VERSION ""

NS_ :

BS_:

BU_: WPC2 RLPSU DPSU APSU PSB SHVU_RR vHS_B2 FCS EMCU SLB ARS RCM CGW_CCU vDummy_HS_B ATS RLHV SGU PFSU ALBCU DSAU SWRC SHVU_FR RCS RRPSU BLTN_CAM SCM DLBCU OHCL RWPC RRHV WPC HOD ASAU

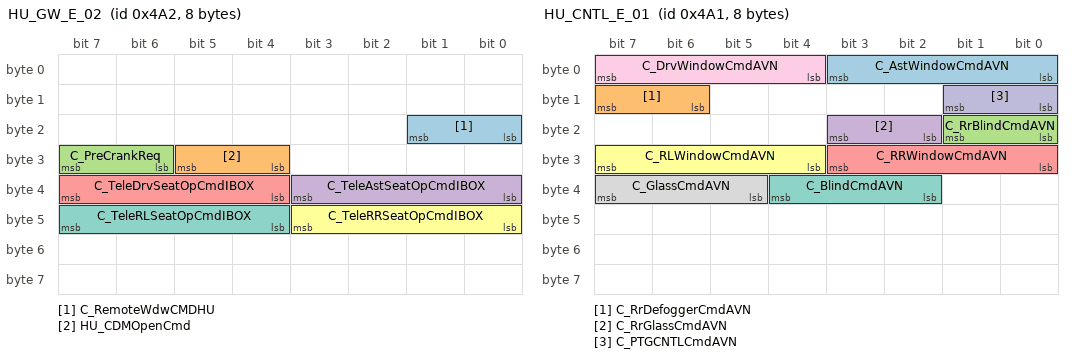
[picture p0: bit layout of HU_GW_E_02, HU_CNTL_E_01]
BO_ 1186 HU_GW_E_02: 8 CGW_CCU
 SG_ C_RemoteWdwCMDHU : 16|2@1+ (1,0) [0|0] ""  Vector__XXX
 SG_ HU_CDMOpenCmd : 28|2@1+ (1,0) [0|0] ""  Vector__XXX
 SG_ C_PreCrankReq : 30|2@1+ (1,0) [0|0] ""  BLTN_CAM
 SG_ C_TeleAstSeatOpCmdIBOX : 32|4@1+ (1,0) [0|0] ""  APSU,SHVU_FR
 SG_ C_TeleDrvSeatOpCmdIBOX : 36|4@1+ (1,0) [0|0] ""  SHVU_FR,DPSU
 SG_ C_TeleRRSeatOpCmdIBOX : 40|4@1+ (1,0) [0|0] ""  RRHV,SHVU_FR,SHVU_RR,RRPSU,RLPSU,ATS
 SG_ C_TeleRLSeatOpCmdIBOX : 44|4@1+ (1,0) [0|0] ""  RLHV,SHVU_FR,SHVU_RR,RRPSU,RLPSU,ATS

BO_ 1185 HU_CNTL_E_01: 8 CGW_CCU
 SG_ C_AstWindowCmdAVN : 0|4@1+ (1,0) [0|0] ""  Vector__XXX
 SG_ C_RrDefoggerCmdAVN : 14|2@1+ (1,0) [0|0] ""  Vector__XXX
 SG_ C_RrBlindCmdAVN : 16|2@1+ (1,0) [0|0] ""  RCM
 SG_ C_RrGlassCmdAVN : 18|2@1+ (1,0) [0|0] ""  RCM
 SG_ C_RRWindowCmdAVN : 24|4@1+ (1,0) [0|0] ""  Vector__XXX
 SG_ C_RLWindowCmdAVN : 28|4@1+ (1,0) [0|0] ""  Vector__XXX
 SG_ C_BlindCmdAVN : 34|3@1+ (1,0) [0|0] ""  RCM
 SG_ C_GlassCmdAVN : 37|3@1+ (1,0) [0|0] ""  RCM
 SG_ C_DrvWindowCmdAVN : 4|4@1+ (1,0) [0|0] ""  Vector__XXX
 SG_ C_PTGCNTLCmdAVN : 8|2@1+ (1,0) [0|0] ""  Vector__XXX

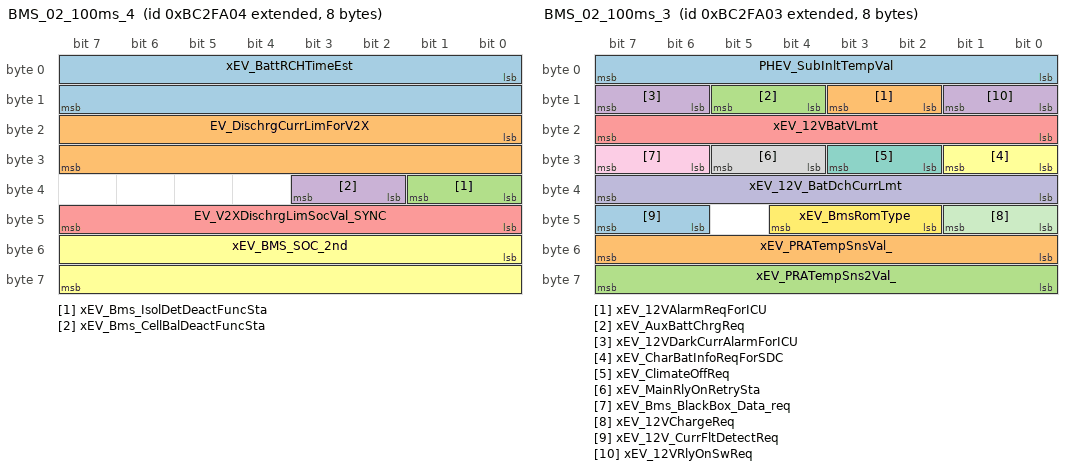
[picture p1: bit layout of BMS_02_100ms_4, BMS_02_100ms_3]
BO_ 2344811012 BMS_02_100ms_4: 8 CGW_CCU
 SG_ xEV_BattRCHTimeEst : 0|16@1+ (1,0) [0|0] "Min"  Vector__XXX
 SG_ EV_DischrgCurrLimForV2X : 16|16@1+ (0.1,0) [0|0] "A"  Vector__XXX
 SG_ xEV_Bms_IsolDetDeactFuncSta : 32|2@1+ (1,0) [0|0] "flg"  Vector__XXX
 SG_ xEV_Bms_CellBalDeactFuncSta : 34|2@1+ (1,0) [0|0] "flag"  Vector__XXX
 SG_ EV_V2XDischrgLimSocVal_SYNC : 40|8@1+ (0.5,0) [0|0] "%"  Vector__XXX
 SG_ xEV_BMS_SOC_2nd : 48|16@1+ (0.05,0) [0|0] "%"  Vector__XXX

BO_ 2344811011 BMS_02_100ms_3: 8 CGW_CCU
 SG_ PHEV_SubInltTempVal : 0|8@1- (1,0) [0|0] "¡É"  Vector__XXX
 SG_ xEV_12VAlarmReqForICU : 10|2@1+ (1,0) [0|0] ""  Vector__XXX
 SG_ xEV_AuxBattChrgReq : 12|2@1+ (1,0) [0|0] ""  Vector__XXX
 SG_ xEV_12VDarkCurrAlarmForICU : 14|2@1+ (1,0) [0|0] ""  Vector__XXX
 SG_ xEV_12VBatVLmt : 16|8@1+ (0.1,0) [0|0] "V"  Vector__XXX
 SG_ xEV_CharBatInfoReqForSDC : 24|2@1+ (1,0) [0|0] ""  Vector__XXX
 SG_ xEV_ClimateOffReq : 26|2@1+ (1,0) [0|0] ""  Vector__XXX
 SG_ xEV_MainRlyOnRetrySta : 28|2@1+ (1,0) [0|0] ""  Vector__XXX
 SG_ xEV_Bms_BlackBox_Data_req : 30|2@1+ (1,0) [0|0] ""  Vector__XXX
 SG_ xEV_12V_BatDchCurrLmt : 32|8@1+ (1,0) [0|0] "A"  Vector__XXX
 SG_ xEV_12VChargeReq : 40|2@1+ (1,0) [0|0] ""  Vector__XXX
 SG_ xEV_BmsRomType : 42|3@1+ (1,0) [0|0] ""  Vector__XXX
 SG_ xEV_12V_CurrFltDetectReq : 46|2@1+ (1,0) [0|0] ""  Vector__XXX
 SG_ xEV_PRATempSnsVal_ : 48|8@1- (2,0) [0|0] "¡É"  Vector__XXX
 SG_ xEV_PRATempSns2Val_ : 56|8@1- (2,0) [0|0] "¡É"  Vector__XXX
 SG_ xEV_12VRlyOnSwReq : 8|2@1+ (1,0) [0|0] ""  Vector__XXX

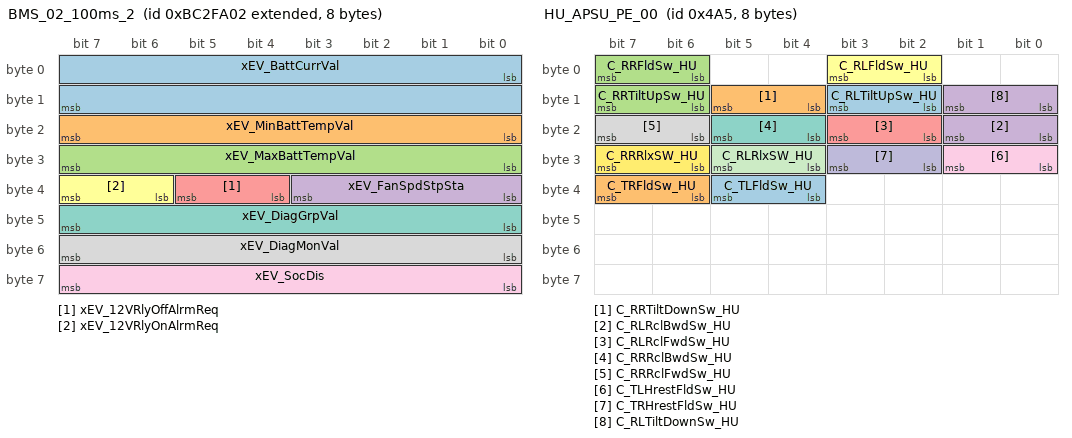
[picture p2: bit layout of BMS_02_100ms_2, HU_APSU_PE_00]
BO_ 2344811010 BMS_02_100ms_2: 8 CGW_CCU
 SG_ xEV_BattCurrVal : 0|16@1- (0.1,0) [0|0] "A"  Vector__XXX
 SG_ xEV_MinBattTempVal : 16|8@1- (1,0) [0|0] "¡É"  Vector__XXX
 SG_ xEV_MaxBattTempVal : 24|8@1- (1,0) [0|0] "¡É"  Vector__XXX
 SG_ xEV_FanSpdStpSta : 32|4@1+ (1,0) [0|0] "Step"  Vector__XXX
 SG_ xEV_12VRlyOffAlrmReq : 36|2@1+ (1,0) [0|0] ""  Vector__XXX
 SG_ xEV_12VRlyOnAlrmReq : 38|2@1+ (1,0) [0|0] ""  Vector__XXX
 SG_ xEV_DiagGrpVal : 40|8@1+ (1,0) [0|0] ""  Vector__XXX
 SG_ xEV_DiagMonVal : 48|8@1+ (1,0) [0|0] ""  Vector__XXX
 SG_ xEV_SocDis : 56|8@1+ (0.5,0) [0|0] "%"  SWRC

BO_ 1189 HU_APSU_PE_00: 8 CGW_CCU
 SG_ C_RLTiltUpSw_HU : 10|2@1+ (1,0) [0|0] ""  APSU,RRPSU,RLPSU
 SG_ C_RRTiltDownSw_HU : 12|2@1+ (1,0) [0|0] ""  APSU,RRPSU,RLPSU
 SG_ C_RRTiltUpSw_HU : 14|2@1+ (1,0) [0|0] ""  APSU,RRPSU,RLPSU
 SG_ C_RLRclBwdSw_HU : 16|2@1+ (1,0) [0|0] ""  APSU,RRPSU,RLPSU
 SG_ C_RLRclFwdSw_HU : 18|2@1+ (1,0) [0|0] ""  APSU,RRPSU,RLPSU
 SG_ C_RLFldSw_HU : 2|2@1+ (1,0) [0|0] ""  RLPSU
 SG_ C_RRRclBwdSw_HU : 20|2@1+ (1,0) [0|0] ""  APSU,RRPSU,RLPSU
 SG_ C_RRRclFwdSw_HU : 22|2@1+ (1,0) [0|0] ""  APSU,RRPSU,RLPSU
 SG_ C_TLHrestFldSw_HU : 24|2@1+ (1,0) [0|0] ""  PFSU
 SG_ C_TRHrestFldSw_HU : 26|2@1+ (1,0) [0|0] ""  PFSU
 SG_ C_RLRlxSW_HU : 28|2@1+ (1,0) [0|0] ""  RRPSU,RLPSU
 SG_ C_RRRlxSW_HU : 30|2@1+ (1,0) [0|0] ""  RRPSU
 SG_ C_TLFldSw_HU : 36|2@1+ (1,0) [0|0] ""  PFSU
 SG_ C_TRFldSw_HU : 38|2@1+ (1,0) [0|0] ""  PFSU
 SG_ C_RRFldSw_HU : 6|2@1+ (1,0) [0|0] ""  RRPSU
 SG_ C_RLTiltDownSw_HU : 8|2@1+ (1,0) [0|0] ""  APSU,RRPSU,RLPSU

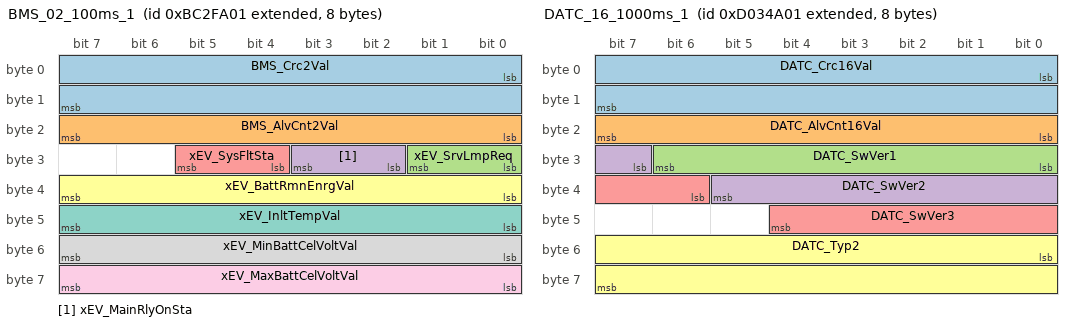
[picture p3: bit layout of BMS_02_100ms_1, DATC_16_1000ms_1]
BO_ 2344811009 BMS_02_100ms_1: 8 CGW_CCU
 SG_ BMS_Crc2Val : 0|16@1+ (1,0) [0|0] ""  Vector__XXX
 SG_ BMS_AlvCnt2Val : 16|8@1+ (1,0) [0|0] ""  Vector__XXX
 SG_ xEV_SrvLmpReq : 24|2@1+ (1,0) [0|0] ""  Vector__XXX
 SG_ xEV_MainRlyOnSta : 26|2@1+ (1,0) [0|0] ""  Vector__XXX
 SG_ xEV_SysFltSta : 28|2@1+ (1,0) [0|0] ""  Vector__XXX
 SG_ xEV_BattRmnEnrgVal : 32|8@1+ (1,0) [0|0] ""  Vector__XXX
 SG_ xEV_InltTempVal : 40|8@1- (1,0) [0|0] "¡É"  Vector__XXX
 SG_ xEV_MinBattCelVoltVal : 48|8@1+ (0.02,0) [0|0] "V"  Vector__XXX
 SG_ xEV_MaxBattCelVoltVal : 56|8@1+ (0.02,0) [0|0] "V"  Vector__XXX

BO_ 1195 HU_USM_E_04: 8 CGW_CCU
 SG_ CF_AVN_CluWelcomeSnd : 0|2@1+ (1,0) [0|0] ""  Vector__XXX
 SG_ CF_AVN_CluTransmissionDisp : 10|2@1+ (1,0) [0|0] ""  Vector__XXX
 SG_ CF_AVN_CluWiperLight : 12|2@1+ (1,0) [0|0] ""  Vector__XXX
 SG_ CF_AVN_CluRoadInfoGuide : 14|2@1+ (1,0) [0|0] ""  Vector__XXX
 SG_ CF_AVN_CluUserSettingPeriod : 17|7@1+ (1,0) [0|0] ""  Vector__XXX
 SG_ CF_AVN_CluAutoInitFuelEconomy : 2|3@1+ (1,0) [0|0] ""  Vector__XXX
 SG_ CF_AVN_CluFuelEconUnit_mi : 27|2@1+ (1,0) [0|0] ""  Vector__XXX
 SG_ CF_AVN_CluFuelEconUnit_km : 29|2@1+ (1,0) [0|0] ""  Vector__XXX
 SG_ CF_AVN_CluUserSettingDistance : 31|17@1+ (1,0) [0|0] ""  Vector__XXX
 SG_ CF_AVN_CluRheostatLvl : 49|5@1+ (1,0) [0|0] ""  Vector__XXX
 SG_ CF_AVN_CluVoiceVolume : 5|3@1+ (1,0) [0|0] ""  Vector__XXX
 SG_ CF_AVN_EVReset : 54|2@1+ (1,0) [0|0] ""  Vector__XXX
 SG_ CF_AVN_UnitReset : 56|2@1+ (1,0) [0|0] ""  Vector__XXX
 SG_ CF_AVN_IcyRoadWarn : 58|2@1+ (1,0) [0|0] ""  Vector__XXX
 SG_ CF_AVN_CluServiceReminderReset : 60|2@1+ (1,0) [0|0] ""  Vector__XXX
 SG_ CF_AVN_CluUSMReset : 62|2@1+ (1,0) [0|0] ""  WPC,RWPC,PSB,SLB,ARS,APSU,RLHV,RRHV,SHVU_FR,SHVU_RR,DPSU,DLBCU,PFSU,RRPSU,RLPSU,ATS,DSAU,ASAU,RCM,BLTN_CAM,ALBCU,WPC2
 SG_ CF_AVN_CluServiceReminderSet : 8|2@1+ (1,0) [0|0] ""  Vector__XXX

BO_ 1193 HU_USM_E_02: 8 CGW_CCU
 SG_ C_PTGMNValueSet : 0|2@1+ (1,0) [0|0] ""  Vector__XXX
 SG_ CF_AVN_PSMNValueSet : 10|3@1+ (1,0) [0|0] ""  DPSU
 SG_ C_HfreeTrunkTgNValueSet : 13|3@1+ (1,0) [0|0] ""  Vector__XXX
 SG_ CF_AVN_TrfChgSet : 17|2@1+ (1,0) [0|0] ""  Vector__XXX
 SG_ CF_AVN_SCMNValueSet : 19|2@1+ (1,0) [0|0] ""  Vector__XXX
 SG_ CF_AVN_ADrUNValueSet : 2|3@1+ (1,0) [0|0] ""  Vector__XXX
 SG_ CF_AVN_OTTurnNValueSet : 21|3@1+ (1,0) [0|0] ""  Vector__XXX
 SG_ CF_Gway_WPCNValueSet : 24|2@1+ (1,0) [0|0] ""  WPC,WPC2
 SG_ C_AVN_RearWiperNValueSet : 26|2@1+ (1,0) [0|0] ""  Vector__XXX
 SG_ C_UnlockWelocomeNValueSet : 28|2@1+ (1,0) [0|0] ""  Vector__XXX
 SG_ C_SmartWelocomeNValueSet : 30|2@1+ (1,0) [0|0] ""  Vector__XXX
 SG_ CF_AVN_PTGSpeedNValueSet : 32|2@1+ (1,0) [0|0] ""  Vector__XXX
 SG_ CR_Datc_DRSeatWheel_USM_Set : 34|2@1+ (1,0) [0|0] ""  Vector__XXX
 SG_ CF_AVN_TTUnlockNValueSet : 38|2@1+ (1,0) [0|0] ""  Vector__XXX
 SG_ CF_Gway_RWPCNValueSet : 40|2@1+ (1,0) [0|0] ""  RWPC
 SG_ C_PSDNValueSet : 44|2@1+ (1,0) [0|0] ""  Vector__XXX
 SG_ CF_Avn_HAPTICWARNINGNValueSet : 49|3@1+ (1,0) [0|0] ""  Vector__XXX
 SG_ CR_Datc_DRSeatHeat_USM_Set : 52|2@1+ (1,0) [0|0] ""  Vector__XXX
 SG_ C_WALNValueSet : 54|2@1+ (1,0) [0|0] ""  Vector__XXX
 SG_ C_ApprUnlockNValue : 56|2@1+ (1,0) [0|0] ""  Vector__XXX
 SG_ CF_AVN_EscortHLNValueSet : 8|2@1+ (1,0) [0|0] ""  Vector__XXX

BO_ 2365803012 DATC_16_1000ms_4: 8 CGW_CCU

BO_ 2365803011 DATC_16_1000ms_3: 8 CGW_CCU

BO_ 2365803010 DATC_16_1000ms_2: 8 CGW_CCU
 SG_ DATC_SwVer4 : 0|7@1+ (1,0) [0|0] ""  Vector__XXX
 SG_ DATC_SwVer5 : 7|7@1+ (1,0) [0|0] ""  Vector__XXX

BO_ 2365803009 DATC_16_1000ms_1: 8 CGW_CCU
 SG_ DATC_Crc16Val : 0|16@1+ (1,0) [0|0] ""  Vector__XXX
 SG_ DATC_AlvCnt16Val : 16|8@1+ (1,0) [0|0] ""  Vector__XXX
 SG_ DATC_SwVer1 : 24|7@1+ (1,0) [0|0] ""  Vector__XXX
 SG_ DATC_SwVer2 : 31|7@1+ (1,0) [0|0] ""  Vector__XXX
 SG_ DATC_SwVer3 : 38|7@1+ (1,0) [0|0] ""  Vector__XXX
 SG_ DATC_Typ2 : 48|16@1+ (1,0) [0|0] ""  ATS

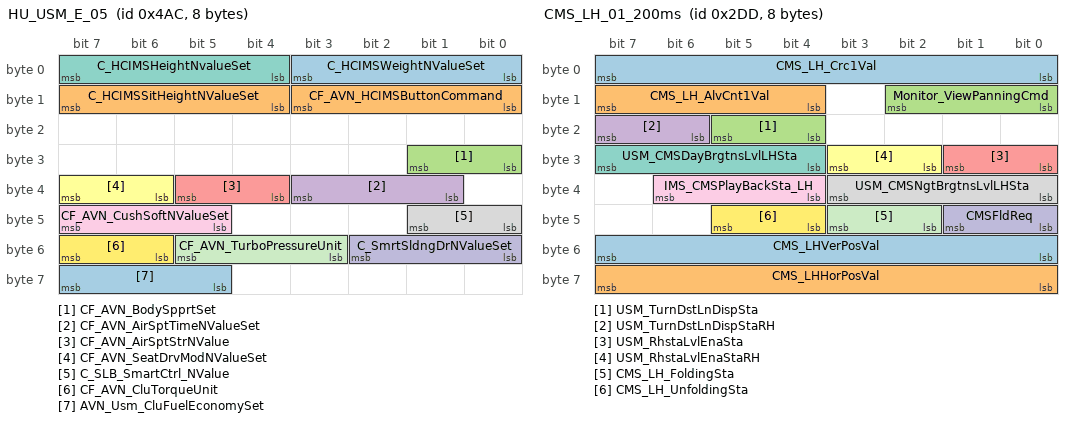
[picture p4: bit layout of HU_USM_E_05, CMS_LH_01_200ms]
BO_ 1196 HU_USM_E_05: 8 CGW_CCU
 SG_ C_HCIMSWeightNValueSet : 0|4@1+ (1,0) [0|0] ""  DPSU
 SG_ C_HCIMSSitHeightNValueSet : 12|4@1+ (1,0) [0|0] ""  DPSU
 SG_ CF_AVN_BodySpprtSet : 24|2@1+ (1,0) [0|0] ""  DLBCU,DSAU
 SG_ CF_AVN_AirSptTimeNValueSet : 33|3@1+ (1,0) [0|0] ""  DLBCU
 SG_ CF_AVN_AirSptStrNValue : 36|2@1+ (1,0) [0|0] ""  DLBCU
 SG_ CF_AVN_SeatDrvModNValueSet : 38|2@1+ (1,0) [0|0] ""  DLBCU,DSAU
 SG_ C_HCIMSHeightNvalueSet : 4|4@1+ (1,0) [0|0] ""  DPSU
 SG_ C_SLB_SmartCtrl_NValue : 40|2@1+ (1,0) [0|0] ""  Vector__XXX
 SG_ CF_AVN_CushSoftNValueSet : 45|3@1+ (1,0) [0|0] ""  DLBCU
 SG_ C_SmrtSldngDrNValueSet : 48|3@1+ (1,0) [0|0] ""  Vector__XXX
 SG_ CF_AVN_TurboPressureUnit : 51|3@1+ (1,0) [0|0] ""  Vector__XXX
 SG_ CF_AVN_CluTorqueUnit : 54|2@1+ (1,0) [0|0] ""  Vector__XXX
 SG_ AVN_Usm_CluFuelEconomySet : 61|3@1+ (1,0) [0|0] ""  Vector__XXX
 SG_ CF_AVN_HCIMSButtonCommand : 8|4@1+ (1,0) [0|0] ""  DPSU

BO_ 255 BCM_20_200ms: 8 CGW_CCU
 SG_ BCM_Crc20Val : 0|8@1+ (1,0) [0|0] ""  Vector__XXX
 SG_ BCM_AlvCnt20Val : 12|4@1+ (1,0) [0|0] ""  Vector__XXX
 SG_ BckGls_RrGlsHtdOnCmd : 16|2@1+ (1,0) [0|0] ""  Vector__XXX
 SG_ Wndshld_FrtGlsHtdOnCmd : 18|2@1+ (1,0) [0|0] ""  Vector__XXX
 SG_ Mirror_MirFldOpt : 20|2@1+ (1,0) [0|0] ""  Vector__XXX
 SG_ Window_AsstPwrWdwSunroofEnblSta : 22|2@1+ (1,0) [0|0] ""  RCM
 SG_ Window_RrPwrWdwEnblSta : 24|2@1+ (1,0) [0|0] ""  Vector__XXX
 SG_ Window_RrPwrWdwLkInd : 26|2@1+ (1,0) [0|0] ""  Vector__XXX
 SG_ Window_DrvPwrWdwCmd : 28|2@1+ (1,0) [0|0] ""  Vector__XXX
 SG_ Window_AsstPwrWdwCmd : 30|2@1+ (1,0) [0|0] ""  Vector__XXX
 SG_ Window_RrLftPwrWdwCmd : 32|2@1+ (1,0) [0|0] ""  Vector__XXX
 SG_ Window_RrRtPwrWdwCmd : 34|2@1+ (1,0) [0|0] ""  Vector__XXX
 SG_ Mirror_FldUnfldCmd : 36|2@1+ (1,0) [0|0] ""  Vector__XXX
 SG_ Mirror_FldCtrlSta : 38|2@1+ (1,0) [0|0] ""  Vector__XXX
 SG_ Mirror_UnFldCtrlSta : 40|2@1+ (1,0) [0|0] ""  Vector__XXX
 SG_ Mirror_PosMnlCmd : 42|3@1+ (1,0) [0|0] ""  Vector__XXX
 SG_ Mirror_SelSwIndCmd : 45|3@1+ (1,0) [0|0] ""  Vector__XXX
 SG_ BCM_SafetyWdwOptTyp2 : 49|3@1+ (1,0) [0|0] ""  Vector__XXX
 SG_ Mirror_LHOSMirPlyBckSta : 52|4@1+ (1,0) [0|0] ""  DPSU
 SG_ Mirror_RHOSMirPlyBckSta : 56|4@1+ (1,0) [0|0] ""  DPSU
 SG_ Mirror_SelSwSta : 60|3@1+ (1,0) [0|0] ""  Vector__XXX
 SG_ BckGls_RrGlsHtdOpt : 8|2@1+ (1,0) [0|0] ""  Vector__XXX

BO_ 733 CMS_LH_01_200ms: 8 CGW_CCU
 SG_ CMS_LH_Crc1Val : 0|8@1+ (1,0) [0|0] ""  Vector__XXX
 SG_ CMS_LH_AlvCnt1Val : 12|4@1+ (1,0) [0|0] ""  Vector__XXX
 SG_ USM_TurnDstLnDispSta : 20|2@1+ (1,0) [0|0] ""  Vector__XXX
 SG_ USM_TurnDstLnDispStaRH : 22|2@1+ (1,0) [0|0] ""  Vector__XXX
 SG_ USM_RhstaLvlEnaSta : 24|2@1+ (1,0) [0|0] ""  Vector__XXX
 SG_ USM_RhstaLvlEnaStaRH : 26|2@1+ (1,0) [0|0] ""  Vector__XXX
 SG_ USM_CMSDayBrgtnsLvlLHSta : 28|4@1+ (1,0) [0|0] ""  Vector__XXX
 SG_ USM_CMSNgtBrgtnsLvlLHSta : 32|4@1+ (1,0) [0|0] ""  Vector__XXX
 SG_ IMS_CMSPlayBackSta_LH : 36|3@1+ (1,0) [0|0] ""  DPSU
 SG_ CMSFldReq : 40|2@1+ (1,0) [0|0] ""  Vector__XXX
 SG_ CMS_LH_FoldingSta : 42|2@1+ (1,0) [0|0] ""  Vector__XXX
 SG_ CMS_LH_UnfoldingSta : 44|2@1+ (1,0) [0|0] ""  Vector__XXX
 SG_ CMS_LHVerPosVal : 48|8@1+ (0.02,0) [0|0] "V"  Vector__XXX
 SG_ CMS_LHHorPosVal : 56|8@1+ (0.02,0) [0|0] "V"  Vector__XXX
 SG_ Monitor_ViewPanningCmd : 8|3@1+ (1,0) [0|0] ""  Vector__XXX

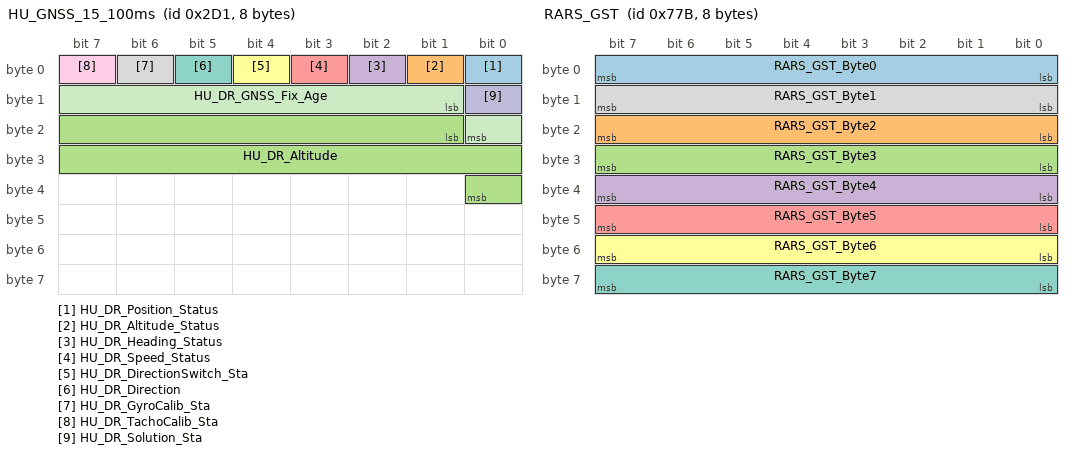
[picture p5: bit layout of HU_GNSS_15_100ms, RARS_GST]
BO_ 721 HU_GNSS_15_100ms: 8 CGW_CCU
 SG_ HU_DR_Position_Status : 0|1@1+ (1,0) [0|0] ""  Vector__XXX
 SG_ HU_DR_Altitude_Status : 1|1@1+ (1,0) [0|0] ""  Vector__XXX
 SG_ HU_DR_Altitude : 17|16@1- (1,0) [0|0] "m"  BLTN_CAM
 SG_ HU_DR_Heading_Status : 2|1@1+ (1,0) [0|0] ""  Vector__XXX
 SG_ HU_DR_Speed_Status : 3|1@1+ (1,0) [0|0] ""  Vector__XXX
 SG_ HU_DR_DirectionSwitch_Sta : 4|1@1+ (1,0) [0|0] ""  Vector__XXX
 SG_ HU_DR_Direction : 5|1@1+ (1,0) [0|0] ""  Vector__XXX
 SG_ HU_DR_GyroCalib_Sta : 6|1@1+ (1,0) [0|0] ""  Vector__XXX
 SG_ HU_DR_TachoCalib_Sta : 7|1@1+ (1,0) [0|0] ""  Vector__XXX
 SG_ HU_DR_Solution_Sta : 8|1@1+ (1,0) [0|0] ""  Vector__XXX
 SG_ HU_DR_GNSS_Fix_Age : 9|8@1+ (1,0) [0|0] "Sec"  Vector__XXX

BO_ 722 HU_GNSS_16_100ms: 8 CGW_CCU
 SG_ HU_DR_Latitude : 0|32@1- (1,0) [0|0] "¢ª"  BLTN_CAM
 SG_ HU_DR_Longitude : 32|32@1- (1,0) [0|0] "¢ª"  BLTN_CAM

BO_ 723 HU_GNSS_17_100ms: 8 CGW_CCU
 SG_ HU_DR_Heading : 0|16@1+ (1,0) [0|0] "¢ª"  BLTN_CAM
 SG_ HU_DR_Speed : 16|16@1- (0.01,0) [0|0] "m/s"  Vector__XXX

BO_ 1915 RARS_GST: 8 ARS
 SG_ RARS_GST_Byte0 : 0|8@1+ (1,0) [0|0] ""  CGW_CCU
 SG_ RARS_GST_Byte2 : 16|8@1+ (1,0) [0|0] ""  CGW_CCU
 SG_ RARS_GST_Byte3 : 24|8@1+ (1,0) [0|0] ""  CGW_CCU
 SG_ RARS_GST_Byte4 : 32|8@1+ (1,0) [0|0] ""  CGW_CCU
 SG_ RARS_GST_Byte5 : 40|8@1+ (1,0) [0|0] ""  CGW_CCU
 SG_ RARS_GST_Byte6 : 48|8@1+ (1,0) [0|0] ""  CGW_CCU
 SG_ RARS_GST_Byte7 : 56|8@1+ (1,0) [0|0] ""  CGW_CCU
 SG_ RARS_GST_Byte1 : 8|8@1+ (1,0) [0|0] ""  CGW_CCU

BO_ 273 ARS_04_00ms: 8 ARS
 SG_ ARS_RrCurtainBtn : 0|2@1+ (1,0) [0|0] ""  Vector__XXX

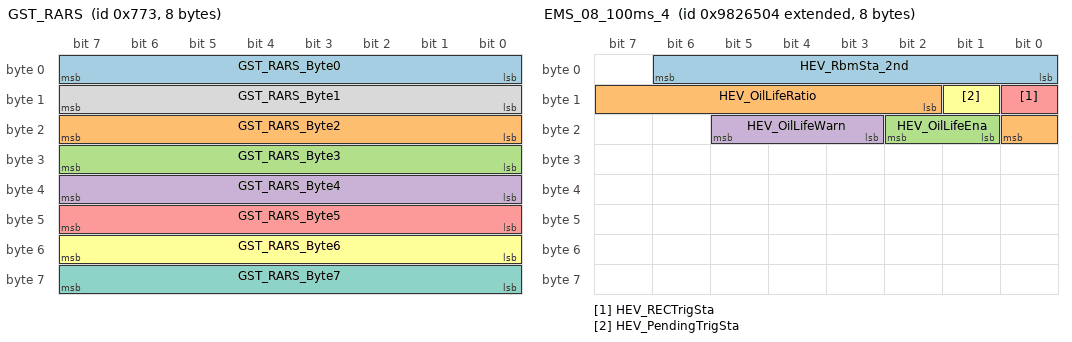
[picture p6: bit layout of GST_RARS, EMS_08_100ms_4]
BO_ 1907 GST_RARS: 8 CGW_CCU
 SG_ GST_RARS_Byte0 : 0|8@1+ (1,0) [0|0] ""  ARS
 SG_ GST_RARS_Byte2 : 16|8@1+ (1,0) [0|0] ""  ARS
 SG_ GST_RARS_Byte3 : 24|8@1+ (1,0) [0|0] ""  ARS
 SG_ GST_RARS_Byte4 : 32|8@1+ (1,0) [0|0] ""  ARS
 SG_ GST_RARS_Byte5 : 40|8@1+ (1,0) [0|0] ""  ARS
 SG_ GST_RARS_Byte6 : 48|8@1+ (1,0) [0|0] ""  ARS
 SG_ GST_RARS_Byte7 : 56|8@1+ (1,0) [0|0] ""  ARS
 SG_ GST_RARS_Byte1 : 8|8@1+ (1,0) [0|0] ""  ARS

BO_ 2307024132 EMS_08_100ms_4: 8 CGW_CCU
 SG_ HEV_RbmSta_2nd : 0|7@1+ (1,0) [0|0] ""  Vector__XXX
 SG_ HEV_OilLifeRatio : 10|7@1+ (1,0) [0|0] "%"  Vector__XXX
 SG_ HEV_OilLifeEna : 17|2@1+ (1,0) [0|0] ""  Vector__XXX
 SG_ HEV_OilLifeWarn : 19|3@1+ (1,0) [0|0] ""  Vector__XXX
 SG_ HEV_RECTrigSta : 8|1@1+ (1,0) [0|0] ""  Vector__XXX
 SG_ HEV_PendingTrigSta : 9|1@1+ (1,0) [0|0] ""  Vector__XXX

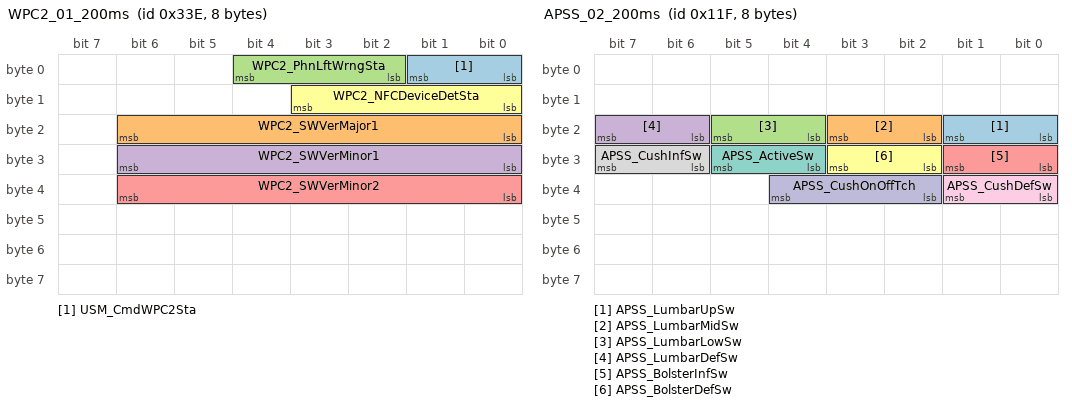
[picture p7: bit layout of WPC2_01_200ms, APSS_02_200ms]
BO_ 830 WPC2_01_200ms: 8 WPC2
 SG_ USM_CmdWPC2Sta : 0|2@1+ (1,0) [0|0] ""  CGW_CCU
 SG_ WPC2_SWVerMajor1 : 16|7@1+ (1,0) [0|0] ""  CGW_CCU
 SG_ WPC2_PhnLftWrngSta : 2|3@1+ (1,0) [0|0] ""  CGW_CCU
 SG_ WPC2_SWVerMinor1 : 24|7@1+ (1,0) [0|0] ""  CGW_CCU
 SG_ WPC2_SWVerMinor2 : 32|7@1+ (1,0) [0|0] ""  CGW_CCU
 SG_ WPC2_NFCDeviceDetSta : 8|4@1+ (1,0) [0|0] ""  Vector__XXX

BO_ 287 APSS_02_200ms: 8 APSU
 SG_ APSS_LumbarUpSw : 16|2@1+ (1,0) [0|0] ""  ALBCU,CGW_CCU
 SG_ APSS_LumbarMidSw : 18|2@1+ (1,0) [0|0] ""  ALBCU,CGW_CCU
 SG_ APSS_LumbarLowSw : 20|2@1+ (1,0) [0|0] ""  ALBCU,CGW_CCU
 SG_ APSS_LumbarDefSw : 22|2@1+ (1,0) [0|0] ""  ALBCU,CGW_CCU
 SG_ APSS_BolsterInfSw : 24|2@1+ (1,0) [0|0] ""  ALBCU,CGW_CCU
 SG_ APSS_BolsterDefSw : 26|2@1+ (1,0) [0|0] ""  ALBCU,CGW_CCU
 SG_ APSS_ActiveSw : 28|2@1+ (1,0) [0|0] ""  ALBCU
 SG_ APSS_CushInfSw : 30|2@1+ (1,0) [0|0] ""  ALBCU
 SG_ APSS_CushDefSw : 32|2@1+ (1,0) [0|0] ""  ALBCU
 SG_ APSS_CushOnOffTch : 34|3@1+ (1,0) [0|0] ""  ALBCU

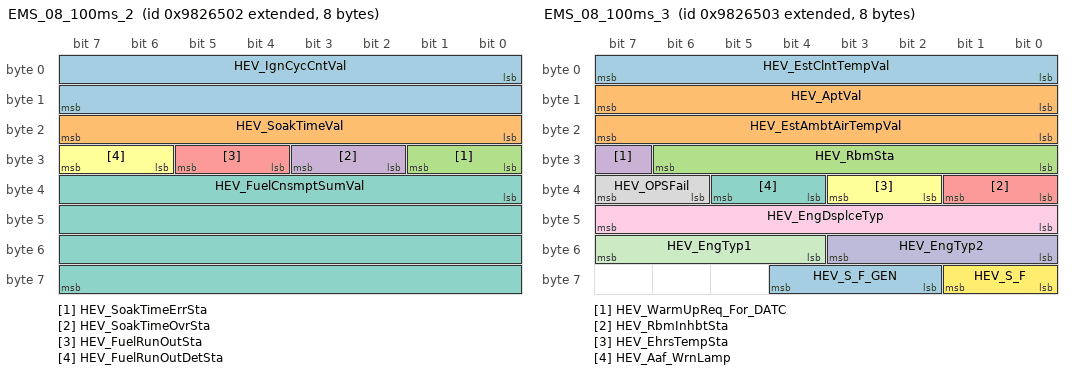
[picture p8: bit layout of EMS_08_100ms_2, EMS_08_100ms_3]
BO_ 2307024130 EMS_08_100ms_2: 8 CGW_CCU
 SG_ HEV_IgnCycCntVal : 0|16@1+ (1,0) [0|0] ""  Vector__XXX
 SG_ HEV_SoakTimeVal : 16|8@1+ (1,0) [0|0] "Min"  Vector__XXX
 SG_ HEV_SoakTimeErrSta : 24|2@1+ (1,0) [0|0] ""  Vector__XXX
 SG_ HEV_SoakTimeOvrSta : 26|2@1+ (1,0) [0|0] ""  Vector__XXX
 SG_ HEV_FuelRunOutSta : 28|2@1+ (1,0) [0|0] ""  Vector__XXX
 SG_ HEV_FuelRunOutDetSta : 30|2@1+ (1,0) [0|0] ""  Vector__XXX
 SG_ HEV_FuelCnsmptSumVal : 32|32@1+ (1.280018E-4,0) [0|0] "ml"  Vector__XXX

BO_ 2307024131 EMS_08_100ms_3: 8 CGW_CCU
 SG_ HEV_EstClntTempVal : 0|8@1+ (0.75,-48) [0|0] "¡É"  Vector__XXX
 SG_ HEV_EstAmbtAirTempVal : 16|8@1+ (0.75,-48) [0|0] "¡É"  Vector__XXX
 SG_ HEV_RbmSta : 24|7@1+ (1,0) [0|0] ""  Vector__XXX
 SG_ HEV_WarmUpReq_For_DATC : 31|1@1+ (1,0) [0|0] ""  Vector__XXX
 SG_ HEV_RbmInhbtSta : 32|2@1+ (1,0) [0|0] ""  Vector__XXX
 SG_ HEV_EhrsTempSta : 34|2@1+ (1,0) [0|0] ""  Vector__XXX
 SG_ HEV_Aaf_WrnLamp : 36|2@1+ (1,0) [0|0] ""  Vector__XXX
 SG_ HEV_OPSFail : 38|2@1+ (1,0) [0|0] ""  Vector__XXX
 SG_ HEV_EngDsplceTyp : 40|8@1+ (0.1,0) [0|0] "liter"  Vector__XXX
 SG_ HEV_EngTyp2 : 48|4@1+ (1,0) [0|0] ""  Vector__XXX
 SG_ HEV_EngTyp1 : 52|4@1+ (1,0) [0|0] ""  Vector__XXX
 SG_ HEV_S_F : 56|2@1+ (1,0) [0|0] ""  Vector__XXX
 SG_ HEV_S_F_GEN : 58|3@1+ (1,0) [0|0] ""  Vector__XXX
 SG_ HEV_AptVal : 8|8@1+ (2,0) [0|0] "PSI"  Vector__XXX

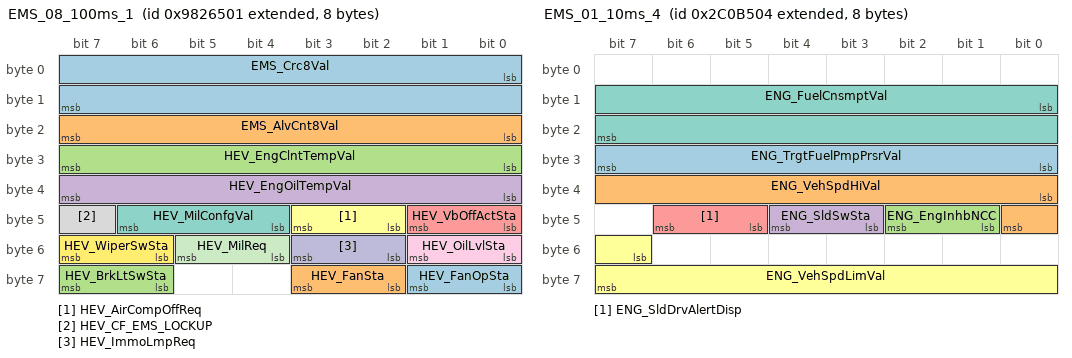
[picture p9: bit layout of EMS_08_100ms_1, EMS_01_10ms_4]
BO_ 2307024129 EMS_08_100ms_1: 8 CGW_CCU
 SG_ EMS_Crc8Val : 0|16@1+ (1,0) [0|0] ""  Vector__XXX
 SG_ EMS_AlvCnt8Val : 16|8@1+ (1,0) [0|0] ""  Vector__XXX
 SG_ HEV_EngClntTempVal : 24|8@1+ (0.75,-48) [0|0] "¡É"  Vector__XXX
 SG_ HEV_EngOilTempVal : 32|8@1+ (1,-40) [0|0] "¡É"  Vector__XXX
 SG_ HEV_VbOffActSta : 40|2@1+ (1,0) [0|0] ""  Vector__XXX
 SG_ HEV_AirCompOffReq : 42|2@1+ (1,0) [0|0] ""  Vector__XXX
 SG_ HEV_MilConfgVal : 44|3@1+ (1,0) [0|0] ""  Vector__XXX
 SG_ HEV_CF_EMS_LOCKUP : 47|1@1+ (1,0) [0|0] ""  Vector__XXX
 SG_ HEV_OilLvlSta : 48|2@1+ (1,0) [0|0] ""  Vector__XXX
 SG_ HEV_ImmoLmpReq : 50|2@1+ (1,0) [0|0] ""  Vector__XXX
 SG_ HEV_MilReq : 52|2@1+ (1,0) [0|0] ""  Vector__XXX
 SG_ HEV_WiperSwSta : 54|2@1+ (1,0) [0|0] ""  Vector__XXX
 SG_ HEV_FanOpSta : 56|2@1+ (1,0) [0|0] ""  Vector__XXX
 SG_ HEV_FanSta : 58|2@1+ (1,0) [0|0] ""  Vector__XXX
 SG_ HEV_BrkLtSwSta : 62|2@1+ (1,0) [0|0] ""  BLTN_CAM

BO_ 2193667332 EMS_01_10ms_4: 8 CGW_CCU
 SG_ ENG_TrgtFuelPmpPrsrVal : 24|8@1+ (3.137254902,0) [0|0] "kPa"  Vector__XXX
 SG_ ENG_VehSpdHiVal : 32|9@1+ (1,0) [0|0] "km/h"  Vector__XXX
 SG_ ENG_EngInhbNCC : 41|2@1+ (1,0) [0|0] ""  Vector__XXX
 SG_ ENG_SldSwSta : 43|2@1+ (1,0) [0|0] ""  Vector__XXX
 SG_ ENG_SldDrvAlertDisp : 45|2@1+ (1,0) [0|0] ""  Vector__XXX
 SG_ ENG_VehSpdLimVal : 55|9@1+ (1,0) [0|0] "km/h"  Vector__XXX
 SG_ ENG_FuelCnsmptVal : 8|16@1+ (0.128,0) [0|0] "ul"  Vector__XXX

BO_ 2193667331 EMS_01_10ms_3: 8 CGW_CCU
 SG_ ENG_TrgtIdleRpmVal : 0|8@1+ (10,0) [0|0] "rpm"  Vector__XXX
 SG_ ENG_GearShftDnDis : 10|2@1+ (1,0) [0|0] ""  Vector__XXX
 SG_ ENG_DsrGearPosDis : 12|4@1+ (1,0) [0|0] ""  Vector__XXX
 SG_ ENG_SldFuncSta : 16|2@1+ (1,0) [0|0] ""  Vector__XXX
 SG_ ENG_SldActnSta : 18|2@1+ (1,0) [0|0] ""  Vector__XXX
 SG_ ENG_FuelTnkPrsrSta : 20|2@1+ (1,0) [0|0] ""  Vector__XXX
 SG_ ENG_IsgBzrReq : 22|2@1+ (1,0) [0|0] ""  Vector__XXX
 SG_ ENG_IsgFuelCnsmptDis : 24|2@1+ (1,0) [0|0] ""  Vector__XXX
 SG_ ENG_FuelCapOpnSta : 26|2@1+ (1,0) [0|0] ""  Vector__XXX
 SG_ ENG_EcoDrvActvSta : 28|2@1+ (1,0) [0|0] ""  Vector__XXX
 SG_ ENG_EngRunSta : 30|2@1+ (1,0) [0|0] ""  Vector__XXX
 SG_ ENG_Isg2Sta : 32|2@1+ (2,0) [0|0] ""  Vector__XXX
 SG_ ENG_IgnOnSta : 34|2@1+ (1,0) [0|0] ""  Vector__XXX
 SG_ ENG_Ack4TcsSta : 36|2@1+ (1,0) [0|0] ""  Vector__XXX
 SG_ ENG_FuelCutOffSta : 38|2@1+ (1,0) [0|0] ""  Vector__XXX
 SG_ ENG_CrctTqSta : 40|2@1+ (1,0) [0|0] ""  Vector__XXX
 SG_ ENG_AirCompRlySta : 42|2@1+ (1,0) [0|0] ""  Vector__XXX
 SG_ ENG_LnchCntrlSta : 45|3@1+ (1,0) [0|0] ""  Vector__XXX
 SG_ ENG_EngSpdVal : 48|16@1+ (0.25,0) [0|0] "rpm"  EMCU
 SG_ ENG_GearShftUpDis : 8|2@1+ (1,0) [0|0] ""  Vector__XXX

CM_ BO_ 287 "[PE] Periodic and On Event";
CM_ SG_ 287 APSS_LumbarUpSw "APSS_LumbarUpMoveSwitch";
CM_ SG_ 287 APSS_LumbarMidSw "APSS_LumbarMiddleSwitch";
CM_ SG_ 287 APSS_LumbarLowSw "APSS_LumbarLowerSwitch";
CM_ SG_ 287 APSS_LumbarDefSw "APSS_LumbarDeflationSwitch";
CM_ SG_ 287 APSS_BolsterInfSw "APSS_BolsterInflationSwitch";
CM_ SG_ 287 APSS_BolsterDefSw "APSS_BolsterDeflationSwitch";
CM_ SG_ 287 APSS_ActiveSw "APSS_ActiveSwitch";
CM_ SG_ 287 APSS_CushInfSw "APSS_Cush Support Inflation Switch";
CM_ SG_ 287 APSS_CushDefSw "APSS_Cush Support Deflation Switch";
CM_ SG_ 287 APSS_CushOnOffTch "APSS_CushOnOffTouch";
CM_ BO_ 273 "[EC] On Event and On Change";
CM_ SG_ 273 ARS_RrCurtainBtn "Rear Curtain Button";
CM_ BO_ 255 "[PE] Periodic and On Event";
CM_ SG_ 255 BCM_Crc20Val "BCM_CyclicRedundancyCheck20Value";
CM_ SG_ 255 BCM_AlvCnt20Val "BCM_AliveCounter20Value";
CM_ SG_ 255 Mirror_MirFldOpt "Outside Mirror Electric Fold Option Signal";
CM_ SG_ 255 Mirror_FldUnfldCmd "Mirror Folding Unfolding Command";
CM_ SG_ 255 Mirror_FldCtrlSta "Mirror Fold and Folding Control State";
CM_ SG_ 255 Mirror_UnFldCtrlSta "Mirror Unfold and Unfolding Control State";
CM_ SG_ 255 Mirror_PosMnlCmd "Mirror Positioning Request";
CM_ SG_ 255 Mirror_SelSwIndCmd "Mirror Select Switch Indicator Command";
CM_ SG_ 255 Mirror_LHOSMirPlyBckSta "This siganl indicates Left O/S Mirror moving state for IMS From BDC";
CM_ SG_ 255 Mirror_RHOSMirPlyBckSta "This siganl indicates Right O/S Mirror moving state for IMS From BDC";
CM_ SG_ 255 Mirror_SelSwSta "Outside Mirror Select Button Status";
CM_ SG_ 255 BckGls_RrGlsHtdOpt "Back Glass_Rear Glass Heated Option Signal";
CM_ BO_ 2344811009 "[P] Periodic";
CM_ SG_ 2344811009 BMS_Crc2Val "BMS_CyclicRedundancyCheck2Value";
CM_ SG_ 2344811009 BMS_AlvCnt2Val "BMS_AliveCounter2Value";
CM_ SG_ 2344811009 xEV_SrvLmpReq "xEV_ServiceLampRequest";
CM_ SG_ 2344811009 xEV_MainRlyOnSta "xEV_MainRelayOnStatus";
CM_ SG_ 2344811009 xEV_SysFltSta "xEV_SystemFaultStatus";
CM_ SG_ 2344811009 xEV_BattRmnEnrgVal "xEV_BatteryRemainEnergyValue";
CM_ SG_ 2344811009 xEV_InltTempVal "xEV_InletTemperatureValue";
CM_ SG_ 2344811009 xEV_MinBattCelVoltVal "xEV_MinimumBatteryCellVoltageValue";
CM_ SG_ 2344811009 xEV_MaxBattCelVoltVal "xEV_MaximumBatteryCellVoltageValue";
CM_ BO_ 2344811010 "[P] Periodic";
CM_ SG_ 2344811010 xEV_BattCurrVal "xEV_BatteryCurrentValue";
CM_ SG_ 2344811010 xEV_MinBattTempVal "xEV_MinimumBatteryTemperatureValue";
CM_ SG_ 2344811010 xEV_MaxBattTempVal "xEV_MaximumBatteryTemperatureValue";
CM_ SG_ 2344811010 xEV_FanSpdStpSta "xEV_FanSpeedStepStatus";
CM_ SG_ 2344811010 xEV_12VRlyOffAlrmReq "xEV_12VRelayOffAlarmRequest";
CM_ SG_ 2344811010 xEV_12VRlyOnAlrmReq "xEV_12VRelayOnAlarmRequest";
CM_ SG_ 2344811010 xEV_DiagGrpVal "xEV_DiagnosticGroupValue";
CM_ SG_ 2344811010 xEV_DiagMonVal "xEV_DiagnosticMonitorValue";
CM_ SG_ 2344811010 xEV_SocDis "xEV_StateOfChargeDisplay";
CM_ BO_ 2344811011 "[P] Periodic";
CM_ SG_ 2344811011 PHEV_SubInltTempVal "PHEV_SubInletTemperatureValue";
CM_ SG_ 2344811011 xEV_12VAlarmReqForICU "xEV_12VBatteryAlarmRequestForICU";
CM_ SG_ 2344811011 xEV_AuxBattChrgReq "Aux. Battery Charge Request Flag";
CM_ SG_ 2344811011 xEV_12VDarkCurrAlarmForICU "xEV_12VDarkCurrentAlarmForICU";
CM_ SG_ 2344811011 xEV_12VBatVLmt "xEV_12VBatteryVoltageLimit";
CM_ SG_ 2344811011 xEV_CharBatInfoReqForSDC "xEV_ChargeBatteryInformationRequestForSDC";
CM_ SG_ 2344811011 xEV_ClimateOffReq "xEV_ClimateOffRequest";
CM_ SG_ 2344811011 xEV_MainRlyOnRetrySta "xEV_MainRelayONRetryStatus";
CM_ SG_ 2344811011 xEV_Bms_BlackBox_Data_req "For Saving BMS data set, this signal transmits to MCU";
CM_ SG_ 2344811011 xEV_12V_BatDchCurrLmt "xEV_12VBatteryDischargeCurrentLimit";
CM_ SG_ 2344811011 xEV_12VChargeReq "xEV_12V BatteryChargeRequest";
CM_ SG_ 2344811011 xEV_12V_CurrFltDetectReq "xEV_12VBatteryCurrentSensorFaultDetectRequest";
CM_ SG_ 2344811011 xEV_PRATempSnsVal_ "PRA Temperature #1 (Relay Busbar Temperature #1)";
CM_ SG_ 2344811011 xEV_PRATempSns2Val_ "PRA Temperature #2 (Relay Busbar Temperature #2)";
CM_ SG_ 2344811011 xEV_12VRlyOnSwReq "xEV_12VRelayOnSwitchRequest";
CM_ BO_ 2344811012 "[P] Periodic";
CM_ SG_ 2344811012 xEV_BattRCHTimeEst "calculated charging power by estimated output OBC power";
CM_ SG_ 2344811012 EV_DischrgCurrLimForV2X "Discharge Current Limit(for V2X)";
CM_ SG_ 2344811012 xEV_Bms_IsolDetDeactFuncSta "xEV_Isolation Detection Circuit Deactivate Function Status (GDS Function)";
CM_ SG_ 2344811012 xEV_Bms_CellBalDeactFuncSta "xEV_Cell Balancing Deactivate Function Status (GDS Function)";
CM_ SG_ 2344811012 EV_V2XDischrgLimSocVal_SYNC "Feedback SOC of  V2X discharge limitation for sync by BMS";
CM_ SG_ 2344811012 xEV_BMS_SOC_2nd "2nd SOC for NEV (Unit 0.05%)";
CM_ BO_ 733 "[PE] Periodic and On Event";
CM_ SG_ 733 CMS_LH_Crc1Val "CMS_LH_CyclicRedundancyCheck1Value";
CM_ SG_ 733 CMS_LH_AlvCnt1Val "CMS_LH_AliveCounter1Value";
CM_ SG_ 733 CMS_LHVerPosVal "LH Outside Mirror Vertical Position sensor value";
CM_ SG_ 733 CMS_LHHorPosVal "LH Outside Mirror Horizontal Position Sensor Voltage";
CM_ SG_ 733 Monitor_ViewPanningCmd "Monitor_ViewPanningCommand";
CM_ BO_ 2365803009 "[P] Periodic";
CM_ SG_ 2365803009 DATC_Crc16Val "DATC_CyclicRedundancyCheck16Value";
CM_ SG_ 2365803009 DATC_AlvCnt16Val "DATC_AliveCounter16Value";
CM_ SG_ 2365803009 DATC_SwVer1 "this signal indicates DATC Software Version to display on H_U";
CM_ SG_ 2365803009 DATC_SwVer2 "This signal indicates DATC software vertion to display on H_U";
CM_ SG_ 2365803009 DATC_Typ2 "DATC_Type2";
CM_ BO_ 2365803010 "[P] Periodic";
CM_ SG_ 2365803010 DATC_SwVer4 "this signal indicates DATC Detail Software Version";
CM_ SG_ 2365803010 DATC_SwVer5 "this signal indicates DATC Detail Software Version";
CM_ BO_ 2365803011 "[P] Periodic";
CM_ BO_ 2365803012 "[P] Periodic";
CM_ BO_ 2193667331 "[P] Periodic";
CM_ SG_ 2193667331 ENG_TrgtIdleRpmVal "ENG_TargetIdleRpmValue ##2G##EMS - EMS_H12 - R_NEngIdlTgC";
CM_ SG_ 2193667331 ENG_GearShftDnDis "ENG_GearShiftDownDisplay ##2G##EMS - EMS_H12 - CF_Ems_DownTarGr";
CM_ SG_ 2193667331 ENG_DsrGearPosDis "ENG_DesirableGearPositionDisplay ##2G##EMS - EMS_H12 - CF_Ems_DesCurGr";
CM_ SG_ 2193667331 ENG_SldFuncSta "ENG_SpeedLimitFunctionStatus ##2G##EMS - EMS_H12 - CF_Ems_SldAct";
CM_ SG_ 2193667331 ENG_SldActnSta "ENG_SpeedLimitActionStatus ##2G##EMS - EMS_H12 - CF_Ems_SldPosAct";
CM_ SG_ 2193667331 ENG_FuelTnkPrsrSta "ENG_FuelTankPressureStatus ##2G##EMS - EMS_H12 - CF_Ems_HPresStat";
CM_ SG_ 2193667331 ENG_IsgBzrReq "ENG_IsgBuzzerRequest ##2G##EMS - EMS_H12 - CF_Ems_IsgBuz";
CM_ SG_ 2193667331 ENG_IsgFuelCnsmptDis "ENG_IsgFuelConsumptionDisplay ##2G##EMS - EMS_H12 - CF_Ems_IdlStpFCO";
CM_ SG_ 2193667331 ENG_FuelCapOpnSta "ENG_FuelCapOpenStatus ##2G##EMS - EMS_H12 - CF_Ems_FCopen";
CM_ SG_ 2193667331 ENG_EcoDrvActvSta "ENG_EcoDriveActiveStatus ##2G##EMS - EMS_H12 - CF_Ems_ActEcoAct";
CM_ SG_ 2193667331 ENG_EngRunSta "ENG_EngineRunningStatus ##2G##EMS - EMS_H12 - CF_Ems_EngRunNorm";
CM_ SG_ 2193667331 ENG_Isg2Sta "ENG_Isg2Status ##2G##EMS - EMS_H12 - CF_Ems_IsgStat2";
CM_ SG_ 2193667331 ENG_IgnOnSta "ENG_IgnitionOnStatus ##2G##EMS - EMS11 - SWI_IGK";
CM_ SG_ 2193667331 ENG_Ack4TcsSta "ENG_AcknowledgeForTcsStatus ##2G##EMS - EMS11 - ACK_TCS";
CM_ SG_ 2193667331 ENG_FuelCutOffSta "ENG_FuelCutOffStatus ##2G##EMS - EMS11 - PUC_STAT";
CM_ SG_ 2193667331 ENG_CrctTqSta "ENG_CorrectedTorqueStatus ##2G##EMS - EMS11 - TQ_COR_STAT";
CM_ SG_ 2193667331 ENG_AirCompRlySta "ENG_AirCompressorRelayStatus ##2G##EMS - EMS11 - RLY_AC";
CM_ SG_ 2193667331 ENG_LnchCntrlSta "ENG_LaunchControlStatus";
CM_ SG_ 2193667331 ENG_EngSpdVal "ENG_EngineSpeedValue ##2G##EMS - EMS11 - N";
CM_ SG_ 2193667331 ENG_GearShftUpDis "ENG_GearShiftUpDisplay ##2G##EMS - EMS_H12 - CF_Ems_UpTarGr";
CM_ BO_ 2193667332 "[P] Periodic";
CM_ SG_ 2193667332 ENG_TrgtFuelPmpPrsrVal "ENG_TargetFuelPumpPressureValue ##2G##EMS - EMS20 - CF_Ems_PumpTPres";
CM_ SG_ 2193667332 ENG_VehSpdHiVal "ENG_VehicleSpeedHighValue";
CM_ SG_ 2193667332 ENG_EngInhbNCC "This signal indicates the Inhibition of NCC MODE";
CM_ SG_ 2193667332 ENG_SldSwSta "The status of Speed limiter function.";
CM_ SG_ 2193667332 ENG_SldDrvAlertDisp "The status of No Sld Engaged or Sld Disengaged.";
CM_ SG_ 2193667332 ENG_VehSpdLimVal "ENG_VehicleSpeedLimitValue ##2G##EMS - EMS_H12 - SLD_VS, EMS20-SLD_VS_EXT";
CM_ SG_ 2193667332 ENG_FuelCnsmptVal "ENG_FuelConsumptionValue ##2G##EMS - EMS20 - FCO";
CM_ BO_ 2307024129 "[P] Periodic";
CM_ SG_ 2307024129 EMS_Crc8Val "EMS_CyclicRedundancyCheck8Value";
CM_ SG_ 2307024129 EMS_AlvCnt8Val "EMS_AliveCounter8Value";
CM_ SG_ 2307024129 HEV_EngClntTempVal "HEV_EngineCoolantTemperatureValue";
CM_ SG_ 2307024129 HEV_EngOilTempVal "HEV_EngineOilTemperatureValue";
CM_ SG_ 2307024129 HEV_VbOffActSta "HEV_VbOffActStatus";
CM_ SG_ 2307024129 HEV_AirCompOffReq "HEV_AirCompressorOffRequest";
CM_ SG_ 2307024129 HEV_MilConfgVal "HEV_MilConfigurationValue";
CM_ SG_ 2307024129 HEV_CF_EMS_LOCKUP "Engine lock up mainentance request state";
CM_ SG_ 2307024129 HEV_OilLvlSta "HEV_OilLevelStatus";
CM_ SG_ 2307024129 HEV_ImmoLmpReq "HEV_ImmobilizerLampRequest";
CM_ SG_ 2307024129 HEV_MilReq "HEV_MalfunctionIndicationLampRequest";
CM_ SG_ 2307024129 HEV_WiperSwSta "HEV_WiperSwitchStatus";
CM_ SG_ 2307024129 HEV_FanOpSta "HEV_CoolingFanOperatingStatus";
CM_ SG_ 2307024129 HEV_FanSta "HEV_CoolingFanStatus";
CM_ SG_ 2307024129 HEV_BrkLtSwSta "HEV_BrakeLightSwitchStatus";
CM_ BO_ 2307024130 "[P] Periodic";
CM_ SG_ 2307024130 HEV_IgnCycCntVal "HEV_IgnitionCycleCounterValue";
CM_ SG_ 2307024130 HEV_SoakTimeVal "HEV_SoakTimeValue";
CM_ SG_ 2307024130 HEV_SoakTimeErrSta "HEV_SoakTimeErrorStatus";
CM_ SG_ 2307024130 HEV_SoakTimeOvrSta "HEV_SoakTimeOverStatus";
CM_ SG_ 2307024130 HEV_FuelRunOutSta "HEV_FuelRunOutStatus";
CM_ SG_ 2307024130 HEV_FuelRunOutDetSta "HEV_FuelRunOutDetectStatus";
CM_ SG_ 2307024130 HEV_FuelCnsmptSumVal "HEV_FuelConsumptionSumValue";
CM_ BO_ 2307024131 "[P] Periodic";
CM_ SG_ 2307024131 HEV_EstClntTempVal "HEV_EstimatedCoolantTemperatureValue";
CM_ SG_ 2307024131 HEV_EstAmbtAirTempVal "HEV_EstimatedAmbientAirTemperatureValue";
CM_ SG_ 2307024131 HEV_RbmSta "HEV_RateBasedMonitoringStatus";
CM_ SG_ 2307024131 HEV_WarmUpReq_For_DATC "HEV_WarmUpRequest";
CM_ SG_ 2307024131 HEV_RbmInhbtSta "HEV_RbmInhibitionStatus";
CM_ SG_ 2307024131 HEV_EhrsTempSta "HEV_EhrsTemperatureStatus";
CM_ SG_ 2307024131 HEV_Aaf_WrnLamp "Air Flap Warning Lamp/Message Request Signal indicates whether Warning Lamp/Message should be displayed in the display screen in order to warn AAF System failure to customer.";
CM_ SG_ 2307024131 HEV_OPSFail "Oil Pressure Warning Lamp Status";
CM_ SG_ 2307024131 HEV_EngDsplceTyp "HEV_EngineDisplacementType ##2G##EMS - EMS12 - ENG_VOL";
CM_ SG_ 2307024131 HEV_EngTyp2 "HEV_EngineType2 ##2G##EMS - EMS23 - ENG_TYPE";
CM_ SG_ 2307024131 HEV_EngTyp1 "HEV_EngineType1 ##2G##EMS - EMS12 - ENG_CHR";
CM_ SG_ 2307024131 HEV_S_F "AMS/ISG system type indicator";
CM_ SG_ 2307024131 HEV_S_F_GEN "system generation type indicator";
CM_ SG_ 2307024131 HEV_AptVal "HEV_AptValue";
CM_ BO_ 2307024132 "[P] Periodic";
CM_ SG_ 2307024132 HEV_RbmSta_2nd "HEV_RateBasedMonitoringStatus";
CM_ SG_ 2307024132 HEV_OilLifeRatio "Remaining engine oil life with % unit";
CM_ SG_ 2307024132 HEV_OilLifeEna "Enabling information if engine oil life monitoring from EMS is applied or not";
CM_ SG_ 2307024132 HEV_OilLifeWarn "Request to activate engine oil life warning";
CM_ SG_ 2307024132 HEV_RECTrigSta "VCRM trigger bit by REC";
CM_ SG_ 2307024132 HEV_PendingTrigSta "VCRM trigger bit by pending DTC";
CM_ BO_ 1907 "[TP] Transport Protocol";
CM_ BO_ 1189 "[PE] Periodic and On Event";
CM_ SG_ 1189 C_RLTiltUpSw_HU "2nd Left side seat Moving control : Tilt Up";
CM_ SG_ 1189 C_RRTiltDownSw_HU "2nd Right side seat Moving control : Tilt Down";
CM_ SG_ 1189 C_RRTiltUpSw_HU "2nd Right side seat Moving control : Tilt Up";
CM_ SG_ 1189 C_RLRclBwdSw_HU "2nd Left side seat Moving control :Recline Backward";
CM_ SG_ 1189 C_RLRclFwdSw_HU "2nd Left side seat Moving control : Recline Forward";
CM_ SG_ 1189 C_RLFldSw_HU "2nd Left side seat folding control : Folding";
CM_ SG_ 1189 C_RRRclBwdSw_HU "2nd Right side seat Moving control :Recline Backward";
CM_ SG_ 1189 C_RRRclFwdSw_HU "2nd Right side seat Moving control :Recline Forward";
CM_ SG_ 1189 C_TLHrestFldSw_HU "3rdLeft side seat Headrest folding control : Folding";
CM_ SG_ 1189 C_TRHrestFldSw_HU "3rd Right side seat Headrest folding control : Folding";
CM_ SG_ 1189 C_RLRlxSW_HU "2nd Left side seat Moving control : Relax mode";
CM_ SG_ 1189 C_RRRlxSW_HU "2nd Right side seat Moving control : Relax mode";
CM_ SG_ 1189 C_TLFldSw_HU "3rd Left side seat folding control : Folding";
CM_ SG_ 1189 C_TRFldSw_HU "3rd Right side seat folding control : Folding";
CM_ SG_ 1189 C_RRFldSw_HU "2nd Right side seat folding control : Folding";
CM_ SG_ 1189 C_RLTiltDownSw_HU "2nd Left side seat Moving control : Tilt Down";
CM_ BO_ 1185 "[EC] On Event and On Change";
CM_ SG_ 1185 C_AstWindowCmdAVN "This signal indicates AST Window Open/Close Command";
CM_ SG_ 1185 C_RrDefoggerCmdAVN "This signal indicates Rear Defogger Button Command";
CM_ SG_ 1185 C_RRWindowCmdAVN "This signal indicates RR Window Open/Close Command";
CM_ SG_ 1185 C_RLWindowCmdAVN "This signal indicates RL Window Open/Close Command";
CM_ SG_ 1185 C_BlindCmdAVN "This signal indicates Sunroof Blind Open/Close Command";
CM_ SG_ 1185 C_GlassCmdAVN "This signal indicates Sunroof Glass Open/Close Command";
CM_ SG_ 1185 C_DrvWindowCmdAVN "This signal indicates DRV Window Open/Close Command";
CM_ SG_ 1185 C_PTGCNTLCmdAVN "This signal indicates PowerTailgate Open/Close  Command";
CM_ BO_ 721 "[P] Periodic";
CM_ SG_ 721 HU_DR_Position_Status "DR Position status";
CM_ SG_ 721 HU_DR_Altitude_Status "DR Altitude Status";
CM_ SG_ 721 HU_DR_Altitude "range [-400,10000]";
CM_ SG_ 721 HU_DR_Heading_Status "DR Heading Status";
CM_ SG_ 721 HU_DR_Speed_Status "DR Speed status";
CM_ SG_ 721 HU_DR_DirectionSwitch_Sta "DR DirectionSwitch Status";
CM_ SG_ 721 HU_DR_Direction "DR Direction, Backward";
CM_ SG_ 721 HU_DR_GyroCalib_Sta "DR Gyro Calibration Status";
CM_ SG_ 721 HU_DR_TachoCalib_Sta "DR Tacho Calibration Status";
CM_ SG_ 721 HU_DR_GNSS_Fix_Age "Time since last GNSS fix";
CM_ BO_ 722 "[P] Periodic";
CM_ SG_ 722 HU_DR_Latitude "1sc(semi-cicle)= pi rad=180  /   unit : 2^-31sc  /  range [-1/2~1/2] sc";
CM_ SG_ 722 HU_DR_Longitude "1sc(semi-circle)=pi rad=180 / unit:2^-31sc / range:[-1, 1]sc";
CM_ BO_ 723 "[P] Periodic";
CM_ SG_ 723 HU_DR_Heading "1sc(semi-circle)=pi rad=180 / unit=2^-15sc / range:[0,2]SC";
CM_ SG_ 723 HU_DR_Speed "unit : 1cm/s";
CM_ BO_ 1186 "[EC] On Event and On Change";
CM_ SG_ 1186 C_RemoteWdwCMDHU "Signal for control window (TMS), HI only";
CM_ SG_ 1186 HU_CDMOpenCmd "Command for CDM open/close";
CM_ SG_ 1186 C_PreCrankReq "Command for B-CAN wake up signal
(Need to send this signal before other remote commands)";
CM_ SG_ 1186 C_TeleAstSeatOpCmdIBOX "Command for Remote Seat Heat/Vent control (Passenger)";
CM_ SG_ 1186 C_TeleDrvSeatOpCmdIBOX "Command for Remote Seat Heat/Vent control (Driver)";
CM_ SG_ 1186 C_TeleRRSeatOpCmdIBOX "Command for Remote Seat Heat/Vent control (Rear Right)";
CM_ SG_ 1186 C_TeleRLSeatOpCmdIBOX "Command for Remote Seat Heat/Vent control (Rear Left)";
CM_ BO_ 1193 "[EC] On Event and On Change";
CM_ SG_ 1193 C_PTGMNValueSet "Request to set PTGM Mode";
CM_ SG_ 1193 CF_AVN_PSMNValueSet "This signal is used for a request to set the value of UMS Menus. This signal requests to set Seat Easy Access Mode. When this signal change, the message is sent 3 times.";
CM_ SG_ 1193 C_HfreeTrunkTgNValueSet "Request to set Smart Trunk/Tailgate Mode";
CM_ SG_ 1193 CF_AVN_TrfChgSet "This signal is used for a request to set the value of UMS Menus. This signal requests to set Traffic Change Mode. When this signal change, the message is sent 3 times.";
CM_ SG_ 1193 CF_AVN_SCMNValueSet "Request to set Steering Easy Access mode";
CM_ SG_ 1193 CF_AVN_ADrUNValueSet "Request to set Auto Door Unlock Mode";
CM_ SG_ 1193 CF_AVN_OTTurnNValueSet "This signal is used for a request current setting value of USM Menus. When this signal change, the message is sent 3 times.";
CM_ SG_ 1193 CF_Gway_WPCNValueSet "Request to set Wireless Phone Charging mode";
CM_ SG_ 1193 C_AVN_RearWiperNValueSet "Request to set Rear Wiper operation in reverse";
CM_ SG_ 1193 C_UnlockWelocomeNValueSet "Request to set Door Unlock Welcome Setting Option";
CM_ SG_ 1193 C_SmartWelocomeNValueSet "Request to set Smart Key Welcome Setting Option";
CM_ SG_ 1193 CF_AVN_PTGSpeedNValueSet "Setting Value For Power Tailgate Speed";
CM_ SG_ 1193 CR_Datc_DRSeatWheel_USM_Set "SteeringWheel USM Set";
CM_ SG_ 1193 CF_AVN_TTUnlockNValueSet "Setting Value for Two Turn Unlock";
CM_ SG_ 1193 CF_Gway_RWPCNValueSet "Rear Wireless Phone Charger ON/OFF Request";
CM_ SG_ 1193 C_PSDNValueSet "Request to set PSD Mode. USM request signal for setting Power Sliding Door.";
CM_ SG_ 1193 CF_Avn_HAPTICWARNINGNValueSet "USM request for Steering Wheel Haptic Warning";
CM_ SG_ 1193 CR_Datc_DRSeatHeat_USM_Set "Driver Seat Heat/Ventl USM Set";
CM_ SG_ 1193 C_WALNValueSet "USM Function for Walk Away Lock(WAL)";
CM_ SG_ 1193 C_ApprUnlockNValue "USM request for Approach Unlock";
CM_ SG_ 1193 CF_AVN_EscortHLNValueSet "Request to set Head Lamp Escort Option";
CM_ BO_ 1195 "[EC] On Event and On Change";
CM_ SG_ 1195 CF_AVN_CluWelcomeSnd "Request to set CLU welcome soun";
CM_ SG_ 1195 CF_AVN_CluTransmissionDisp "Request to set CLU transmission display";
CM_ SG_ 1195 CF_AVN_CluWiperLight "Request to set CLU wiper & light mode";
CM_ SG_ 1195 CF_AVN_CluRoadInfoGuide "Request to set CLU road info guidance";
CM_ SG_ 1195 CF_AVN_CluUserSettingPeriod "Request to set CLU sservice period set by user";
CM_ SG_ 1195 CF_AVN_CluAutoInitFuelEconomy "Request to set CLU auto initailizing fuel economy";
CM_ SG_ 1195 CF_AVN_CluFuelEconUnit_mi "Cluster setting status for cluster Fuel Economy Unit (mile)";
CM_ SG_ 1195 CF_AVN_CluFuelEconUnit_km "Cluster setting status for cluster Fuel Economy unit (km)";
CM_ SG_ 1195 CF_AVN_CluUserSettingDistance "Request to set CLU service distance set by user";
CM_ SG_ 1195 CF_AVN_CluRheostatLvl "Request to set CLU rheostat level";
CM_ SG_ 1195 CF_AVN_CluVoiceVolume "Request to set CLU Volume level";
CM_ SG_ 1195 CF_AVN_EVReset "Request to reset EV Service (0x1 : EV USM Reset)";
CM_ SG_ 1195 CF_AVN_UnitReset "Request to reset Unit setting";
CM_ SG_ 1195 CF_AVN_IcyRoadWarn "Request to set CLU icy road warning";
CM_ SG_ 1195 CF_AVN_CluServiceReminderReset "Request to reset CLU service reminder";
CM_ SG_ 1195 CF_AVN_CluUSMReset "Request to reset all USM service";
CM_ SG_ 1195 CF_AVN_CluServiceReminderSet "Request to set CLU service notification";
CM_ BO_ 1196 "[EC] On Event and On Change";
CM_ SG_ 1196 C_HCIMSWeightNValueSet "This signal is used for Healthcare IMS to input user's weight";
CM_ SG_ 1196 C_HCIMSSitHeightNValueSet "This signal is used for Healthcare IMS to input user's sitting height";
CM_ SG_ 1196 CF_AVN_BodySpprtSet "This signal is for the seat body support USM";
CM_ SG_ 1196 CF_AVN_AirSptTimeNValueSet "This signal is for the seat massage function time setting";
CM_ SG_ 1196 CF_AVN_AirSptStrNValue "This signal is for the seat massage intensity USM";
CM_ SG_ 1196 CF_AVN_SeatDrvModNValueSet "This signal is for the auto seat-drivemode user setting menu";
CM_ SG_ 1196 C_HCIMSHeightNvalueSet "This signal is used for Healthcare IMS to input user's height";
CM_ SG_ 1196 CF_AVN_CushSoftNValueSet "This signal is for the cushsoftness setting";
CM_ SG_ 1196 AVN_Usm_CluFuelEconomySet "RG3 ÀÌÈÄ ´ëÈ­¸é Å¬·¯½ºÅÍ Àû¿ë½Ã º» »ç¾çÀ¸·Î Æò±Õ¿¬ºñ ÀÚµ¿ ÃÊ±âÈ­ ±â´É Àû¿ë";
CM_ SG_ 1196 CF_AVN_HCIMSButtonCommand "User's input value in healthcare IMS mode";
CM_ BO_ 1915 "[TP] Transport Protocol";
CM_ BO_ 830 "[PE] Periodic and On Event";
CM_ SG_ 830 USM_CmdWPC2Sta "USM_CommandWPC2Status";
CM_ SG_ 830 WPC2_SWVerMajor1 "First Word(ASCII) in WPC2 S/W Ver";
CM_ SG_ 830 WPC2_PhnLftWrngSta "WPC2_PhoneLeftWarningStatus";
CM_ SG_ 830 WPC2_SWVerMinor1 "Second Word(ASCII) in WPC2 S/W Ver";
CM_ SG_ 830 WPC2_SWVerMinor2 "Third Word(ASCII) in WPC2 S/W Ver";
CM_ SG_ 830 WPC2_NFCDeviceDetSta "NFC Device on WPC2  detection status 
if NFC device is not on WPC2, then the pre-authetication would be canceled.";
BA_DEF_ BO_ "DiagState" ENUM "No","Yes" ;
BA_DEF_ BO_ "DiagResponse" ENUM "No","Yes" ;
BA_DEF_ BO_ "DiagRequest" ENUM "No","Yes" ;
BA_DEF_ BO_ "TpMessage" ENUM "No","Yes" ;
BA_DEF_ BO_ "UsrMsgIDSforwardDeviation" INT 0 100 ;
BA_DEF_ BO_ "UsrMsgIDSbackwardDeviation" INT 50 1000 ;
BA_DEF_ BO_ "GenMsgCycleTime" INT 0 2000 ;
BA_DEF_ BO_ "GenMsgStartDelayTime" INT 0 2000 ;
BA_DEF_ BO_ "GenMsgSendType" ENUM "Cyclic","NoMsgSendType" ;
BA_DEF_ BO_ "GenMsgCycleTimeFast" INT 0 500 ;
BA_DEF_ BO_ "GenMsgDelayTime" INT 0 20 ;
BA_DEF_ BO_ "GenMsgILSupport" ENUM "No","Yes" ;
BA_DEF_ BO_ "GenMsgNrOfRepetition" INT 0 3 ;
BA_DEF_ BO_ "NmMessage" ENUM "No","Yes" ;
BA_DEF_ BO_ "NWM-Botschaft" ENUM "No","Yes" ;
BA_DEF_ BO_ "TpTxIndex" INT 0 255 ;
BA_DEF_ BO_ "VFrameFormat" ENUM "StandardCAN","ExtendedCAN","reserved","reserved","reserved","reserved","reserved","reserved","reserved","reserved","reserved","reserved","reserved","reserved","StandardCAN_FD","ExtendedCAN_FD" ;
BA_DEF_ SG_ "UserSigValidity" ENUM "B+","ACC","IG","IG1","IG2","IG3","IG1 or IG2","IG1 or IG3","Undef" ;
BA_DEF_ SG_ "TimeoutValue" STRING ;
BA_DEF_ SG_ "UsrSigPurpose" ENUM "Undef","FN","DIAG","DIAG(Req)","DIAG(Res)","DIAG(Phy)","DEV","CCP(Req)","CCP(Res)","NM","TP" ;
BA_DEF_ SG_ "GenSigStartValue" INT 0 1215752192 ;
BA_DEF_ SG_ "NetworkRequest" ENUM "Yes","No" ;
BA_DEF_ SG_ "NetworkRequestHoldingTime" INT 0 65535 ;
BA_DEF_ SG_ "Description" STRING ;
BA_DEF_ SG_ "Version" STRING ;
BA_DEF_ SG_ "GenSigEnvVarType" ENUM "Int","Float","Undef" ;
BA_DEF_ SG_ "GenSigSendType" ENUM "Cyclic","OnWrite","OnWriteWithRepetition","OnChange","OnChangeWithRepetition","IfActive","IfActiveWithRepetition","NoSigSendType","OnChangeAndIfActive","OnChangeAndIfActiveWithRepetition" ;
BA_DEF_ SG_ "GwSigLatencyTime" INT 0 65536 ;
BA_DEF_ SG_ "GwSigMissingSourceType" ENUM "Undef","OldValue","DefaultValue","InitialValue" ;
BA_DEF_ SG_ "NWM-WakeupAllowed" ENUM "<n.a.>" ;
BA_DEF_ SG_ "RoutingFactor" INT 1 1215752192 ;
BA_DEF_REL_ BU_SG_REL_ "GenSigTimeoutTime" INT 0 7000 ;
BA_DEF_DEF_ "DiagState" "No" ;
BA_DEF_DEF_ "DiagResponse" "No" ;
BA_DEF_DEF_ "DiagRequest" "No" ;
BA_DEF_DEF_ "TpMessage" "No" ;
BA_DEF_DEF_ "UsrMsgIDSforwardDeviation" 10 ;
BA_DEF_DEF_ "UsrMsgIDSbackwardDeviation" 100 ;
BA_DEF_DEF_ "GenMsgCycleTime" 200 ;
BA_DEF_DEF_ "GenMsgStartDelayTime" 0 ;
BA_DEF_DEF_ "GenMsgSendType" "NoMsgSendType" ;
BA_DEF_DEF_ "GenMsgCycleTimeFast" 40 ;
BA_DEF_DEF_ "GenMsgDelayTime" 20 ;
BA_DEF_DEF_ "GenMsgILSupport" "Yes" ;
BA_DEF_DEF_ "GenMsgNrOfRepetition" 3 ;
BA_DEF_DEF_ "NmMessage" "No" ;
BA_DEF_DEF_ "NWM-Botschaft" "No" ;
BA_DEF_DEF_ "TpTxIndex" 0 ;
BA_DEF_DEF_ "VFrameFormat" "StandardCAN" ;
BA_DEF_DEF_ "UserSigValidity" "IG" ;
BA_DEF_DEF_ "TimeoutValue" "" ;
BA_DEF_DEF_ "UsrSigPurpose" "FN" ;
BA_DEF_DEF_ "GenSigStartValue" 0 ;
BA_DEF_DEF_ "NetworkRequest" "No" ;
BA_DEF_DEF_ "NetworkRequestHoldingTime" 0 ;
BA_DEF_DEF_ "Description" "" ;
BA_DEF_DEF_ "Version" "" ;
BA_DEF_DEF_ "GenSigEnvVarType" "Undef" ;
BA_DEF_DEF_ "GenSigSendType" "NoSigSendType" ;
BA_DEF_DEF_ "GwSigLatencyTime" 40 ;
BA_DEF_DEF_ "GwSigMissingSourceType" "Undef" ;
BA_DEF_DEF_ "NWM-WakeupAllowed" "<n.a.>" ;
BA_DEF_DEF_ "RoutingFactor" 1 ;
BA_DEF_DEF_REL_ "GenSigTimeoutTime" 500 ;
BA_ "GenMsgSendType" BO_ 287 0;
BA_ "Description" SG_ 287 APSS_LumbarUpSw "APSS_LumbarUpMoveSwitch";
BA_ "GenSigSendType" SG_ 287 APSS_LumbarUpSw 4;
BA_ "UserSigValidity" SG_ 287 APSS_LumbarUpSw 0;
BA_REL_ "GenSigTimeoutTime" BU_SG_REL_ ALBCU SG_ 287 APSS_LumbarUpSw 1500;
BA_REL_ "GenSigTimeoutTime" BU_SG_REL_ CGW_CCU SG_ 287 APSS_LumbarUpSw 1500;
BA_ "NetworkRequest" SG_ 287 APSS_LumbarUpSw 0;
BA_ "NetworkRequestHoldingTime" SG_ 287 APSS_LumbarUpSw 5000;
BA_ "Version" SG_ 287 APSS_LumbarUpSw "19.11.06";
BA_ "Description" SG_ 287 APSS_LumbarMidSw "APSS_LumbarMiddleSwitch";
BA_ "GenSigSendType" SG_ 287 APSS_LumbarMidSw 4;
BA_ "UserSigValidity" SG_ 287 APSS_LumbarMidSw 0;
BA_REL_ "GenSigTimeoutTime" BU_SG_REL_ ALBCU SG_ 287 APSS_LumbarMidSw 1500;
BA_REL_ "GenSigTimeoutTime" BU_SG_REL_ CGW_CCU SG_ 287 APSS_LumbarMidSw 1500;
BA_ "NetworkRequest" SG_ 287 APSS_LumbarMidSw 0;
BA_ "NetworkRequestHoldingTime" SG_ 287 APSS_LumbarMidSw 5000;
BA_ "Version" SG_ 287 APSS_LumbarMidSw "19.11.06";
BA_ "Description" SG_ 287 APSS_LumbarLowSw "APSS_LumbarLowerSwitch";
BA_ "GenSigSendType" SG_ 287 APSS_LumbarLowSw 4;
BA_ "UserSigValidity" SG_ 287 APSS_LumbarLowSw 0;
BA_REL_ "GenSigTimeoutTime" BU_SG_REL_ ALBCU SG_ 287 APSS_LumbarLowSw 1500;
BA_REL_ "GenSigTimeoutTime" BU_SG_REL_ CGW_CCU SG_ 287 APSS_LumbarLowSw 1500;
BA_ "NetworkRequest" SG_ 287 APSS_LumbarLowSw 0;
BA_ "NetworkRequestHoldingTime" SG_ 287 APSS_LumbarLowSw 5000;
BA_ "Version" SG_ 287 APSS_LumbarLowSw "19.11.06";
BA_ "Description" SG_ 287 APSS_LumbarDefSw "APSS_LumbarDeflationSwitch";
BA_ "GenSigSendType" SG_ 287 APSS_LumbarDefSw 4;
BA_ "UserSigValidity" SG_ 287 APSS_LumbarDefSw 0;
BA_REL_ "GenSigTimeoutTime" BU_SG_REL_ ALBCU SG_ 287 APSS_LumbarDefSw 1500;
BA_REL_ "GenSigTimeoutTime" BU_SG_REL_ CGW_CCU SG_ 287 APSS_LumbarDefSw 1500;
BA_ "NetworkRequest" SG_ 287 APSS_LumbarDefSw 0;
BA_ "NetworkRequestHoldingTime" SG_ 287 APSS_LumbarDefSw 5000;
BA_ "Version" SG_ 287 APSS_LumbarDefSw "19.11.06";
BA_ "Description" SG_ 287 APSS_BolsterInfSw "APSS_BolsterInflationSwitch";
BA_ "GenSigSendType" SG_ 287 APSS_BolsterInfSw 4;
BA_ "UserSigValidity" SG_ 287 APSS_BolsterInfSw 0;
BA_REL_ "GenSigTimeoutTime" BU_SG_REL_ ALBCU SG_ 287 APSS_BolsterInfSw 1500;
BA_REL_ "GenSigTimeoutTime" BU_SG_REL_ CGW_CCU SG_ 287 APSS_BolsterInfSw 1500;
BA_ "NetworkRequest" SG_ 287 APSS_BolsterInfSw 0;
BA_ "NetworkRequestHoldingTime" SG_ 287 APSS_BolsterInfSw 5000;
BA_ "Version" SG_ 287 APSS_BolsterInfSw "19.11.06";
BA_ "Description" SG_ 287 APSS_BolsterDefSw "APSS_BolsterDeflationSwitch";
BA_ "GenSigSendType" SG_ 287 APSS_BolsterDefSw 4;
BA_ "UserSigValidity" SG_ 287 APSS_BolsterDefSw 0;
BA_REL_ "GenSigTimeoutTime" BU_SG_REL_ ALBCU SG_ 287 APSS_BolsterDefSw 1500;
BA_REL_ "GenSigTimeoutTime" BU_SG_REL_ CGW_CCU SG_ 287 APSS_BolsterDefSw 1500;
BA_ "NetworkRequest" SG_ 287 APSS_BolsterDefSw 0;
BA_ "NetworkRequestHoldingTime" SG_ 287 APSS_BolsterDefSw 5000;
BA_ "Version" SG_ 287 APSS_BolsterDefSw "19.11.06";
BA_ "Description" SG_ 287 APSS_ActiveSw "Á¶¼ö¼® Äí¼Ç º¼½ºÅÍ Á¶Àý ½ºÀ§Ä¡";
BA_ "GenSigSendType" SG_ 287 APSS_ActiveSw 4;
BA_ "UserSigValidity" SG_ 287 APSS_ActiveSw 0;
BA_REL_ "GenSigTimeoutTime" BU_SG_REL_ ALBCU SG_ 287 APSS_ActiveSw 1500;
BA_ "NetworkRequest" SG_ 287 APSS_ActiveSw 0;
BA_ "NetworkRequestHoldingTime" SG_ 287 APSS_ActiveSw 5000;
BA_ "Version" SG_ 287 APSS_ActiveSw "20.11.02";
BA_ "Description" SG_ 287 APSS_CushInfSw "Á¶¼ö¼® Äí¼Ç°ø¾ÐÁ¶Àý Èí±â ¹öÆ°";
BA_ "GenSigSendType" SG_ 287 APSS_CushInfSw 4;
BA_ "UserSigValidity" SG_ 287 APSS_CushInfSw 0;
BA_REL_ "GenSigTimeoutTime" BU_SG_REL_ ALBCU SG_ 287 APSS_CushInfSw 1500;
BA_ "NetworkRequest" SG_ 287 APSS_CushInfSw 0;
BA_ "NetworkRequestHoldingTime" SG_ 287 APSS_CushInfSw 5000;
BA_ "Version" SG_ 287 APSS_CushInfSw "20.11.02";
BA_ "Description" SG_ 287 APSS_CushDefSw "Á¶¼ö¼® Äí¼Ç °ø¾Ð Á¶Àý ¹è±â ¹öÆ°";
BA_ "GenSigSendType" SG_ 287 APSS_CushDefSw 4;
BA_ "UserSigValidity" SG_ 287 APSS_CushDefSw 0;
BA_REL_ "GenSigTimeoutTime" BU_SG_REL_ ALBCU SG_ 287 APSS_CushDefSw 1500;
BA_ "NetworkRequest" SG_ 287 APSS_CushDefSw 0;
BA_ "NetworkRequestHoldingTime" SG_ 287 APSS_CushDefSw 5000;
BA_ "Version" SG_ 287 APSS_CushDefSw "20.11.02";
BA_ "Description" SG_ 287 APSS_CushOnOffTch "ÅÍÄ¡ ½ºÀ§Ä¡ Á¤º¸";
BA_ "GenSigSendType" SG_ 287 APSS_CushOnOffTch 4;
BA_ "UserSigValidity" SG_ 287 APSS_CushOnOffTch 3;
BA_REL_ "GenSigTimeoutTime" BU_SG_REL_ ALBCU SG_ 287 APSS_CushOnOffTch 1500;
BA_ "NetworkRequest" SG_ 287 APSS_CushOnOffTch 0;
BA_ "NetworkRequestHoldingTime" SG_ 287 APSS_CushOnOffTch 5000;
BA_ "Version" SG_ 287 APSS_CushOnOffTch "20.11.02";
BA_ "GenMsgCycleTime" BO_ 273 0;
BA_ "Description" SG_ 273 ARS_RrCurtainBtn "Rear Curtain Button";
BA_ "GenSigSendType" SG_ 273 ARS_RrCurtainBtn 4;
BA_ "UserSigValidity" SG_ 273 ARS_RrCurtainBtn 3;
BA_ "NetworkRequest" SG_ 273 ARS_RrCurtainBtn 0;
BA_ "NetworkRequestHoldingTime" SG_ 273 ARS_RrCurtainBtn 5000;
BA_ "Version" SG_ 273 ARS_RrCurtainBtn "22.02.05";
BA_ "GenMsgSendType" BO_ 255 0;
BA_ "Description" SG_ 255 BCM_Crc20Val "The data area for CRC calculation is based on the data length (DLC) of the message DB.

The CRC shall be calculated over the entire data block (excluding the CRC bytes) including the user data, alive counter and Data ID 

 

- CRC Polynomial (0x1D) , Initial Value : 0x00, XOR value : 0xFF, Data ID Mode : Both, Data ID : Message ID + 0xF800 

- The initial value is for CRC calculation and the message should be sent with the calculated result value. 

The mathematical expression to 8 bit CRC polynomial is given here. G(x) = x8 + x4 + x3 + x2 + 1";
BA_ "GenSigSendType" SG_ 255 BCM_Crc20Val 4;
BA_ "GenSigStartValue" SG_ 255 BCM_Crc20Val 255;
BA_ "UserSigValidity" SG_ 255 BCM_Crc20Val 0;
BA_ "Version" SG_ 255 BCM_Crc20Val "20.08.01";
BA_ "Description" SG_ 255 BCM_AlvCnt20Val "For the first transmission request for a data element the counter shall be initialized with 0 and shall be incremented by 1

for every subsequent send request. When the counter reaches the maximum value(0xE), then it shall restart with 0 for the next send request";
BA_ "GenSigSendType" SG_ 255 BCM_AlvCnt20Val 4;
BA_ "UserSigValidity" SG_ 255 BCM_AlvCnt20Val 0;
BA_ "Version" SG_ 255 BCM_AlvCnt20Val "20.08.01";
BA_ "Description" SG_ 255 BckGls_RrGlsHtdOnCmd "Rear Glass Heated Command";
BA_ "GenSigSendType" SG_ 255 BckGls_RrGlsHtdOnCmd 4;
BA_ "UserSigValidity" SG_ 255 BckGls_RrGlsHtdOnCmd 0;
BA_ "NetworkRequest" SG_ 255 BckGls_RrGlsHtdOnCmd 0;
BA_ "NetworkRequestHoldingTime" SG_ 255 BckGls_RrGlsHtdOnCmd 5000;
BA_ "Version" SG_ 255 BckGls_RrGlsHtdOnCmd "21.09.05";
BA_ "Description" SG_ 255 Wndshld_FrtGlsHtdOnCmd "Front Heated Glass Command";
BA_ "GenSigSendType" SG_ 255 Wndshld_FrtGlsHtdOnCmd 4;
BA_ "UserSigValidity" SG_ 255 Wndshld_FrtGlsHtdOnCmd 0;
BA_ "NetworkRequest" SG_ 255 Wndshld_FrtGlsHtdOnCmd 0;
BA_ "NetworkRequestHoldingTime" SG_ 255 Wndshld_FrtGlsHtdOnCmd 5000;
BA_ "Version" SG_ 255 Wndshld_FrtGlsHtdOnCmd "20.08.02";
BA_ "Description" SG_ 255 Mirror_MirFldOpt "Outside Mirror Electric Fold Option Signal";
BA_ "GenSigSendType" SG_ 255 Mirror_MirFldOpt 4;
BA_ "UserSigValidity" SG_ 255 Mirror_MirFldOpt 0;
BA_ "NetworkRequest" SG_ 255 Mirror_MirFldOpt 0;
BA_ "NetworkRequestHoldingTime" SG_ 255 Mirror_MirFldOpt 5000;
BA_ "Version" SG_ 255 Mirror_MirFldOpt "21.04.00";
BA_ "Description" SG_ 255 Window_AsstPwrWdwSunroofEnblSta "Assist Power Window And Sunroof Enable";
BA_ "GenSigSendType" SG_ 255 Window_AsstPwrWdwSunroofEnblSta 4;
BA_ "UserSigValidity" SG_ 255 Window_AsstPwrWdwSunroofEnblSta 0;
BA_REL_ "GenSigTimeoutTime" BU_SG_REL_ RCM SG_ 255 Window_AsstPwrWdwSunroofEnblSta 1500;
BA_ "NetworkRequest" SG_ 255 Window_AsstPwrWdwSunroofEnblSta 0;
BA_ "NetworkRequestHoldingTime" SG_ 255 Window_AsstPwrWdwSunroofEnblSta 5000;
BA_ "Version" SG_ 255 Window_AsstPwrWdwSunroofEnblSta "20.08.02";
BA_ "Description" SG_ 255 Window_RrPwrWdwEnblSta "Rear Power Window Enable";
BA_ "GenSigSendType" SG_ 255 Window_RrPwrWdwEnblSta 4;
BA_ "UserSigValidity" SG_ 255 Window_RrPwrWdwEnblSta 0;
BA_ "NetworkRequest" SG_ 255 Window_RrPwrWdwEnblSta 0;
BA_ "NetworkRequestHoldingTime" SG_ 255 Window_RrPwrWdwEnblSta 5000;
BA_ "Version" SG_ 255 Window_RrPwrWdwEnblSta "20.08.02";
BA_ "Description" SG_ 255 Window_RrPwrWdwLkInd "RearPpower Window Lock Indicator Command";
BA_ "GenSigSendType" SG_ 255 Window_RrPwrWdwLkInd 4;
BA_ "UserSigValidity" SG_ 255 Window_RrPwrWdwLkInd 0;
BA_ "NetworkRequest" SG_ 255 Window_RrPwrWdwLkInd 0;
BA_ "NetworkRequestHoldingTime" SG_ 255 Window_RrPwrWdwLkInd 5000;
BA_ "Version" SG_ 255 Window_RrPwrWdwLkInd "20.08.02";
BA_ "Description" SG_ 255 Window_DrvPwrWdwCmd "Driver Power Window Command";
BA_ "GenSigSendType" SG_ 255 Window_DrvPwrWdwCmd 4;
BA_ "UserSigValidity" SG_ 255 Window_DrvPwrWdwCmd 0;
BA_ "NetworkRequest" SG_ 255 Window_DrvPwrWdwCmd 0;
BA_ "NetworkRequestHoldingTime" SG_ 255 Window_DrvPwrWdwCmd 5000;
BA_ "Version" SG_ 255 Window_DrvPwrWdwCmd "21.01.06";
BA_ "Description" SG_ 255 Window_AsstPwrWdwCmd "Assist Power Window Command";
BA_ "GenSigSendType" SG_ 255 Window_AsstPwrWdwCmd 4;
BA_ "UserSigValidity" SG_ 255 Window_AsstPwrWdwCmd 0;
BA_ "NetworkRequest" SG_ 255 Window_AsstPwrWdwCmd 0;
BA_ "NetworkRequestHoldingTime" SG_ 255 Window_AsstPwrWdwCmd 5000;
BA_ "Version" SG_ 255 Window_AsstPwrWdwCmd "21.03.00";
BA_ "Description" SG_ 255 Window_RrLftPwrWdwCmd "Rear Left Power Window Command";
BA_ "GenSigSendType" SG_ 255 Window_RrLftPwrWdwCmd 4;
BA_ "UserSigValidity" SG_ 255 Window_RrLftPwrWdwCmd 0;
BA_ "NetworkRequest" SG_ 255 Window_RrLftPwrWdwCmd 0;
BA_ "NetworkRequestHoldingTime" SG_ 255 Window_RrLftPwrWdwCmd 5000;
BA_ "Version" SG_ 255 Window_RrLftPwrWdwCmd "21.03.00";
BA_ "Description" SG_ 255 Window_RrRtPwrWdwCmd "Rear Right Power Window Command";
BA_ "GenSigSendType" SG_ 255 Window_RrRtPwrWdwCmd 4;
BA_ "UserSigValidity" SG_ 255 Window_RrRtPwrWdwCmd 0;
BA_ "NetworkRequest" SG_ 255 Window_RrRtPwrWdwCmd 0;
BA_ "NetworkRequestHoldingTime" SG_ 255 Window_RrRtPwrWdwCmd 5000;
BA_ "Version" SG_ 255 Window_RrRtPwrWdwCmd "21.03.00";
BA_ "Description" SG_ 255 Mirror_FldUnfldCmd "Mirror Folding Unfolding Command";
BA_ "GenSigSendType" SG_ 255 Mirror_FldUnfldCmd 4;
BA_ "UserSigValidity" SG_ 255 Mirror_FldUnfldCmd 0;
BA_ "NetworkRequest" SG_ 255 Mirror_FldUnfldCmd 0;
BA_ "NetworkRequestHoldingTime" SG_ 255 Mirror_FldUnfldCmd 5000;
BA_ "Version" SG_ 255 Mirror_FldUnfldCmd "21.03.00";
BA_ "Description" SG_ 255 Mirror_FldCtrlSta "Mirror Fold and Folding Control State";
BA_ "GenSigSendType" SG_ 255 Mirror_FldCtrlSta 4;
BA_ "UserSigValidity" SG_ 255 Mirror_FldCtrlSta 0;
BA_ "NetworkRequest" SG_ 255 Mirror_FldCtrlSta 0;
BA_ "NetworkRequestHoldingTime" SG_ 255 Mirror_FldCtrlSta 5000;
BA_ "Version" SG_ 255 Mirror_FldCtrlSta "21.03.00";
BA_ "Description" SG_ 255 Mirror_UnFldCtrlSta "Mirror Unfold and Unfolding Control State";
BA_ "GenSigSendType" SG_ 255 Mirror_UnFldCtrlSta 4;
BA_ "UserSigValidity" SG_ 255 Mirror_UnFldCtrlSta 0;
BA_ "NetworkRequest" SG_ 255 Mirror_UnFldCtrlSta 0;
BA_ "NetworkRequestHoldingTime" SG_ 255 Mirror_UnFldCtrlSta 5000;
BA_ "Version" SG_ 255 Mirror_UnFldCtrlSta "21.03.00";
BA_ "Description" SG_ 255 Mirror_PosMnlCmd "Mirror Positioning Request";
BA_ "GenSigSendType" SG_ 255 Mirror_PosMnlCmd 4;
BA_ "UserSigValidity" SG_ 255 Mirror_PosMnlCmd 0;
BA_ "NetworkRequest" SG_ 255 Mirror_PosMnlCmd 0;
BA_ "NetworkRequestHoldingTime" SG_ 255 Mirror_PosMnlCmd 5000;
BA_ "Version" SG_ 255 Mirror_PosMnlCmd "21.03.00";
BA_ "Description" SG_ 255 Mirror_SelSwIndCmd "Mirror Select Switch Indicator Command";
BA_ "GenSigSendType" SG_ 255 Mirror_SelSwIndCmd 4;
BA_ "UserSigValidity" SG_ 255 Mirror_SelSwIndCmd 0;
BA_ "NetworkRequest" SG_ 255 Mirror_SelSwIndCmd 0;
BA_ "NetworkRequestHoldingTime" SG_ 255 Mirror_SelSwIndCmd 5000;
BA_ "Version" SG_ 255 Mirror_SelSwIndCmd "21.03.00";
BA_ "Description" SG_ 255 BCM_SafetyWdwOptTyp2 "Option Signal for Safety Window System";
BA_ "GenSigSendType" SG_ 255 BCM_SafetyWdwOptTyp2 4;
BA_ "UserSigValidity" SG_ 255 BCM_SafetyWdwOptTyp2 0;
BA_ "NetworkRequest" SG_ 255 BCM_SafetyWdwOptTyp2 0;
BA_ "NetworkRequestHoldingTime" SG_ 255 BCM_SafetyWdwOptTyp2 5000;
BA_ "Version" SG_ 255 BCM_SafetyWdwOptTyp2 "20.08.05";
BA_ "Description" SG_ 255 Mirror_LHOSMirPlyBckSta "This siganl indicates Left O/S Mirror moving state for IMS From BDC";
BA_ "GenSigSendType" SG_ 255 Mirror_LHOSMirPlyBckSta 4;
BA_ "UserSigValidity" SG_ 255 Mirror_LHOSMirPlyBckSta 0;
BA_REL_ "GenSigTimeoutTime" BU_SG_REL_ DPSU SG_ 255 Mirror_LHOSMirPlyBckSta 1500;
BA_ "NetworkRequest" SG_ 255 Mirror_LHOSMirPlyBckSta 0;
BA_ "NetworkRequestHoldingTime" SG_ 255 Mirror_LHOSMirPlyBckSta 5000;
BA_ "Version" SG_ 255 Mirror_LHOSMirPlyBckSta "21.03.00";
BA_ "Description" SG_ 255 Mirror_RHOSMirPlyBckSta "This siganl indicates Right O/S Mirror moving state for IMS From BDC";
BA_ "GenSigSendType" SG_ 255 Mirror_RHOSMirPlyBckSta 4;
BA_ "UserSigValidity" SG_ 255 Mirror_RHOSMirPlyBckSta 0;
BA_REL_ "GenSigTimeoutTime" BU_SG_REL_ DPSU SG_ 255 Mirror_RHOSMirPlyBckSta 1500;
BA_ "NetworkRequest" SG_ 255 Mirror_RHOSMirPlyBckSta 0;
BA_ "NetworkRequestHoldingTime" SG_ 255 Mirror_RHOSMirPlyBckSta 5000;
BA_ "Version" SG_ 255 Mirror_RHOSMirPlyBckSta "21.03.00";
BA_ "Description" SG_ 255 Mirror_SelSwSta "Outside Mirror Select Button Status";
BA_ "GenSigSendType" SG_ 255 Mirror_SelSwSta 4;
BA_ "UserSigValidity" SG_ 255 Mirror_SelSwSta 0;
BA_ "NetworkRequest" SG_ 255 Mirror_SelSwSta 0;
BA_ "NetworkRequestHoldingTime" SG_ 255 Mirror_SelSwSta 5000;
BA_ "Version" SG_ 255 Mirror_SelSwSta "20.12.00";
BA_ "Description" SG_ 255 BckGls_RrGlsHtdOpt "Back Glass_Rear Glass Heated Option Signal";
BA_ "GenSigSendType" SG_ 255 BckGls_RrGlsHtdOpt 4;
BA_ "UserSigValidity" SG_ 255 BckGls_RrGlsHtdOpt 0;
BA_ "Version" SG_ 255 BckGls_RrGlsHtdOpt "21.06.08";
BA_ "GenMsgSendType" BO_ 2344811009 0;
BA_ "GenMsgCycleTimeFast" BO_ 2344811009 0;
BA_ "GenMsgNrOfRepetition" BO_ 2344811009 0;
BA_ "VFrameFormat" BO_ 2344811009 1;
BA_ "Description" SG_ 2344811009 BMS_Crc2Val "The data area for CRC calculation is based on the data length (DLC) of the message DB.

The CRC shall be calculated over the entire data block (excluding the CRC bytes) including the user data, alive counter and Data ID

 

- CRC Polynomial (0x1021) , Initial Value : 0xFFFF, XOR value : 0x0000, Data ID : Message ID + 0xF800 

- The initial value is for CRC calculation and the message should be sent with the calculated result value. 

- The mathematical expression to 16 bit CRC polynomial is given here. G(x) = x16 + x12 + x5 + 1";
BA_ "GenSigStartValue" SG_ 2344811009 BMS_Crc2Val 65535;
BA_ "UserSigValidity" SG_ 2344811009 BMS_Crc2Val 3;
BA_ "RoutingFactor" SG_ 2344811009 BMS_Crc2Val 2;
BA_ "Version" SG_ 2344811009 BMS_Crc2Val "18.11.08";
BA_ "Description" SG_ 2344811009 BMS_AlvCnt2Val "For the first transmission request for a data element the counter shall be initialized with 0 and shall be incremented by 1 for every subsequent send request. 

When the counter reaches the maximum value(0xFF), then it shall restart with 0 for the next send request";
BA_ "UserSigValidity" SG_ 2344811009 BMS_AlvCnt2Val 3;
BA_ "RoutingFactor" SG_ 2344811009 BMS_AlvCnt2Val 2;
BA_ "Version" SG_ 2344811009 BMS_AlvCnt2Val "18.11.08";
BA_ "Description" SG_ 2344811009 xEV_SrvLmpReq "Service Lamp request";
BA_ "UserSigValidity" SG_ 2344811009 xEV_SrvLmpReq 7;
BA_ "RoutingFactor" SG_ 2344811009 xEV_SrvLmpReq 2;
BA_ "Version" SG_ 2344811009 xEV_SrvLmpReq "18.11.01";
BA_ "Description" SG_ 2344811009 xEV_MainRlyOnSta "Main Relay On Status";
BA_ "UserSigValidity" SG_ 2344811009 xEV_MainRlyOnSta 7;
BA_ "RoutingFactor" SG_ 2344811009 xEV_MainRlyOnSta 2;
BA_ "Version" SG_ 2344811009 xEV_MainRlyOnSta "18.11.01";
BA_ "Description" SG_ 2344811009 xEV_SysFltSta "BMS Fault";
BA_ "UserSigValidity" SG_ 2344811009 xEV_SysFltSta 7;
BA_ "RoutingFactor" SG_ 2344811009 xEV_SysFltSta 2;
BA_ "Version" SG_ 2344811009 xEV_SysFltSta "18.11.01";
BA_ "Description" SG_ 2344811009 xEV_BattRmnEnrgVal "Difference of increased or decreased battery resistance";
BA_ "UserSigValidity" SG_ 2344811009 xEV_BattRmnEnrgVal 7;
BA_ "RoutingFactor" SG_ 2344811009 xEV_BattRmnEnrgVal 2;
BA_ "Version" SG_ 2344811009 xEV_BattRmnEnrgVal "18.11.01";
BA_ "Description" SG_ 2344811009 xEV_InltTempVal "Battery Inlet Temperature";
BA_ "UserSigValidity" SG_ 2344811009 xEV_InltTempVal 7;
BA_ "RoutingFactor" SG_ 2344811009 xEV_InltTempVal 2;
BA_ "Version" SG_ 2344811009 xEV_InltTempVal "20.07.05";
BA_ "Description" SG_ 2344811009 xEV_MinBattCelVoltVal "Minimum Battery Cell Voltage";
BA_ "GenSigStartValue" SG_ 2344811009 xEV_MinBattCelVoltVal 3;
BA_ "UserSigValidity" SG_ 2344811009 xEV_MinBattCelVoltVal 7;
BA_ "RoutingFactor" SG_ 2344811009 xEV_MinBattCelVoltVal 2;
BA_ "Version" SG_ 2344811009 xEV_MinBattCelVoltVal "18.11.01";
BA_ "Description" SG_ 2344811009 xEV_MaxBattCelVoltVal "Maximum Battery Cell Voltage";
BA_ "GenSigStartValue" SG_ 2344811009 xEV_MaxBattCelVoltVal 3;
BA_ "UserSigValidity" SG_ 2344811009 xEV_MaxBattCelVoltVal 7;
BA_ "RoutingFactor" SG_ 2344811009 xEV_MaxBattCelVoltVal 2;
BA_ "Version" SG_ 2344811009 xEV_MaxBattCelVoltVal "18.11.01";
BA_ "GenMsgSendType" BO_ 2344811010 0;
BA_ "GenMsgCycleTimeFast" BO_ 2344811010 0;
BA_ "GenMsgNrOfRepetition" BO_ 2344811010 0;
BA_ "VFrameFormat" BO_ 2344811010 1;
BA_ "Description" SG_ 2344811010 xEV_BattCurrVal "xEV_Battery Current Value (CR_Bms_BatI_A)";
BA_ "UserSigValidity" SG_ 2344811010 xEV_BattCurrVal 7;
BA_ "RoutingFactor" SG_ 2344811010 xEV_BattCurrVal 2;
BA_ "Version" SG_ 2344811010 xEV_BattCurrVal "18.11.01";
BA_ "Description" SG_ 2344811010 xEV_MinBattTempVal "Minimum Battery Temperature";
BA_ "UserSigValidity" SG_ 2344811010 xEV_MinBattTempVal 7;
BA_ "RoutingFactor" SG_ 2344811010 xEV_MinBattTempVal 2;
BA_ "Version" SG_ 2344811010 xEV_MinBattTempVal "18.11.01";
BA_ "Description" SG_ 2344811010 xEV_MaxBattTempVal "Maximum Battery Temperature";
BA_ "UserSigValidity" SG_ 2344811010 xEV_MaxBattTempVal 7;
BA_ "RoutingFactor" SG_ 2344811010 xEV_MaxBattTempVal 2;
BA_ "Version" SG_ 2344811010 xEV_MaxBattTempVal "18.11.01";
BA_ "Description" SG_ 2344811010 xEV_FanSpdStpSta "Battery Cooling Fan Speed Step";
BA_ "UserSigValidity" SG_ 2344811010 xEV_FanSpdStpSta 7;
BA_ "RoutingFactor" SG_ 2344811010 xEV_FanSpdStpSta 2;
BA_ "Version" SG_ 2344811010 xEV_FanSpdStpSta "18.11.01";
BA_ "Description" SG_ 2344811010 xEV_12VRlyOffAlrmReq "12V Battery Relay Off Alarm Request";
BA_ "UserSigValidity" SG_ 2344811010 xEV_12VRlyOffAlrmReq 7;
BA_ "RoutingFactor" SG_ 2344811010 xEV_12VRlyOffAlrmReq 2;
BA_ "Version" SG_ 2344811010 xEV_12VRlyOffAlrmReq "18.11.01";
BA_ "Description" SG_ 2344811010 xEV_12VRlyOnAlrmReq "12V Battery Relay On Alarm Request";
BA_ "UserSigValidity" SG_ 2344811010 xEV_12VRlyOnAlrmReq 7;
BA_ "RoutingFactor" SG_ 2344811010 xEV_12VRlyOnAlrmReq 2;
BA_ "Version" SG_ 2344811010 xEV_12VRlyOnAlrmReq "18.11.01";
BA_ "Description" SG_ 2344811010 xEV_DiagGrpVal "Diagnosis code";
BA_ "UserSigValidity" SG_ 2344811010 xEV_DiagGrpVal 7;
BA_ "RoutingFactor" SG_ 2344811010 xEV_DiagGrpVal 2;
BA_ "Version" SG_ 2344811010 xEV_DiagGrpVal "18.11.01";
BA_ "Description" SG_ 2344811010 xEV_DiagMonVal "Diagnosis data";
BA_ "UserSigValidity" SG_ 2344811010 xEV_DiagMonVal 7;
BA_ "RoutingFactor" SG_ 2344811010 xEV_DiagMonVal 2;
BA_ "Version" SG_ 2344811010 xEV_DiagMonVal "18.11.01";
BA_ "Description" SG_ 2344811010 xEV_SocDis "Cluster, AVN Display SOC";
BA_ "UserSigValidity" SG_ 2344811010 xEV_SocDis 7;
BA_REL_ "GenSigTimeoutTime" BU_SG_REL_ SWRC SG_ 2344811010 xEV_SocDis 1500;
BA_ "RoutingFactor" SG_ 2344811010 xEV_SocDis 2;
BA_ "Version" SG_ 2344811010 xEV_SocDis "20.07.05";
BA_ "GenMsgSendType" BO_ 2344811011 0;
BA_ "GenMsgCycleTimeFast" BO_ 2344811011 0;
BA_ "GenMsgNrOfRepetition" BO_ 2344811011 0;
BA_ "VFrameFormat" BO_ 2344811011 1;
BA_ "Description" SG_ 2344811011 PHEV_SubInltTempVal "Sub Pack Inlet Temperature

(If MSB is 1, (PH) = 1 * (HEX) ? 256 [¡É]

else (PH) = 1 * (HEX) [¡É])";
BA_ "UserSigValidity" SG_ 2344811011 PHEV_SubInltTempVal 7;
BA_ "RoutingFactor" SG_ 2344811011 PHEV_SubInltTempVal 2;
BA_ "Version" SG_ 2344811011 PHEV_SubInltTempVal "18.11.01";
BA_ "Description" SG_ 2344811011 xEV_12VAlarmReqForICU "xEV_12V Battery Alarm Request For ICU";
BA_ "UserSigValidity" SG_ 2344811011 xEV_12VAlarmReqForICU 7;
BA_ "RoutingFactor" SG_ 2344811011 xEV_12VAlarmReqForICU 2;
BA_ "Version" SG_ 2344811011 xEV_12VAlarmReqForICU "18.11.01";
BA_ "Description" SG_ 2344811011 xEV_AuxBattChrgReq "Aux. Battery Charge Request Flag

***new signal***";
BA_ "UserSigValidity" SG_ 2344811011 xEV_AuxBattChrgReq 7;
BA_ "RoutingFactor" SG_ 2344811011 xEV_AuxBattChrgReq 2;
BA_ "Version" SG_ 2344811011 xEV_AuxBattChrgReq "19.06.00";
BA_ "Description" SG_ 2344811011 xEV_12VDarkCurrAlarmForICU "12V Battery Alarm request for ICU(CGW)";
BA_ "UserSigValidity" SG_ 2344811011 xEV_12VDarkCurrAlarmForICU 7;
BA_ "RoutingFactor" SG_ 2344811011 xEV_12VDarkCurrAlarmForICU 2;
BA_ "Version" SG_ 2344811011 xEV_12VDarkCurrAlarmForICU "18.11.01";
BA_ "Description" SG_ 2344811011 xEV_12VBatVLmt "xEV_12VBatteryVoltageLimit(CR_Bms_12V_BatV_Lmt)";
BA_ "UserSigValidity" SG_ 2344811011 xEV_12VBatVLmt 7;
BA_ "RoutingFactor" SG_ 2344811011 xEV_12VBatVLmt 2;
BA_ "Version" SG_ 2344811011 xEV_12VBatVLmt "18.11.01";
BA_ "Description" SG_ 2344811011 xEV_CharBatInfoReqForSDC "Function of determining first battery to charge (12V battery or High voltage battery)";
BA_ "UserSigValidity" SG_ 2344811011 xEV_CharBatInfoReqForSDC 7;
BA_ "RoutingFactor" SG_ 2344811011 xEV_CharBatInfoReqForSDC 2;
BA_ "Version" SG_ 2344811011 xEV_CharBatInfoReqForSDC "18.11.01";
BA_ "Description" SG_ 2344811011 xEV_ClimateOffReq "xEV_ClimateOffRequest  --Alarm flag at climate off requested (CF_Bms_ClimateOffReq)";
BA_ "UserSigValidity" SG_ 2344811011 xEV_ClimateOffReq 7;
BA_ "RoutingFactor" SG_ 2344811011 xEV_ClimateOffReq 2;
BA_ "Version" SG_ 2344811011 xEV_ClimateOffReq "18.11.01";
BA_ "Description" SG_ 2344811011 xEV_MainRlyOnRetrySta "BMS sets this Flag until BMS completes Relay ON Sequence for Relay recontact";
BA_ "UserSigValidity" SG_ 2344811011 xEV_MainRlyOnRetrySta 7;
BA_ "RoutingFactor" SG_ 2344811011 xEV_MainRlyOnRetrySta 2;
BA_ "Version" SG_ 2344811011 xEV_MainRlyOnRetrySta "18.11.01";
BA_ "Description" SG_ 2344811011 xEV_Bms_BlackBox_Data_req "For Saving BMS data set, this signal transmits to MCU";
BA_ "UserSigValidity" SG_ 2344811011 xEV_Bms_BlackBox_Data_req 7;
BA_ "RoutingFactor" SG_ 2344811011 xEV_Bms_BlackBox_Data_req 2;
BA_ "Version" SG_ 2344811011 xEV_Bms_BlackBox_Data_req "20.03.06";
BA_ "Description" SG_ 2344811011 xEV_12V_BatDchCurrLmt "xEV_12V Battery Discharge Current Limit (CR_Bms_12V_BatDchI_Lmt)";
BA_ "UserSigValidity" SG_ 2344811011 xEV_12V_BatDchCurrLmt 7;
BA_ "RoutingFactor" SG_ 2344811011 xEV_12V_BatDchCurrLmt 2;
BA_ "Version" SG_ 2344811011 xEV_12V_BatDchCurrLmt "18.11.01";
BA_ "Description" SG_ 2344811011 xEV_12VChargeReq "xEV_12VBatteryChargeRequest (for 12V battery over-discharge protection) (CF_Bms_12_ChargeReq)";
BA_ "UserSigValidity" SG_ 2344811011 xEV_12VChargeReq 7;
BA_ "RoutingFactor" SG_ 2344811011 xEV_12VChargeReq 2;
BA_ "Version" SG_ 2344811011 xEV_12VChargeReq "18.11.02";
BA_ "Description" SG_ 2344811011 xEV_BmsRomType "BMS rom type variation of Battery Pack Specification";
BA_ "UserSigValidity" SG_ 2344811011 xEV_BmsRomType 7;
BA_ "RoutingFactor" SG_ 2344811011 xEV_BmsRomType 2;
BA_ "Version" SG_ 2344811011 xEV_BmsRomType "21.01.03";
BA_ "Description" SG_ 2344811011 xEV_12V_CurrFltDetectReq "xEV_12V Battery Current Sensor Fault Detect Request";
BA_ "UserSigValidity" SG_ 2344811011 xEV_12V_CurrFltDetectReq 7;
BA_ "RoutingFactor" SG_ 2344811011 xEV_12V_CurrFltDetectReq 2;
BA_ "Version" SG_ 2344811011 xEV_12V_CurrFltDetectReq "19.01.00";
BA_ "Description" SG_ 2344811011 xEV_PRATempSnsVal_ "xEV_PRATemperatureSensorValue";
BA_ "UserSigValidity" SG_ 2344811011 xEV_PRATempSnsVal_ 7;
BA_ "RoutingFactor" SG_ 2344811011 xEV_PRATempSnsVal_ 2;
BA_ "Version" SG_ 2344811011 xEV_PRATempSnsVal_ "19.01.00";
BA_ "Description" SG_ 2344811011 xEV_PRATempSns2Val_ "xEV_PRATemperatureSensor2Value";
BA_ "UserSigValidity" SG_ 2344811011 xEV_PRATempSns2Val_ 7;
BA_ "RoutingFactor" SG_ 2344811011 xEV_PRATempSns2Val_ 2;
BA_ "Version" SG_ 2344811011 xEV_PRATempSns2Val_ "19.01.00";
BA_ "Description" SG_ 2344811011 xEV_12VRlyOnSwReq "12V relay ON switch ON status. BMS sets this Flag when 12V Relay Switch is ON.";
BA_ "UserSigValidity" SG_ 2344811011 xEV_12VRlyOnSwReq 7;
BA_ "RoutingFactor" SG_ 2344811011 xEV_12VRlyOnSwReq 2;
BA_ "Version" SG_ 2344811011 xEV_12VRlyOnSwReq "18.11.01";
BA_ "GenMsgSendType" BO_ 2344811012 0;
BA_ "GenMsgCycleTimeFast" BO_ 2344811012 0;
BA_ "GenMsgNrOfRepetition" BO_ 2344811012 0;
BA_ "VFrameFormat" BO_ 2344811012 1;
BA_ "Description" SG_ 2344811012 xEV_BattRCHTimeEst "calculated charging time by esrimated OBC output power

***HS CAN : BMS7(0x598), CR_Bms_RCHTimeEst***";
BA_ "UserSigValidity" SG_ 2344811012 xEV_BattRCHTimeEst 7;
BA_ "RoutingFactor" SG_ 2344811012 xEV_BattRCHTimeEst 2;
BA_ "Version" SG_ 2344811012 xEV_BattRCHTimeEst "19.04.06";
BA_ "Description" SG_ 2344811012 EV_DischrgCurrLimForV2X "Discharge Current Limit(for V2X)

***new signal***";
BA_ "UserSigValidity" SG_ 2344811012 EV_DischrgCurrLimForV2X 7;
BA_ "RoutingFactor" SG_ 2344811012 EV_DischrgCurrLimForV2X 2;
BA_ "Version" SG_ 2344811012 EV_DischrgCurrLimForV2X "20.04.03";
BA_ "Description" SG_ 2344811012 xEV_Bms_IsolDetDeactFuncSta "xEV_Isolation Detection Circuit Deactivate Function Status (GDS Function)";
BA_ "UserSigValidity" SG_ 2344811012 xEV_Bms_IsolDetDeactFuncSta 7;
BA_ "RoutingFactor" SG_ 2344811012 xEV_Bms_IsolDetDeactFuncSta 2;
BA_ "Version" SG_ 2344811012 xEV_Bms_IsolDetDeactFuncSta "20.06.10";
BA_ "Description" SG_ 2344811012 xEV_Bms_CellBalDeactFuncSta "xEV_Cell Balancing Deactivate Function Status (GDS Function)";
BA_ "UserSigValidity" SG_ 2344811012 xEV_Bms_CellBalDeactFuncSta 7;
BA_ "RoutingFactor" SG_ 2344811012 xEV_Bms_CellBalDeactFuncSta 2;
BA_ "Version" SG_ 2344811012 xEV_Bms_CellBalDeactFuncSta "20.06.10";
BA_ "Description" SG_ 2344811012 EV_V2XDischrgLimSocVal_SYNC "Feedback SOC of  V2X discharge limitation for sync by BMS

***New Signal***";
BA_ "UserSigValidity" SG_ 2344811012 EV_V2XDischrgLimSocVal_SYNC 7;
BA_ "RoutingFactor" SG_ 2344811012 EV_V2XDischrgLimSocVal_SYNC 2;
BA_ "Version" SG_ 2344811012 EV_V2XDischrgLimSocVal_SYNC "20.11.02";
BA_ "Description" SG_ 2344811012 xEV_BMS_SOC_2nd "2nd SOC for NEV";
BA_ "UserSigValidity" SG_ 2344811012 xEV_BMS_SOC_2nd 7;
BA_ "RoutingFactor" SG_ 2344811012 xEV_BMS_SOC_2nd 2;
BA_ "Version" SG_ 2344811012 xEV_BMS_SOC_2nd "20.03.07";
BA_ "GenMsgSendType" BO_ 733 0;
BA_ "Description" SG_ 733 CMS_LH_Crc1Val "The data area for CRC calculation is based on the data length (DLC) of the message DB.

The CRC shall be calculated over the entire data block (excluding the CRC bytes) including the user data, alive counter and Data ID 

 

- CRC Polynomial (0x1D) , Initial Value : 0x00, XOR value : 0xFF, Data ID Mode : Both, Data ID : Message ID + 0xF800 

- The initial value is for CRC calculation and the message should be sent with the calculated result value. 

The mathematical expression to 8 bit CRC polynomial is given here. G(x) = x8 + x4 + x3 + x2 + 1";
BA_ "GenSigSendType" SG_ 733 CMS_LH_Crc1Val 4;
BA_ "GenSigStartValue" SG_ 733 CMS_LH_Crc1Val 255;
BA_ "UserSigValidity" SG_ 733 CMS_LH_Crc1Val 0;
BA_ "RoutingFactor" SG_ 733 CMS_LH_Crc1Val 0;
BA_ "Version" SG_ 733 CMS_LH_Crc1Val "19.09.06";
BA_ "Description" SG_ 733 CMS_LH_AlvCnt1Val "For the first transmission request for a data element the counter shall be initialized with 0 and shall be incremented by 1

for every subsequent send request. When the counter reaches the maximum value(0xE), then it shall restart with 0 for the next send request";
BA_ "GenSigSendType" SG_ 733 CMS_LH_AlvCnt1Val 4;
BA_ "UserSigValidity" SG_ 733 CMS_LH_AlvCnt1Val 0;
BA_ "RoutingFactor" SG_ 733 CMS_LH_AlvCnt1Val 0;
BA_ "Version" SG_ 733 CMS_LH_AlvCnt1Val "19.09.06";
BA_ "GenSigSendType" SG_ 733 USM_TurnDstLnDispSta 4;
BA_ "UserSigValidity" SG_ 733 USM_TurnDstLnDispSta 0;
BA_ "NetworkRequest" SG_ 733 USM_TurnDstLnDispSta 0;
BA_ "NetworkRequestHoldingTime" SG_ 733 USM_TurnDstLnDispSta 5;
BA_ "RoutingFactor" SG_ 733 USM_TurnDstLnDispSta 0;
BA_ "Version" SG_ 733 USM_TurnDstLnDispSta "19.12.00";
BA_ "GenSigSendType" SG_ 733 USM_TurnDstLnDispStaRH 4;
BA_ "UserSigValidity" SG_ 733 USM_TurnDstLnDispStaRH 0;
BA_ "NetworkRequest" SG_ 733 USM_TurnDstLnDispStaRH 0;
BA_ "NetworkRequestHoldingTime" SG_ 733 USM_TurnDstLnDispStaRH 5;
BA_ "RoutingFactor" SG_ 733 USM_TurnDstLnDispStaRH 0;
BA_ "Version" SG_ 733 USM_TurnDstLnDispStaRH "19.12.00";
BA_ "GenSigSendType" SG_ 733 USM_RhstaLvlEnaSta 4;
BA_ "UserSigValidity" SG_ 733 USM_RhstaLvlEnaSta 0;
BA_ "NetworkRequest" SG_ 733 USM_RhstaLvlEnaSta 0;
BA_ "NetworkRequestHoldingTime" SG_ 733 USM_RhstaLvlEnaSta 5;
BA_ "RoutingFactor" SG_ 733 USM_RhstaLvlEnaSta 0;
BA_ "Version" SG_ 733 USM_RhstaLvlEnaSta "19.12.00";
BA_ "GenSigSendType" SG_ 733 USM_RhstaLvlEnaStaRH 4;
BA_ "UserSigValidity" SG_ 733 USM_RhstaLvlEnaStaRH 0;
BA_ "NetworkRequest" SG_ 733 USM_RhstaLvlEnaStaRH 0;
BA_ "NetworkRequestHoldingTime" SG_ 733 USM_RhstaLvlEnaStaRH 5;
BA_ "RoutingFactor" SG_ 733 USM_RhstaLvlEnaStaRH 0;
BA_ "Version" SG_ 733 USM_RhstaLvlEnaStaRH "19.12.00";
BA_ "GenSigSendType" SG_ 733 USM_CMSDayBrgtnsLvlLHSta 4;
BA_ "GenSigStartValue" SG_ 733 USM_CMSDayBrgtnsLvlLHSta 5;
BA_ "UserSigValidity" SG_ 733 USM_CMSDayBrgtnsLvlLHSta 0;
BA_ "NetworkRequest" SG_ 733 USM_CMSDayBrgtnsLvlLHSta 0;
BA_ "NetworkRequestHoldingTime" SG_ 733 USM_CMSDayBrgtnsLvlLHSta 5;
BA_ "RoutingFactor" SG_ 733 USM_CMSDayBrgtnsLvlLHSta 0;
BA_ "Version" SG_ 733 USM_CMSDayBrgtnsLvlLHSta "19.12.00";
BA_ "GenSigSendType" SG_ 733 USM_CMSNgtBrgtnsLvlLHSta 4;
BA_ "GenSigStartValue" SG_ 733 USM_CMSNgtBrgtnsLvlLHSta 5;
BA_ "UserSigValidity" SG_ 733 USM_CMSNgtBrgtnsLvlLHSta 0;
BA_ "NetworkRequest" SG_ 733 USM_CMSNgtBrgtnsLvlLHSta 0;
BA_ "NetworkRequestHoldingTime" SG_ 733 USM_CMSNgtBrgtnsLvlLHSta 5;
BA_ "RoutingFactor" SG_ 733 USM_CMSNgtBrgtnsLvlLHSta 0;
BA_ "Version" SG_ 733 USM_CMSNgtBrgtnsLvlLHSta "19.12.00";
BA_ "GenSigSendType" SG_ 733 IMS_CMSPlayBackSta_LH 4;
BA_ "UserSigValidity" SG_ 733 IMS_CMSPlayBackSta_LH 0;
BA_REL_ "GenSigTimeoutTime" BU_SG_REL_ DPSU SG_ 733 IMS_CMSPlayBackSta_LH 1500;
BA_ "NetworkRequest" SG_ 733 IMS_CMSPlayBackSta_LH 0;
BA_ "NetworkRequestHoldingTime" SG_ 733 IMS_CMSPlayBackSta_LH 5;
BA_ "RoutingFactor" SG_ 733 IMS_CMSPlayBackSta_LH 0;
BA_ "Version" SG_ 733 IMS_CMSPlayBackSta_LH "20.08.07";
BA_ "GenSigSendType" SG_ 733 CMSFldReq 4;
BA_ "UserSigValidity" SG_ 733 CMSFldReq 0;
BA_ "NetworkRequest" SG_ 733 CMSFldReq 0;
BA_ "NetworkRequestHoldingTime" SG_ 733 CMSFldReq 5;
BA_ "RoutingFactor" SG_ 733 CMSFldReq 0;
BA_ "Version" SG_ 733 CMSFldReq "20.08.07";
BA_ "GenSigSendType" SG_ 733 CMS_LH_FoldingSta 4;
BA_ "UserSigValidity" SG_ 733 CMS_LH_FoldingSta 0;
BA_ "NetworkRequest" SG_ 733 CMS_LH_FoldingSta 0;
BA_ "NetworkRequestHoldingTime" SG_ 733 CMS_LH_FoldingSta 5000;
BA_ "RoutingFactor" SG_ 733 CMS_LH_FoldingSta 0;
BA_ "Version" SG_ 733 CMS_LH_FoldingSta "20.11.04";
BA_ "GenSigSendType" SG_ 733 CMS_LH_UnfoldingSta 4;
BA_ "UserSigValidity" SG_ 733 CMS_LH_UnfoldingSta 0;
BA_ "NetworkRequest" SG_ 733 CMS_LH_UnfoldingSta 0;
BA_ "NetworkRequestHoldingTime" SG_ 733 CMS_LH_UnfoldingSta 5000;
BA_ "RoutingFactor" SG_ 733 CMS_LH_UnfoldingSta 0;
BA_ "Version" SG_ 733 CMS_LH_UnfoldingSta "20.11.04";
BA_ "Description" SG_ 733 CMS_LHVerPosVal "This signal indicates LH Outside Mirror Vertical Position Sensor Voltage";
BA_ "GenSigSendType" SG_ 733 CMS_LHVerPosVal 4;
BA_ "UserSigValidity" SG_ 733 CMS_LHVerPosVal 0;
BA_ "NetworkRequest" SG_ 733 CMS_LHVerPosVal 0;
BA_ "NetworkRequestHoldingTime" SG_ 733 CMS_LHVerPosVal 5000;
BA_ "RoutingFactor" SG_ 733 CMS_LHVerPosVal 0;
BA_ "Version" SG_ 733 CMS_LHVerPosVal "20.08.07";
BA_ "Description" SG_ 733 CMS_LHHorPosVal "This signal indicates LH Outside Mirror Horizontal Position Sensor Voltage";
BA_ "GenSigSendType" SG_ 733 CMS_LHHorPosVal 4;
BA_ "UserSigValidity" SG_ 733 CMS_LHHorPosVal 0;
BA_ "NetworkRequest" SG_ 733 CMS_LHHorPosVal 0;
BA_ "NetworkRequestHoldingTime" SG_ 733 CMS_LHHorPosVal 5000;
BA_ "RoutingFactor" SG_ 733 CMS_LHHorPosVal 0;
BA_ "Version" SG_ 733 CMS_LHHorPosVal "20.08.07";
BA_ "GenSigSendType" SG_ 733 Monitor_ViewPanningCmd 4;
BA_ "UserSigValidity" SG_ 733 Monitor_ViewPanningCmd 0;
BA_ "NetworkRequest" SG_ 733 Monitor_ViewPanningCmd 0;
BA_ "NetworkRequestHoldingTime" SG_ 733 Monitor_ViewPanningCmd 5000;
BA_ "RoutingFactor" SG_ 733 Monitor_ViewPanningCmd 0;
BA_ "Version" SG_ 733 Monitor_ViewPanningCmd "19.09.06";
BA_ "GenMsgSendType" BO_ 2365803009 0;
BA_ "GenMsgCycleTime" BO_ 2365803009 1000;
BA_ "GenMsgCycleTimeFast" BO_ 2365803009 0;
BA_ "GenMsgNrOfRepetition" BO_ 2365803009 0;
BA_ "VFrameFormat" BO_ 2365803009 1;
BA_ "Description" SG_ 2365803009 DATC_Crc16Val "The data area for CRC calculation is based on the data length (DLC) of the message DB.

The CRC shall be calculated over the entire data block (excluding the CRC bytes) including the user data, alive counter and Data ID

 

- CRC Polynomial (0x1021) , Initial Value : 0xFFFF, XOR value : 0x0000, Data ID : Message ID + 0xF800 

- The initial value is for CRC calculation and the message should be sent with the calculated result value. 

- The mathematical expression to 16 bit CRC polynomial is given here. G(x) = x16 + x12 + x5 + 1";
BA_ "GenSigStartValue" SG_ 2365803009 DATC_Crc16Val 65535;
BA_ "UserSigValidity" SG_ 2365803009 DATC_Crc16Val 7;
BA_ "Version" SG_ 2365803009 DATC_Crc16Val "19.09.02";
BA_ "Description" SG_ 2365803009 DATC_AlvCnt16Val "For the first transmission request for a data element the counter shall be initialized with 0 and shall be incremented by 1 for every subsequent send request. 

When the counter reaches the maximum value(0xFF), then it shall restart with 0 for the next send request";
BA_ "UserSigValidity" SG_ 2365803009 DATC_AlvCnt16Val 7;
BA_ "Version" SG_ 2365803009 DATC_AlvCnt16Val "19.09.02";
BA_ "Description" SG_ 2365803009 DATC_SwVer1 "This signal idnicates DATC Software Version to display on H_U



Change it to an ASCII code value.";
BA_ "GenSigStartValue" SG_ 2365803009 DATC_SwVer1 127;
BA_ "UserSigValidity" SG_ 2365803009 DATC_SwVer1 7;
BA_ "Version" SG_ 2365803009 DATC_SwVer1 "19.09.02";
BA_ "Description" SG_ 2365803009 DATC_SwVer2 "This signal indicates DATC Software Version to display on H_U



Change it to an ASCII code value.";
BA_ "GenSigStartValue" SG_ 2365803009 DATC_SwVer2 127;
BA_ "UserSigValidity" SG_ 2365803009 DATC_SwVer2 7;
BA_ "Version" SG_ 2365803009 DATC_SwVer2 "19.09.02";
BA_ "Description" SG_ 2365803009 DATC_SwVer3 "This signal indicates DATC Software Version to display on H_U



Change it to an ASCII code value.";
BA_ "GenSigStartValue" SG_ 2365803009 DATC_SwVer3 127;
BA_ "UserSigValidity" SG_ 2365803009 DATC_SwVer3 7;
BA_ "Version" SG_ 2365803009 DATC_SwVer3 "19.09.02";
BA_ "Description" SG_ 2365803009 DATC_Typ2 "Bit0: (AVN Controllable) :  0 ? NOT Apply / 1 ? Apply

Bit1~2 (Multi Auto Indicator) : 0 ? Front & Rear Not Applied (F/R 1step) / 1 ? Front 3 Step & Rear Not Applied (F 3step & R 1step) / 2 ? Front 3 Step & Rear 3 Step (F/R 3step)  / 3 ? Reserved

Bit3~5 (Front Mode Type) : 0 ? 4 MODE / 1 ? 6MODE / 2 ? 7MODE  / 3 ~ 7 ? Reserved

Bit6 (Fine Dust Sensor) : 0 - Fine Dust Sensor Not Applied / 1 - Fine Dust Sensor Applied.

Bit7~8 (Multi Auto Text) : 0 - Multi Auto State Text Not Applied / 1 - Multi Auto State Text Display Only Applied / 2 - Multi Auto State Text Display & Control Applied / 3 ? Reserved

Bit9 (Mode Def Type) : 0 ? Symbol Type / 1 ? Arrow Type

Bit10 : (AIR PURIFIER Button Type) : 0 ? According to the ¡®Controllable(H_U)¡¯ or ¡®Air Purify (Phone App)¡¯  Bit / 1 ? Air Purifier Button Not Applied

Bit11~15 : Reserved";
BA_ "UserSigValidity" SG_ 2365803009 DATC_Typ2 7;
BA_REL_ "GenSigTimeoutTime" BU_SG_REL_ ATS SG_ 2365803009 DATC_Typ2 5000;
BA_ "Version" SG_ 2365803009 DATC_Typ2 "22.02.02";
BA_ "GenMsgSendType" BO_ 2365803010 0;
BA_ "GenMsgCycleTime" BO_ 2365803010 1000;
BA_ "GenMsgCycleTimeFast" BO_ 2365803010 0;
BA_ "GenMsgNrOfRepetition" BO_ 2365803010 0;
BA_ "VFrameFormat" BO_ 2365803010 1;
BA_ "Description" SG_ 2365803010 DATC_SwVer4 "This signal idnicates DATC Detail Software Version



Change it to an ASCII code value.";
BA_ "GenSigStartValue" SG_ 2365803010 DATC_SwVer4 127;
BA_ "UserSigValidity" SG_ 2365803010 DATC_SwVer4 7;
BA_ "Version" SG_ 2365803010 DATC_SwVer4 "21.10.05";
BA_ "Description" SG_ 2365803010 DATC_SwVer5 "This signal idnicates DATC Detail Software Version



Change it to an ASCII code value.";
BA_ "GenSigStartValue" SG_ 2365803010 DATC_SwVer5 127;
BA_ "UserSigValidity" SG_ 2365803010 DATC_SwVer5 7;
BA_ "Version" SG_ 2365803010 DATC_SwVer5 "21.10.05";
BA_ "GenMsgSendType" BO_ 2365803011 0;
BA_ "GenMsgCycleTime" BO_ 2365803011 1000;
BA_ "GenMsgCycleTimeFast" BO_ 2365803011 0;
BA_ "GenMsgNrOfRepetition" BO_ 2365803011 0;
BA_ "VFrameFormat" BO_ 2365803011 1;
BA_ "GenMsgSendType" BO_ 2365803012 0;
BA_ "GenMsgCycleTime" BO_ 2365803012 1000;
BA_ "GenMsgCycleTimeFast" BO_ 2365803012 0;
BA_ "GenMsgNrOfRepetition" BO_ 2365803012 0;
BA_ "VFrameFormat" BO_ 2365803012 1;
BA_ "GenMsgSendType" BO_ 2193667331 0;
BA_ "GenMsgCycleTime" BO_ 2193667331 50;
BA_ "GenMsgCycleTimeFast" BO_ 2193667331 0;
BA_ "GenMsgNrOfRepetition" BO_ 2193667331 0;
BA_ "VFrameFormat" BO_ 2193667331 1;
BA_ "Description" SG_ 2193667331 ENG_TrgtIdleRpmVal "The stationary target speed depends principally of the engine coolant temperature.

There is a difference between the target speed for manual transmission MT and automatic transmission (AT) in ¡¯neutral¡¯ and AT in ¡¯drive¡¯. 

- Immediately after start the catalyst heating function may increase the target speed 

- The battery charge monitoring increase the target speed.

- For A/C use the target speed may be increased";
BA_ "UserSigValidity" SG_ 2193667331 ENG_TrgtIdleRpmVal 3;
BA_ "RoutingFactor" SG_ 2193667331 ENG_TrgtIdleRpmVal 5;
BA_ "Version" SG_ 2193667331 ENG_TrgtIdleRpmVal "17.12.00";
BA_ "Description" SG_ 2193667331 ENG_GearShftDnDis "This signal represents gear shift down display status. EMS transmits gear shift down status to the cluster.";
BA_ "UserSigValidity" SG_ 2193667331 ENG_GearShftDnDis 3;
BA_ "RoutingFactor" SG_ 2193667331 ENG_GearShftDnDis 5;
BA_ "Version" SG_ 2193667331 ENG_GearShftDnDis "17.12.00";
BA_ "Description" SG_ 2193667331 ENG_DsrGearPosDis "This signal represents desirable gear position of current driving condition.

EMS transmits desirable gear position to the cluster.";
BA_ "UserSigValidity" SG_ 2193667331 ENG_DsrGearPosDis 3;
BA_ "RoutingFactor" SG_ 2193667331 ENG_DsrGearPosDis 5;
BA_ "Version" SG_ 2193667331 ENG_DsrGearPosDis "17.12.00";
BA_ "Description" SG_ 2193667331 ENG_SldFuncSta "This signal indicates that if speed limiter function is active or not.

If the speed limiter function is activated then CF_Ems_SldAct = 1. Although ¡°SLD Main¡± switch is on, if the Speed limiter function is deactivated then CF_Ems_SldAct should be set to ¡®0¡¯.";
BA_ "UserSigValidity" SG_ 2193667331 ENG_SldFuncSta 3;
BA_ "RoutingFactor" SG_ 2193667331 ENG_SldFuncSta 5;
BA_ "Version" SG_ 2193667331 ENG_SldFuncSta "17.12.00";
BA_ "Description" SG_ 2193667331 ENG_SldActnSta "This signal indicates that if positive action of a driver at speed limiter function is active or not. If the positive action is activated then CF_Ems_SldPosAct = 1, which let the current vehicle speed to exceed the limit speed set from a driver.

If kick-down switch isn¡¯t connected to engine ECU directly, ECU can recognize the positive action of a driver from accel pedal position indirectly.

When current vehicle speed exceeds the limit speed, vehicle reaction should be distinguished (e.g. lamp reaction or audio warning signal reaction) depending on the status of ¡°CF_Ems_SldPosAct¡±";
BA_ "UserSigValidity" SG_ 2193667331 ENG_SldActnSta 3;
BA_ "RoutingFactor" SG_ 2193667331 ENG_SldActnSta 5;
BA_ "Version" SG_ 2193667331 ENG_SldActnSta "17.12.00";
BA_ "Description" SG_ 2193667331 ENG_FuelTnkPrsrSta "This signal indicates that if fuel tank is high Pressure or not.

If the fuel tank is in high pressure status then CF_Ems_HPresStat = ¡®1¡¯.

If the fuel tank isn¡¯t in high pressure status then CF_Ems_HPresStat should be set to ¡®0¡¯.";
BA_ "UserSigValidity" SG_ 2193667331 ENG_FuelTnkPrsrSta 3;
BA_ "RoutingFactor" SG_ 2193667331 ENG_FuelTnkPrsrSta 5;
BA_ "Version" SG_ 2193667331 ENG_FuelTnkPrsrSta "17.12.00";
BA_ "Description" SG_ 2193667331 ENG_IsgBzrReq "This signal is for Economy Type ISG. This signal is reminding for preventing sudden starting immediately just after engine restarted or driver shift gear N to D range without braking to make auto starting.

 It transfer first 3 times why if valid one is missing.



In the case of 0x1,

Cluster Action : Buzzer on";
BA_ "UserSigValidity" SG_ 2193667331 ENG_IsgBzrReq 3;
BA_ "RoutingFactor" SG_ 2193667331 ENG_IsgBzrReq 5;
BA_ "Version" SG_ 2193667331 ENG_IsgBzrReq "17.12.00";
BA_ "Description" SG_ 2193667331 ENG_IsgFuelCnsmptDis "This signal is the fuel consumption during Idle stop for display to cluster. 

It transfer first 3 times during 0.001L why if valid one is missing, other valid signals are used for extra signals. So, cluster displays 0.001L at only one among three signals.";
BA_ "UserSigValidity" SG_ 2193667331 ENG_IsgFuelCnsmptDis 3;
BA_ "RoutingFactor" SG_ 2193667331 ENG_IsgFuelCnsmptDis 5;
BA_ "Version" SG_ 2193667331 ENG_IsgFuelCnsmptDis "17.12.00";
BA_ "Description" SG_ 2193667331 ENG_FuelCapOpnSta "This signal indicates that if fuel cap is opened or not.

If the fuel cap is opened then CF_Ems_FCopen = 1.

If the fuel tank isn¡¯t opened then CF_Ems_FCopen should be set to ¡®0¡¯.";
BA_ "UserSigValidity" SG_ 2193667331 ENG_FuelCapOpnSta 3;
BA_ "RoutingFactor" SG_ 2193667331 ENG_FuelCapOpnSta 5;
BA_ "Version" SG_ 2193667331 ENG_FuelCapOpnSta "17.12.00";
BA_ "Description" SG_ 2193667331 ENG_EcoDrvActvSta "This signal indicates if Active Eco Drive function is active or not.

If Active Eco Drive function is active, then CF_Ems_ActEcoAct =1.";
BA_ "UserSigValidity" SG_ 2193667331 ENG_EcoDrvActvSta 3;
BA_ "RoutingFactor" SG_ 2193667331 ENG_EcoDrvActvSta 5;
BA_ "Version" SG_ 2193667331 ENG_EcoDrvActvSta "17.12.00";
BA_ "Description" SG_ 2193667331 ENG_EngRunSta "This signal is indicating normal engine running status. When engine is normal engine running state out of start, the signal turns to 1, otherwise 0 including engine stop & starting phase(cranking).";
BA_ "UserSigValidity" SG_ 2193667331 ENG_EngRunSta 3;
BA_ "RoutingFactor" SG_ 2193667331 ENG_EngRunSta 5;
BA_ "Version" SG_ 2193667331 ENG_EngRunSta "17.12.00";
BA_ "Description" SG_ 2193667331 ENG_Isg2Sta "1. ISG Status CAN message is divided by CF_EMS_IsgStat and CF_EMS_IsgStat2 

2. CF_EMS_IsgStat and CF_EMS_IsgStat2 do not duplicate the output condition

(EX: If CF_EMS_IsgStat2 is 01h~03h, CF_EMS_IsgStat is 00h)";
BA_ "UserSigValidity" SG_ 2193667331 ENG_Isg2Sta 3;
BA_ "RoutingFactor" SG_ 2193667331 ENG_Isg2Sta 5;
BA_ "Version" SG_ 2193667331 ENG_Isg2Sta "17.12.00";
BA_ "Description" SG_ 2193667331 ENG_IgnOnSta "Status of ignition lock.";
BA_ "GenSigStartValue" SG_ 2193667331 ENG_IgnOnSta 1;
BA_ "UserSigValidity" SG_ 2193667331 ENG_IgnOnSta 3;
BA_ "RoutingFactor" SG_ 2193667331 ENG_IgnOnSta 5;
BA_ "Version" SG_ 2193667331 ENG_IgnOnSta "17.12.00";
BA_ "Description" SG_ 2193667331 ENG_Ack4TcsSta "Monitoring of TCS message; the EMS checks whether at least one new message has been transferred within 500 ms, and whether there is no plausibility error in conjunction with a torque intervention. If this case occurs, the bit is set; otherwise it is reset.



Plausibility check - torque intervention:

- Test criteria:

TCS mode, criteria C1:

(TCS_REQ=1) & (TQI_TCS<FFH) & (MSR_C_REQ = 0) & (TQI_MSR = 00H)

MSR mode, criteria C2:

(TCS_REQ=0) & (TQI_TCS=1¡¯s complement of TQI_MSR) & (MSR_C_REQ = 1) & (TQI_MSR > 00H)

No intervention, criteria C3 :

(TCS_REQ=0) & (TQI_TCS=FFH) & (MSR_C_REQ = 0) & (TQI_MSR = 00H)



- Criterion for error setting:

C1 v C2 v C3 ¡Á 1 (none of C1,C2 and C3 is true) for n message transmissions TCS1 (n=10)



- Criterion for remedying an error:

Ignition OFF; transmission is re-started if plausibility is OK for at least one CAN transmission.";
BA_ "UserSigValidity" SG_ 2193667331 ENG_Ack4TcsSta 3;
BA_ "RoutingFactor" SG_ 2193667331 ENG_Ack4TcsSta 5;
BA_ "Version" SG_ 2193667331 ENG_Ack4TcsSta "17.12.00";
BA_ "Description" SG_ 2193667331 ENG_FuelCutOffSta "If the PUC_STAT - bit = 1 then the engine is in fuel cut off state, i.e. e. no injection is applied.";
BA_ "UserSigValidity" SG_ 2193667331 ENG_FuelCutOffSta 3;
BA_ "RoutingFactor" SG_ 2193667331 ENG_FuelCutOffSta 5;
BA_ "Version" SG_ 2193667331 ENG_FuelCutOffSta "17.12.00";
BA_ "Description" SG_ 2193667331 ENG_CrctTqSta "The information TQ_COR_STAT informs the TCS or the TCU whether and to which extent injection and ignition interventions are admitted.



0x0:The desired intervention regarding ignition angle retardation and cylinder shut-off is executed. (Default value)/0x1:The desired intervention regarding ignition angle retardation and cylinder shut-off is executed; however, the requested target torque can not be adjusted precisely (torque steps)/0x2:The torque reduction regarding the ignition angle retardation cannot be completely executed. A cylinder shut-off is not possible at this time. Therefore a remaining torque (as difference between TQI_ASR/GS_REQ and TQI_INTV) is present and cannot be reduced./0x3:Due to a failure detected by a diagnosis function of the engine management system, the desired torque intervention for TCS regarding the ignition angle and cylinder shut-off is no longer executed.The torque intervention is terminated, the engine management system resets the requested engine torque to the TQI value using a ramp.";
BA_ "UserSigValidity" SG_ 2193667331 ENG_CrctTqSta 3;
BA_ "RoutingFactor" SG_ 2193667331 ENG_CrctTqSta 5;
BA_ "Version" SG_ 2193667331 ENG_CrctTqSta "17.12.02";
BA_ "Description" SG_ 2193667331 ENG_AirCompRlySta "The signal RLY_AC identifies the activation of the air conditioner compressor relay.";
BA_ "UserSigValidity" SG_ 2193667331 ENG_AirCompRlySta 3;
BA_ "RoutingFactor" SG_ 2193667331 ENG_AirCompRlySta 5;
BA_ "Version" SG_ 2193667331 ENG_AirCompRlySta "17.12.00";
BA_ "Description" SG_ 2193667331 ENG_LnchCntrlSta "State of Launch Control";
BA_ "UserSigValidity" SG_ 2193667331 ENG_LnchCntrlSta 3;
BA_ "RoutingFactor" SG_ 2193667331 ENG_LnchCntrlSta 5;
BA_ "Version" SG_ 2193667331 ENG_LnchCntrlSta "17.11.00";
BA_ "Description" SG_ 2193667331 ENG_EngSpdVal "This signal is generated by crankshaft segment period measurement (in case of an six-cylinder engine, this corresponds to a crankshaft angle of 120¡Æ) and measured with a resolution of 4 us.

This signal is represented as a 16 bit value.



The signal is no";
BA_ "UserSigValidity" SG_ 2193667331 ENG_EngSpdVal 3;
BA_ "RoutingFactor" SG_ 2193667331 ENG_EngSpdVal 5;
BA_ "Version" SG_ 2193667331 ENG_EngSpdVal "17.12.00";
BA_ "Description" SG_ 2193667331 ENG_GearShftUpDis "This signal represents gear shift up display status. EMS transmits gear shift up status to the cluster.";
BA_ "UserSigValidity" SG_ 2193667331 ENG_GearShftUpDis 3;
BA_ "RoutingFactor" SG_ 2193667331 ENG_GearShftUpDis 5;
BA_ "Version" SG_ 2193667331 ENG_GearShftUpDis "17.12.00";
BA_ "GenMsgSendType" BO_ 2193667332 0;
BA_ "GenMsgCycleTime" BO_ 2193667332 50;
BA_ "GenMsgCycleTimeFast" BO_ 2193667332 0;
BA_ "GenMsgNrOfRepetition" BO_ 2193667332 0;
BA_ "VFrameFormat" BO_ 2193667332 1;
BA_ "Description" SG_ 2193667332 ENG_TrgtFuelPmpPrsrVal "This signal indicates the Target Pressure of Fuel Pump";
BA_ "UserSigValidity" SG_ 2193667332 ENG_TrgtFuelPmpPrsrVal 3;
BA_ "RoutingFactor" SG_ 2193667332 ENG_TrgtFuelPmpPrsrVal 5;
BA_ "Version" SG_ 2193667332 ENG_TrgtFuelPmpPrsrVal "17.12.00";
BA_ "Description" SG_ 2193667332 ENG_VehSpdHiVal "This signal provides the one wheel velocity with resolution of 1 km/h,

and have 9 bits lengh.

In case of failure of sheel speed sensor, the value 1FF is used as error identifier";
BA_ "UserSigValidity" SG_ 2193667332 ENG_VehSpdHiVal 3;
BA_ "RoutingFactor" SG_ 2193667332 ENG_VehSpdHiVal 5;
BA_ "Version" SG_ 2193667332 ENG_VehSpdHiVal "18.01.01";
BA_ "Description" SG_ 2193667332 ENG_EngInhbNCC "This signal indicates the Inhibition of NCC MODE";
BA_ "GenSigStartValue" SG_ 2193667332 ENG_EngInhbNCC 1;
BA_ "UserSigValidity" SG_ 2193667332 ENG_EngInhbNCC 3;
BA_ "RoutingFactor" SG_ 2193667332 ENG_EngInhbNCC 5;
BA_ "Version" SG_ 2193667332 ENG_EngInhbNCC "18.04.02";
BA_ "Description" SG_ 2193667332 ENG_SldSwSta "This signal indicates the status of Speed limiter function.";
BA_ "TimeoutValue" SG_ 2193667332 ENG_SldSwSta "0x0";
BA_ "UserSigValidity" SG_ 2193667332 ENG_SldSwSta 3;
BA_ "RoutingFactor" SG_ 2193667332 ENG_SldSwSta 5;
BA_ "Version" SG_ 2193667332 ENG_SldSwSta "19.12.08";
BA_ "Description" SG_ 2193667332 ENG_SldDrvAlertDisp "If EMS sends the No Sld engaged status or Sld Disengaged status, 

Cluster shall display the status of Sld.";
BA_ "TimeoutValue" SG_ 2193667332 ENG_SldDrvAlertDisp "0x0";
BA_ "UserSigValidity" SG_ 2193667332 ENG_SldDrvAlertDisp 3;
BA_ "RoutingFactor" SG_ 2193667332 ENG_SldDrvAlertDisp 5;
BA_ "Version" SG_ 2193667332 ENG_SldDrvAlertDisp "19.12.08";
BA_ "Description" SG_ 2193667332 ENG_VehSpdLimVal "The vehicle speed which is measured by the EMS has to be sent to CLUSTER. This value is used for limiting speed of EMS. 

EMS limite vehicle speed as this value.";
BA_ "UserSigValidity" SG_ 2193667332 ENG_VehSpdLimVal 3;
BA_ "RoutingFactor" SG_ 2193667332 ENG_VehSpdLimVal 5;
BA_ "Version" SG_ 2193667332 ENG_VehSpdLimVal "18.01.01";
BA_ "Description" SG_ 2193667332 ENG_FuelCnsmptVal "The EMS uses the signal 'FCO' (FUEL CONSUMPTION) to inform other ECUs about the current consumption.";
BA_ "UserSigValidity" SG_ 2193667332 ENG_FuelCnsmptVal 3;
BA_ "RoutingFactor" SG_ 2193667332 ENG_FuelCnsmptVal 5;
BA_ "Version" SG_ 2193667332 ENG_FuelCnsmptVal "17.12.00";
BA_ "GenMsgSendType" BO_ 2307024129 0;
BA_ "GenMsgCycleTimeFast" BO_ 2307024129 0;
BA_ "GenMsgNrOfRepetition" BO_ 2307024129 0;
BA_ "VFrameFormat" BO_ 2307024129 1;
BA_ "Description" SG_ 2307024129 EMS_Crc8Val "The data area for CRC calculation is based on the data length (DLC) of the message DB.

The CRC shall be calculated over the entire data block (excluding the CRC bytes) including the user data, alive counter and Data ID

 

- CRC Polynomial (0x1021) , Initial Value : 0xFFFF, XOR value : 0x0000, Data ID : Message ID + 0xF800 

- The initial value is for CRC calculation and the message should be sent with the calculated result value. 

- The mathematical expression to 16 bit CRC polynomial is given here. G(x) = x16 + x12 + x5 + 1";
BA_ "GenSigStartValue" SG_ 2307024129 EMS_Crc8Val 65535;
BA_ "UserSigValidity" SG_ 2307024129 EMS_Crc8Val 3;
BA_ "RoutingFactor" SG_ 2307024129 EMS_Crc8Val 2;
BA_ "Version" SG_ 2307024129 EMS_Crc8Val "18.11.08";
BA_ "Description" SG_ 2307024129 EMS_AlvCnt8Val "For the first transmission request for a data element the counter shall be initialized with 0 and shall be incremented by 1 for every subsequent send request. 

When the counter reaches the maximum value(0xFF), then it shall restart with 0 for the next send request";
BA_ "UserSigValidity" SG_ 2307024129 EMS_AlvCnt8Val 3;
BA_ "RoutingFactor" SG_ 2307024129 EMS_AlvCnt8Val 2;
BA_ "Version" SG_ 2307024129 EMS_AlvCnt8Val "18.11.08";
BA_ "Description" SG_ 2307024129 HEV_EngClntTempVal "Engine coolant temperature";
BA_ "UserSigValidity" SG_ 2307024129 HEV_EngClntTempVal 3;
BA_ "RoutingFactor" SG_ 2307024129 HEV_EngClntTempVal 2;
BA_ "Version" SG_ 2307024129 HEV_EngClntTempVal "17.11.00";
BA_ "Description" SG_ 2307024129 HEV_EngOilTempVal "Engine Oil Temperature";
BA_ "UserSigValidity" SG_ 2307024129 HEV_EngOilTempVal 3;
BA_ "RoutingFactor" SG_ 2307024129 HEV_EngOilTempVal 2;
BA_ "Version" SG_ 2307024129 HEV_EngOilTempVal "17.11.00";
BA_ "Description" SG_ 2307024129 HEV_VbOffActSta "ECU adaptive values and failure memory erase after battery disconnection";
BA_ "UserSigValidity" SG_ 2307024129 HEV_VbOffActSta 3;
BA_ "RoutingFactor" SG_ 2307024129 HEV_VbOffActSta 2;
BA_ "Version" SG_ 2307024129 HEV_VbOffActSta "17.11.00";
BA_ "Description" SG_ 2307024129 HEV_AirCompOffReq "air conditioner compressor off request";
BA_ "UserSigValidity" SG_ 2307024129 HEV_AirCompOffReq 3;
BA_ "RoutingFactor" SG_ 2307024129 HEV_AirCompOffReq 2;
BA_ "Version" SG_ 2307024129 HEV_AirCompOffReq "17.11.00";
BA_ "Description" SG_ 2307024129 HEV_MilConfgVal "Configuration of MIL handing and failure memory management";
BA_ "UserSigValidity" SG_ 2307024129 HEV_MilConfgVal 3;
BA_ "RoutingFactor" SG_ 2307024129 HEV_MilConfgVal 2;
BA_ "Version" SG_ 2307024129 HEV_MilConfgVal "17.11.00";
BA_ "Description" SG_ 2307024129 HEV_CF_EMS_LOCKUP "Engine lock up maintenance request state

0x0 : Engine doesn't require lock up maintenance

0x1 : Engine require lock up mainentance";
BA_ "UserSigValidity" SG_ 2307024129 HEV_CF_EMS_LOCKUP 3;
BA_ "RoutingFactor" SG_ 2307024129 HEV_CF_EMS_LOCKUP 2;
BA_ "Version" SG_ 2307024129 HEV_CF_EMS_LOCKUP "18.10.12";
BA_ "Description" SG_ 2307024129 HEV_OilLvlSta "This signal indicates the replace time of engine oil.";
BA_ "UserSigValidity" SG_ 2307024129 HEV_OilLvlSta 3;
BA_ "RoutingFactor" SG_ 2307024129 HEV_OilLvlSta 2;
BA_ "Version" SG_ 2307024129 HEV_OilLvlSta "20.12.04";
BA_ "Description" SG_ 2307024129 HEV_ImmoLmpReq "Immobilizer Lamp";
BA_ "UserSigValidity" SG_ 2307024129 HEV_ImmoLmpReq 3;
BA_ "RoutingFactor" SG_ 2307024129 HEV_ImmoLmpReq 2;
BA_ "Version" SG_ 2307024129 HEV_ImmoLmpReq "17.11.00";
BA_ "Description" SG_ 2307024129 HEV_MilReq "This signal indicates the status of MIL physical output.";
BA_ "UserSigValidity" SG_ 2307024129 HEV_MilReq 3;
BA_ "RoutingFactor" SG_ 2307024129 HEV_MilReq 2;
BA_ "Version" SG_ 2307024129 HEV_MilReq "17.11.00";
BA_ "Description" SG_ 2307024129 HEV_WiperSwSta "This signal indicates the status of a wiper switch.";
BA_ "UserSigValidity" SG_ 2307024129 HEV_WiperSwSta 3;
BA_ "RoutingFactor" SG_ 2307024129 HEV_WiperSwSta 2;
BA_ "Version" SG_ 2307024129 HEV_WiperSwSta "17.11.00";
BA_ "Description" SG_ 2307024129 HEV_FanOpSta "This signal indicates whether the cooling/condenser fan is operating or not.";
BA_ "UserSigValidity" SG_ 2307024129 HEV_FanOpSta 3;
BA_ "RoutingFactor" SG_ 2307024129 HEV_FanOpSta 2;
BA_ "Version" SG_ 2307024129 HEV_FanOpSta "17.11.00";
BA_ "Description" SG_ 2307024129 HEV_FanSta "This signal indicates the operating state of the cooling/condenser fan.";
BA_ "UserSigValidity" SG_ 2307024129 HEV_FanSta 3;
BA_ "RoutingFactor" SG_ 2307024129 HEV_FanSta 2;
BA_ "Version" SG_ 2307024129 HEV_FanSta "17.11.00";
BA_ "Description" SG_ 2307024129 HEV_BrkLtSwSta "Brake light Switch";
BA_ "UserSigValidity" SG_ 2307024129 HEV_BrkLtSwSta 3;
BA_REL_ "GenSigTimeoutTime" BU_SG_REL_ BLTN_CAM SG_ 2307024129 HEV_BrkLtSwSta 1500;
BA_ "RoutingFactor" SG_ 2307024129 HEV_BrkLtSwSta 2;
BA_ "Version" SG_ 2307024129 HEV_BrkLtSwSta "17.11.00";
BA_ "GenMsgSendType" BO_ 2307024130 0;
BA_ "GenMsgCycleTimeFast" BO_ 2307024130 0;
BA_ "GenMsgNrOfRepetition" BO_ 2307024130 0;
BA_ "VFrameFormat" BO_ 2307024130 1;
BA_ "Description" SG_ 2307024130 HEV_IgnCycCntVal "Number of driving cycle since first ECU power-up. The counter increases each time a driving cycle with engine running for a specified time duration is detected. This value is only initialized with 0 on saved RAM lost (or reprogramming).";
BA_ "UserSigValidity" SG_ 2307024130 HEV_IgnCycCntVal 3;
BA_ "RoutingFactor" SG_ 2307024130 HEV_IgnCycCntVal 2;
BA_ "Version" SG_ 2307024130 HEV_IgnCycCntVal "17.11.00";
BA_ "Description" SG_ 2307024130 HEV_SoakTimeVal "Engine soaking time";
BA_ "UserSigValidity" SG_ 2307024130 HEV_SoakTimeVal 3;
BA_ "RoutingFactor" SG_ 2307024130 HEV_SoakTimeVal 2;
BA_ "Version" SG_ 2307024130 HEV_SoakTimeVal "17.11.00";
BA_ "Description" SG_ 2307024130 HEV_SoakTimeErrSta "If the HEV_SoakTimeErrSta = 1 then the engine is in fuel cut off state, i.e. e. no injection is applied.";
BA_ "UserSigValidity" SG_ 2307024130 HEV_SoakTimeErrSta 3;
BA_ "RoutingFactor" SG_ 2307024130 HEV_SoakTimeErrSta 2;
BA_ "Version" SG_ 2307024130 HEV_SoakTimeErrSta "19.11.11";
BA_ "UserSigValidity" SG_ 2307024130 HEV_SoakTimeOvrSta 3;
BA_ "RoutingFactor" SG_ 2307024130 HEV_SoakTimeOvrSta 2;
BA_ "Version" SG_ 2307024130 HEV_SoakTimeOvrSta "18.12.01";
BA_ "UserSigValidity" SG_ 2307024130 HEV_FuelRunOutSta 3;
BA_ "RoutingFactor" SG_ 2307024130 HEV_FuelRunOutSta 2;
BA_ "Version" SG_ 2307024130 HEV_FuelRunOutSta "17.11.00";
BA_ "UserSigValidity" SG_ 2307024130 HEV_FuelRunOutDetSta 3;
BA_ "RoutingFactor" SG_ 2307024130 HEV_FuelRunOutDetSta 2;
BA_ "Version" SG_ 2307024130 HEV_FuelRunOutDetSta "17.11.00";
BA_ "Description" SG_ 2307024130 HEV_FuelCnsmptSumVal "Fuel Comsumption summed";
BA_ "UserSigValidity" SG_ 2307024130 HEV_FuelCnsmptSumVal 3;
BA_ "RoutingFactor" SG_ 2307024130 HEV_FuelCnsmptSumVal 2;
BA_ "Version" SG_ 2307024130 HEV_FuelCnsmptSumVal "17.11.00";
BA_ "GenMsgSendType" BO_ 2307024131 0;
BA_ "GenMsgCycleTimeFast" BO_ 2307024131 0;
BA_ "GenMsgNrOfRepetition" BO_ 2307024131 0;
BA_ "VFrameFormat" BO_ 2307024131 1;
BA_ "Description" SG_ 2307024131 HEV_EstClntTempVal "Estimated Engine Coolant Temperature";
BA_ "UserSigValidity" SG_ 2307024131 HEV_EstClntTempVal 3;
BA_ "RoutingFactor" SG_ 2307024131 HEV_EstClntTempVal 2;
BA_ "Version" SG_ 2307024131 HEV_EstClntTempVal "17.11.00";
BA_ "Description" SG_ 2307024131 HEV_EstAmbtAirTempVal "Estimated Ambient air temperature";
BA_ "GenSigStartValue" SG_ 2307024131 HEV_EstAmbtAirTempVal 91;
BA_ "UserSigValidity" SG_ 2307024131 HEV_EstAmbtAirTempVal 3;
BA_ "RoutingFactor" SG_ 2307024131 HEV_EstAmbtAirTempVal 2;
BA_ "Version" SG_ 2307024131 HEV_EstAmbtAirTempVal "17.11.00";
BA_ "Description" SG_ 2307024131 HEV_RbmSta "Status of rate-based monitoring



Value Description



Bit0 : minimum trip length condition 

Bit1 : vehicle speed condition 

Bit2 : continuous idle condition 

Bit3 : ambient temperature condition 

Bit4 : maximum altitude condition 

Bit5 : fuel engine operation

Bit6 : cold start condition for HEV";
BA_ "UserSigValidity" SG_ 2307024131 HEV_RbmSta 3;
BA_ "RoutingFactor" SG_ 2307024131 HEV_RbmSta 2;
BA_ "Version" SG_ 2307024131 HEV_RbmSta "19.11.11";
BA_ "Description" SG_ 2307024131 HEV_WarmUpReq_For_DATC "Flag indicating an EMS request not to stop the engine.

 * This signal is for reference on the DATC.

 * This signal is same as HEV_WarmUpReq (@EMS_09_10ms).";
BA_ "UserSigValidity" SG_ 2307024131 HEV_WarmUpReq_For_DATC 3;
BA_ "RoutingFactor" SG_ 2307024131 HEV_WarmUpReq_For_DATC 2;
BA_ "Version" SG_ 2307024131 HEV_WarmUpReq_For_DATC "19.09.04";
BA_ "Description" SG_ 2307024131 HEV_RbmInhbtSta "Inhibition of rate based monitoring";
BA_ "UserSigValidity" SG_ 2307024131 HEV_RbmInhbtSta 3;
BA_ "RoutingFactor" SG_ 2307024131 HEV_RbmInhbtSta 2;
BA_ "Version" SG_ 2307024131 HEV_RbmInhbtSta "17.11.00";
BA_ "Description" SG_ 2307024131 HEV_EhrsTempSta "The  signal is condition about EHRS' temperature";
BA_ "UserSigValidity" SG_ 2307024131 HEV_EhrsTempSta 3;
BA_ "RoutingFactor" SG_ 2307024131 HEV_EhrsTempSta 2;
BA_ "Version" SG_ 2307024131 HEV_EhrsTempSta "17.11.00";
BA_ "Description" SG_ 2307024131 HEV_Aaf_WrnLamp "Air Flap Warning Lamp/Message Request Signal indicates whether Warning Lamp/Message should be displayed in the display screen in order to warn AAF System failure to customer.";
BA_ "UserSigValidity" SG_ 2307024131 HEV_Aaf_WrnLamp 3;
BA_ "RoutingFactor" SG_ 2307024131 HEV_Aaf_WrnLamp 2;
BA_ "Version" SG_ 2307024131 HEV_Aaf_WrnLamp "19.11.11";
BA_ "Description" SG_ 2307024131 HEV_OPSFail "The signal indicates the status of the 'Oil Pressure Warning Lamp'";
BA_ "UserSigValidity" SG_ 2307024131 HEV_OPSFail 3;
BA_ "RoutingFactor" SG_ 2307024131 HEV_OPSFail 2;
BA_ "Version" SG_ 2307024131 HEV_OPSFail "18.05.04";
BA_ "Description" SG_ 2307024131 HEV_EngDsplceTyp "This signal indicates the engine displacement (volume).";
BA_ "UserSigValidity" SG_ 2307024131 HEV_EngDsplceTyp 3;
BA_ "RoutingFactor" SG_ 2307024131 HEV_EngDsplceTyp 2;
BA_ "Version" SG_ 2307024131 HEV_EngDsplceTyp "19.07.01";
BA_ "UserSigValidity" SG_ 2307024131 HEV_EngTyp2 3;
BA_ "RoutingFactor" SG_ 2307024131 HEV_EngTyp2 2;
BA_ "Version" SG_ 2307024131 HEV_EngTyp2 "19.07.01";
BA_ "UserSigValidity" SG_ 2307024131 HEV_EngTyp1 3;
BA_ "RoutingFactor" SG_ 2307024131 HEV_EngTyp1 2;
BA_ "Version" SG_ 2307024131 HEV_EngTyp1 "19.07.01";
BA_ "Description" SG_ 2307024131 HEV_S_F "AMS/ISG system type indicator";
BA_ "UserSigValidity" SG_ 2307024131 HEV_S_F 3;
BA_ "RoutingFactor" SG_ 2307024131 HEV_S_F 2;
BA_ "Version" SG_ 2307024131 HEV_S_F "19.07.01";
BA_ "Description" SG_ 2307024131 HEV_S_F_GEN "system generation type indicator";
BA_ "UserSigValidity" SG_ 2307024131 HEV_S_F_GEN 3;
BA_ "RoutingFactor" SG_ 2307024131 HEV_S_F_GEN 2;
BA_ "Version" SG_ 2307024131 HEV_S_F_GEN "19.07.01";
BA_ "Description" SG_ 2307024131 HEV_AptVal "APT Value";
BA_ "UserSigValidity" SG_ 2307024131 HEV_AptVal 3;
BA_ "RoutingFactor" SG_ 2307024131 HEV_AptVal 2;
BA_ "Version" SG_ 2307024131 HEV_AptVal "17.11.00";
BA_ "GenMsgSendType" BO_ 2307024132 0;
BA_ "GenMsgCycleTimeFast" BO_ 2307024132 0;
BA_ "GenMsgNrOfRepetition" BO_ 2307024132 0;
BA_ "VFrameFormat" BO_ 2307024132 1;
BA_ "Description" SG_ 2307024132 HEV_RbmSta_2nd "Status of rate-based monitoring



Value Description

Bit0 : cold start condition for PHEV

Bit1 : cold start inhibition condition for HEV/PHEV

Bit2 : reserved

Bit3 : reserved

Bit4 : reserved

Bit5 : reserved

Bit6 : reserved";
BA_ "UserSigValidity" SG_ 2307024132 HEV_RbmSta_2nd 3;
BA_ "RoutingFactor" SG_ 2307024132 HEV_RbmSta_2nd 2;
BA_ "Version" SG_ 2307024132 HEV_RbmSta_2nd "19.10.00";
BA_ "Description" SG_ 2307024132 HEV_OilLifeRatio "EMS calculates remaining engine oil life, and Cluster displays this information with % unit, in order to guide driver to change engine oil.";
BA_ "UserSigValidity" SG_ 2307024132 HEV_OilLifeRatio 3;
BA_ "RoutingFactor" SG_ 2307024132 HEV_OilLifeRatio 2;
BA_ "Version" SG_ 2307024132 HEV_OilLifeRatio "20.12.04";
BA_ "Description" SG_ 2307024132 HEV_OilLifeEna "Cluster displays engine oil life warning and life ratio signal if this enabling bit is true.";
BA_ "UserSigValidity" SG_ 2307024132 HEV_OilLifeEna 3;
BA_ "RoutingFactor" SG_ 2307024132 HEV_OilLifeEna 2;
BA_ "Version" SG_ 2307024132 HEV_OilLifeEna "20.12.04";
BA_ "Description" SG_ 2307024132 HEV_OilLifeWarn "This signal indicates status of engine oil life warning.";
BA_ "UserSigValidity" SG_ 2307024132 HEV_OilLifeWarn 3;
BA_ "RoutingFactor" SG_ 2307024132 HEV_OilLifeWarn 2;
BA_ "Version" SG_ 2307024132 HEV_OilLifeWarn "20.12.04";
BA_ "Description" SG_ 2307024132 HEV_RECTrigSta "Trigger signal(10 event) - when REC is occurred in the HEV ECU(Engine controller)";
BA_ "UserSigValidity" SG_ 2307024132 HEV_RECTrigSta 3;
BA_ "RoutingFactor" SG_ 2307024132 HEV_RECTrigSta 2;
BA_ "Version" SG_ 2307024132 HEV_RECTrigSta "20.02.02";
BA_ "Description" SG_ 2307024132 HEV_PendingTrigSta "Trigger signal(10 event) - when Pending DTC is occurred in the HEV ECU(Engine controller)";
BA_ "UserSigValidity" SG_ 2307024132 HEV_PendingTrigSta 3;
BA_ "RoutingFactor" SG_ 2307024132 HEV_PendingTrigSta 2;
BA_ "Version" SG_ 2307024132 HEV_PendingTrigSta "20.02.02";
BA_ "GenMsgCycleTime" BO_ 1907 0;
BA_ "GenMsgCycleTimeFast" BO_ 1907 0;
BA_ "GenMsgNrOfRepetition" BO_ 1907 0;
BA_ "DiagRequest" BO_ 1907 1;
BA_ "GenMsgILSupport" BO_ 1907 0;
BA_ "TpMessage" BO_ 1907 1;
BA_ "TpTxIndex" BO_ 1907 158;
BA_ "Description" SG_ 1907 GST_RARS_Byte0 "TP Index : 158";
BA_ "UsrSigPurpose" SG_ 1907 GST_RARS_Byte0 3;
BA_ "UserSigValidity" SG_ 1907 GST_RARS_Byte0 0;
BA_REL_ "GenSigTimeoutTime" BU_SG_REL_ ARS SG_ 1907 GST_RARS_Byte0 0;
BA_ "NetworkRequest" SG_ 1907 GST_RARS_Byte0 0;
BA_ "NetworkRequestHoldingTime" SG_ 1907 GST_RARS_Byte0 5000;
BA_ "Version" SG_ 1907 GST_RARS_Byte0 "21.02.04";
BA_ "Description" SG_ 1907 GST_RARS_Byte2 "TP Index : 158";
BA_ "UsrSigPurpose" SG_ 1907 GST_RARS_Byte2 3;
BA_ "UserSigValidity" SG_ 1907 GST_RARS_Byte2 0;
BA_REL_ "GenSigTimeoutTime" BU_SG_REL_ ARS SG_ 1907 GST_RARS_Byte2 0;
BA_ "NetworkRequest" SG_ 1907 GST_RARS_Byte2 0;
BA_ "NetworkRequestHoldingTime" SG_ 1907 GST_RARS_Byte2 5000;
BA_ "Version" SG_ 1907 GST_RARS_Byte2 "21.02.04";
BA_ "Description" SG_ 1907 GST_RARS_Byte3 "TP Index : 158";
BA_ "UsrSigPurpose" SG_ 1907 GST_RARS_Byte3 3;
BA_ "UserSigValidity" SG_ 1907 GST_RARS_Byte3 0;
BA_REL_ "GenSigTimeoutTime" BU_SG_REL_ ARS SG_ 1907 GST_RARS_Byte3 0;
BA_ "NetworkRequest" SG_ 1907 GST_RARS_Byte3 0;
BA_ "NetworkRequestHoldingTime" SG_ 1907 GST_RARS_Byte3 5000;
BA_ "Version" SG_ 1907 GST_RARS_Byte3 "21.02.04";
BA_ "Description" SG_ 1907 GST_RARS_Byte4 "TP Index : 158";
BA_ "UsrSigPurpose" SG_ 1907 GST_RARS_Byte4 3;
BA_ "UserSigValidity" SG_ 1907 GST_RARS_Byte4 0;
BA_REL_ "GenSigTimeoutTime" BU_SG_REL_ ARS SG_ 1907 GST_RARS_Byte4 0;
BA_ "NetworkRequest" SG_ 1907 GST_RARS_Byte4 0;
BA_ "NetworkRequestHoldingTime" SG_ 1907 GST_RARS_Byte4 5000;
BA_ "Version" SG_ 1907 GST_RARS_Byte4 "21.02.04";
BA_ "Description" SG_ 1907 GST_RARS_Byte5 "TP Index : 158";
BA_ "UsrSigPurpose" SG_ 1907 GST_RARS_Byte5 3;
BA_ "UserSigValidity" SG_ 1907 GST_RARS_Byte5 0;
BA_REL_ "GenSigTimeoutTime" BU_SG_REL_ ARS SG_ 1907 GST_RARS_Byte5 0;
BA_ "NetworkRequest" SG_ 1907 GST_RARS_Byte5 0;
BA_ "NetworkRequestHoldingTime" SG_ 1907 GST_RARS_Byte5 5000;
BA_ "Version" SG_ 1907 GST_RARS_Byte5 "21.02.04";
BA_ "Description" SG_ 1907 GST_RARS_Byte6 "TP Index : 158";
BA_ "UsrSigPurpose" SG_ 1907 GST_RARS_Byte6 3;
BA_ "UserSigValidity" SG_ 1907 GST_RARS_Byte6 0;
BA_REL_ "GenSigTimeoutTime" BU_SG_REL_ ARS SG_ 1907 GST_RARS_Byte6 0;
BA_ "NetworkRequest" SG_ 1907 GST_RARS_Byte6 0;
BA_ "NetworkRequestHoldingTime" SG_ 1907 GST_RARS_Byte6 5000;
BA_ "Version" SG_ 1907 GST_RARS_Byte6 "21.02.04";
BA_ "Description" SG_ 1907 GST_RARS_Byte7 "TP Index : 158";
BA_ "UsrSigPurpose" SG_ 1907 GST_RARS_Byte7 3;
BA_ "UserSigValidity" SG_ 1907 GST_RARS_Byte7 0;
BA_REL_ "GenSigTimeoutTime" BU_SG_REL_ ARS SG_ 1907 GST_RARS_Byte7 0;
BA_ "NetworkRequest" SG_ 1907 GST_RARS_Byte7 0;
BA_ "NetworkRequestHoldingTime" SG_ 1907 GST_RARS_Byte7 5000;
BA_ "Version" SG_ 1907 GST_RARS_Byte7 "21.02.04";
BA_ "Description" SG_ 1907 GST_RARS_Byte1 "TP Index : 158";
BA_ "UsrSigPurpose" SG_ 1907 GST_RARS_Byte1 3;
BA_ "UserSigValidity" SG_ 1907 GST_RARS_Byte1 0;
BA_REL_ "GenSigTimeoutTime" BU_SG_REL_ ARS SG_ 1907 GST_RARS_Byte1 0;
BA_ "NetworkRequest" SG_ 1907 GST_RARS_Byte1 0;
BA_ "NetworkRequestHoldingTime" SG_ 1907 GST_RARS_Byte1 5000;
BA_ "Version" SG_ 1907 GST_RARS_Byte1 "21.02.04";
BA_ "GenMsgSendType" BO_ 1189 0;
BA_ "GenMsgStartDelayTime" BO_ 1189 80;
BA_ "Description" SG_ 1189 C_RLTiltUpSw_HU "18.10.03_2nd Left side seat Moving control : Tilt Up";
BA_ "GenSigSendType" SG_ 1189 C_RLTiltUpSw_HU 4;
BA_ "UserSigValidity" SG_ 1189 C_RLTiltUpSw_HU 0;
BA_REL_ "GenSigTimeoutTime" BU_SG_REL_ APSU SG_ 1189 C_RLTiltUpSw_HU 1500;
BA_REL_ "GenSigTimeoutTime" BU_SG_REL_ RRPSU SG_ 1189 C_RLTiltUpSw_HU 1500;
BA_REL_ "GenSigTimeoutTime" BU_SG_REL_ RLPSU SG_ 1189 C_RLTiltUpSw_HU 1500;
BA_ "Version" SG_ 1189 C_RLTiltUpSw_HU "18.10.03";
BA_ "Description" SG_ 1189 C_RRTiltDownSw_HU "18.10.03_2nd Right side seat Moving control : Tilt Down";
BA_ "GenSigSendType" SG_ 1189 C_RRTiltDownSw_HU 4;
BA_ "UserSigValidity" SG_ 1189 C_RRTiltDownSw_HU 0;
BA_REL_ "GenSigTimeoutTime" BU_SG_REL_ APSU SG_ 1189 C_RRTiltDownSw_HU 1500;
BA_REL_ "GenSigTimeoutTime" BU_SG_REL_ RRPSU SG_ 1189 C_RRTiltDownSw_HU 1500;
BA_REL_ "GenSigTimeoutTime" BU_SG_REL_ RLPSU SG_ 1189 C_RRTiltDownSw_HU 1500;
BA_ "Version" SG_ 1189 C_RRTiltDownSw_HU "18.10.03";
BA_ "Description" SG_ 1189 C_RRTiltUpSw_HU "18.10.03_2nd Right side seat Moving control : Tilt Up";
BA_ "GenSigSendType" SG_ 1189 C_RRTiltUpSw_HU 4;
BA_ "UserSigValidity" SG_ 1189 C_RRTiltUpSw_HU 0;
BA_REL_ "GenSigTimeoutTime" BU_SG_REL_ APSU SG_ 1189 C_RRTiltUpSw_HU 1500;
BA_REL_ "GenSigTimeoutTime" BU_SG_REL_ RRPSU SG_ 1189 C_RRTiltUpSw_HU 1500;
BA_REL_ "GenSigTimeoutTime" BU_SG_REL_ RLPSU SG_ 1189 C_RRTiltUpSw_HU 1500;
BA_ "Version" SG_ 1189 C_RRTiltUpSw_HU "18.10.03";
BA_ "Description" SG_ 1189 C_RLRclBwdSw_HU "18.10.03_2nd Left side seat Moving control :Recline Backward";
BA_ "GenSigSendType" SG_ 1189 C_RLRclBwdSw_HU 4;
BA_ "UserSigValidity" SG_ 1189 C_RLRclBwdSw_HU 0;
BA_REL_ "GenSigTimeoutTime" BU_SG_REL_ APSU SG_ 1189 C_RLRclBwdSw_HU 1500;
BA_REL_ "GenSigTimeoutTime" BU_SG_REL_ RRPSU SG_ 1189 C_RLRclBwdSw_HU 1500;
BA_REL_ "GenSigTimeoutTime" BU_SG_REL_ RLPSU SG_ 1189 C_RLRclBwdSw_HU 1500;
BA_ "Version" SG_ 1189 C_RLRclBwdSw_HU "18.10.03";
BA_ "Description" SG_ 1189 C_RLRclFwdSw_HU "18.10.03_2nd Left side seat Moving control : Recline Forward";
BA_ "GenSigSendType" SG_ 1189 C_RLRclFwdSw_HU 4;
BA_ "UserSigValidity" SG_ 1189 C_RLRclFwdSw_HU 0;
BA_REL_ "GenSigTimeoutTime" BU_SG_REL_ APSU SG_ 1189 C_RLRclFwdSw_HU 1500;
BA_REL_ "GenSigTimeoutTime" BU_SG_REL_ RRPSU SG_ 1189 C_RLRclFwdSw_HU 1500;
BA_REL_ "GenSigTimeoutTime" BU_SG_REL_ RLPSU SG_ 1189 C_RLRclFwdSw_HU 1500;
BA_ "Version" SG_ 1189 C_RLRclFwdSw_HU "18.10.03";
BA_ "Description" SG_ 1189 C_RLFldSw_HU "18.10.03_2nd Left side seat folding control : Folding";
BA_ "GenSigSendType" SG_ 1189 C_RLFldSw_HU 4;
BA_ "UserSigValidity" SG_ 1189 C_RLFldSw_HU 0;
BA_REL_ "GenSigTimeoutTime" BU_SG_REL_ RLPSU SG_ 1189 C_RLFldSw_HU 1500;
BA_ "Version" SG_ 1189 C_RLFldSw_HU "18.10.03";
BA_ "Description" SG_ 1189 C_RRRclBwdSw_HU "18.10.03_2nd Right side seat Moving control :Recline Backward";
BA_ "GenSigSendType" SG_ 1189 C_RRRclBwdSw_HU 4;
BA_ "UserSigValidity" SG_ 1189 C_RRRclBwdSw_HU 0;
BA_REL_ "GenSigTimeoutTime" BU_SG_REL_ APSU SG_ 1189 C_RRRclBwdSw_HU 1500;
BA_REL_ "GenSigTimeoutTime" BU_SG_REL_ RRPSU SG_ 1189 C_RRRclBwdSw_HU 1500;
BA_REL_ "GenSigTimeoutTime" BU_SG_REL_ RLPSU SG_ 1189 C_RRRclBwdSw_HU 1500;
BA_ "Version" SG_ 1189 C_RRRclBwdSw_HU "18.10.03";
BA_ "Description" SG_ 1189 C_RRRclFwdSw_HU "18.10.03_2nd Right side seat Moving control :Recline Forward";
BA_ "GenSigSendType" SG_ 1189 C_RRRclFwdSw_HU 4;
BA_ "UserSigValidity" SG_ 1189 C_RRRclFwdSw_HU 0;
BA_REL_ "GenSigTimeoutTime" BU_SG_REL_ APSU SG_ 1189 C_RRRclFwdSw_HU 1500;
BA_REL_ "GenSigTimeoutTime" BU_SG_REL_ RRPSU SG_ 1189 C_RRRclFwdSw_HU 1500;
BA_REL_ "GenSigTimeoutTime" BU_SG_REL_ RLPSU SG_ 1189 C_RRRclFwdSw_HU 1500;
BA_ "Version" SG_ 1189 C_RRRclFwdSw_HU "18.10.03";
BA_ "Description" SG_ 1189 C_TLHrestFldSw_HU "18.10.03_3rdLeft side seat Headrest folding control : Folding";
BA_ "GenSigSendType" SG_ 1189 C_TLHrestFldSw_HU 4;
BA_ "UserSigValidity" SG_ 1189 C_TLHrestFldSw_HU 0;
BA_REL_ "GenSigTimeoutTime" BU_SG_REL_ PFSU SG_ 1189 C_TLHrestFldSw_HU 1500;
BA_ "Version" SG_ 1189 C_TLHrestFldSw_HU "18.10.03";
BA_ "Description" SG_ 1189 C_TRHrestFldSw_HU "18.10.03_3rd Right side seat Headrest folding control : Folding";
BA_ "GenSigSendType" SG_ 1189 C_TRHrestFldSw_HU 4;
BA_ "UserSigValidity" SG_ 1189 C_TRHrestFldSw_HU 0;
BA_REL_ "GenSigTimeoutTime" BU_SG_REL_ PFSU SG_ 1189 C_TRHrestFldSw_HU 1500;
BA_ "Version" SG_ 1189 C_TRHrestFldSw_HU "18.10.03";
BA_ "Description" SG_ 1189 C_RLRlxSW_HU "18.10.03_2nd Left side seat Moving control : Relax mode";
BA_ "GenSigSendType" SG_ 1189 C_RLRlxSW_HU 4;
BA_ "UserSigValidity" SG_ 1189 C_RLRlxSW_HU 0;
BA_REL_ "GenSigTimeoutTime" BU_SG_REL_ RRPSU SG_ 1189 C_RLRlxSW_HU 1500;
BA_REL_ "GenSigTimeoutTime" BU_SG_REL_ RLPSU SG_ 1189 C_RLRlxSW_HU 1500;
BA_ "Version" SG_ 1189 C_RLRlxSW_HU "18.10.03";
BA_ "Description" SG_ 1189 C_RRRlxSW_HU "18.10.03_2nd Right side seat Moving control : Relax mode";
BA_ "GenSigSendType" SG_ 1189 C_RRRlxSW_HU 4;
BA_ "UserSigValidity" SG_ 1189 C_RRRlxSW_HU 0;
BA_REL_ "GenSigTimeoutTime" BU_SG_REL_ RRPSU SG_ 1189 C_RRRlxSW_HU 1500;
BA_ "Version" SG_ 1189 C_RRRlxSW_HU "18.10.03";
BA_ "Description" SG_ 1189 C_TLFldSw_HU "18.10.03_3rd Left side seat folding control : Folding";
BA_ "GenSigSendType" SG_ 1189 C_TLFldSw_HU 4;
BA_ "UserSigValidity" SG_ 1189 C_TLFldSw_HU 0;
BA_REL_ "GenSigTimeoutTime" BU_SG_REL_ PFSU SG_ 1189 C_TLFldSw_HU 1500;
BA_ "Version" SG_ 1189 C_TLFldSw_HU "18.10.03";
BA_ "Description" SG_ 1189 C_TRFldSw_HU "18.10.03_3rd Right side seat folding control : Folding";
BA_ "GenSigSendType" SG_ 1189 C_TRFldSw_HU 4;
BA_ "UserSigValidity" SG_ 1189 C_TRFldSw_HU 0;
BA_REL_ "GenSigTimeoutTime" BU_SG_REL_ PFSU SG_ 1189 C_TRFldSw_HU 1500;
BA_ "Version" SG_ 1189 C_TRFldSw_HU "18.10.03";
BA_ "Description" SG_ 1189 C_RRFldSw_HU "18.10.03_2nd Right side seat folding control : Folding";
BA_ "GenSigSendType" SG_ 1189 C_RRFldSw_HU 4;
BA_ "UserSigValidity" SG_ 1189 C_RRFldSw_HU 0;
BA_REL_ "GenSigTimeoutTime" BU_SG_REL_ RRPSU SG_ 1189 C_RRFldSw_HU 1500;
BA_ "Version" SG_ 1189 C_RRFldSw_HU "18.10.03";
BA_ "Description" SG_ 1189 C_RLTiltDownSw_HU "18.10.03_2ndLeft side seat Moving control : Tilt Down";
BA_ "GenSigSendType" SG_ 1189 C_RLTiltDownSw_HU 4;
BA_ "UserSigValidity" SG_ 1189 C_RLTiltDownSw_HU 0;
BA_REL_ "GenSigTimeoutTime" BU_SG_REL_ APSU SG_ 1189 C_RLTiltDownSw_HU 1500;
BA_REL_ "GenSigTimeoutTime" BU_SG_REL_ RRPSU SG_ 1189 C_RLTiltDownSw_HU 1500;
BA_REL_ "GenSigTimeoutTime" BU_SG_REL_ RLPSU SG_ 1189 C_RLTiltDownSw_HU 1500;
BA_ "Version" SG_ 1189 C_RLTiltDownSw_HU "18.10.03";
BA_ "GenMsgCycleTime" BO_ 1185 0;
BA_ "GenSigSendType" SG_ 1185 C_AstWindowCmdAVN 4;
BA_ "GenSigStartValue" SG_ 1185 C_AstWindowCmdAVN 15;
BA_ "UserSigValidity" SG_ 1185 C_AstWindowCmdAVN 0;
BA_ "Version" SG_ 1185 C_AstWindowCmdAVN "19.11.05";
BA_ "Description" SG_ 1185 C_RrDefoggerCmdAVN "18.08.09_";
BA_ "GenSigSendType" SG_ 1185 C_RrDefoggerCmdAVN 4;
BA_ "GenSigStartValue" SG_ 1185 C_RrDefoggerCmdAVN 3;
BA_ "UserSigValidity" SG_ 1185 C_RrDefoggerCmdAVN 3;
BA_ "Version" SG_ 1185 C_RrDefoggerCmdAVN "18.09.02";
BA_ "Description" SG_ 1185 C_RrBlindCmdAVN "Rear sunroof control signal(blind)";
BA_ "GenSigSendType" SG_ 1185 C_RrBlindCmdAVN 4;
BA_ "GenSigStartValue" SG_ 1185 C_RrBlindCmdAVN 3;
BA_ "UserSigValidity" SG_ 1185 C_RrBlindCmdAVN 3;
BA_REL_ "GenSigTimeoutTime" BU_SG_REL_ RCM SG_ 1185 C_RrBlindCmdAVN 0;
BA_ "Version" SG_ 1185 C_RrBlindCmdAVN "22.02.04";
BA_ "Description" SG_ 1185 C_RrGlassCmdAVN "Rear sunroof control signal(glass)";
BA_ "GenSigSendType" SG_ 1185 C_RrGlassCmdAVN 4;
BA_ "GenSigStartValue" SG_ 1185 C_RrGlassCmdAVN 3;
BA_ "UserSigValidity" SG_ 1185 C_RrGlassCmdAVN 3;
BA_REL_ "GenSigTimeoutTime" BU_SG_REL_ RCM SG_ 1185 C_RrGlassCmdAVN 0;
BA_ "Version" SG_ 1185 C_RrGlassCmdAVN "22.02.04";
BA_ "GenSigSendType" SG_ 1185 C_RRWindowCmdAVN 4;
BA_ "GenSigStartValue" SG_ 1185 C_RRWindowCmdAVN 15;
BA_ "UserSigValidity" SG_ 1185 C_RRWindowCmdAVN 0;
BA_ "Version" SG_ 1185 C_RRWindowCmdAVN "19.11.05";
BA_ "GenSigSendType" SG_ 1185 C_RLWindowCmdAVN 4;
BA_ "GenSigStartValue" SG_ 1185 C_RLWindowCmdAVN 15;
BA_ "UserSigValidity" SG_ 1185 C_RLWindowCmdAVN 0;
BA_ "Version" SG_ 1185 C_RLWindowCmdAVN "19.11.05";
BA_ "Description" SG_ 1185 C_BlindCmdAVN "18.08.09_";
BA_ "GenSigSendType" SG_ 1185 C_BlindCmdAVN 4;
BA_ "GenSigStartValue" SG_ 1185 C_BlindCmdAVN 7;
BA_ "UserSigValidity" SG_ 1185 C_BlindCmdAVN 1;
BA_REL_ "GenSigTimeoutTime" BU_SG_REL_ RCM SG_ 1185 C_BlindCmdAVN 0;
BA_ "Version" SG_ 1185 C_BlindCmdAVN "18.09.02";
BA_ "Description" SG_ 1185 C_GlassCmdAVN "18.08.09_";
BA_ "GenSigSendType" SG_ 1185 C_GlassCmdAVN 4;
BA_ "GenSigStartValue" SG_ 1185 C_GlassCmdAVN 7;
BA_ "UserSigValidity" SG_ 1185 C_GlassCmdAVN 1;
BA_REL_ "GenSigTimeoutTime" BU_SG_REL_ RCM SG_ 1185 C_GlassCmdAVN 0;
BA_ "Version" SG_ 1185 C_GlassCmdAVN "18.09.02";
BA_ "GenSigSendType" SG_ 1185 C_DrvWindowCmdAVN 4;
BA_ "GenSigStartValue" SG_ 1185 C_DrvWindowCmdAVN 15;
BA_ "UserSigValidity" SG_ 1185 C_DrvWindowCmdAVN 0;
BA_ "Version" SG_ 1185 C_DrvWindowCmdAVN "19.11.05";
BA_ "Description" SG_ 1185 C_PTGCNTLCmdAVN "18.08.09_";
BA_ "GenSigSendType" SG_ 1185 C_PTGCNTLCmdAVN 4;
BA_ "GenSigStartValue" SG_ 1185 C_PTGCNTLCmdAVN 3;
BA_ "UserSigValidity" SG_ 1185 C_PTGCNTLCmdAVN 3;
BA_ "Version" SG_ 1185 C_PTGCNTLCmdAVN "18.09.02";
BA_ "GenMsgSendType" BO_ 721 0;
BA_ "GenMsgCycleTime" BO_ 721 100;
BA_ "GenMsgCycleTimeFast" BO_ 721 0;
BA_ "GenMsgNrOfRepetition" BO_ 721 0;
BA_ "Description" SG_ 721 HU_DR_Position_Status "0x1:Valid";
BA_ "UserSigValidity" SG_ 721 HU_DR_Position_Status 1;
BA_ "Version" SG_ 721 HU_DR_Position_Status "21.08.01";
BA_ "Description" SG_ 721 HU_DR_Altitude_Status "0x1=Valid";
BA_ "UserSigValidity" SG_ 721 HU_DR_Altitude_Status 1;
BA_ "Version" SG_ 721 HU_DR_Altitude_Status "21.08.01";
BA_ "Description" SG_ 721 HU_DR_Altitude "MSL";
BA_ "UserSigValidity" SG_ 721 HU_DR_Altitude 1;
BA_REL_ "GenSigTimeoutTime" BU_SG_REL_ BLTN_CAM SG_ 721 HU_DR_Altitude 1500;
BA_ "Version" SG_ 721 HU_DR_Altitude "21.08.01";
BA_ "Description" SG_ 721 HU_DR_Heading_Status "0x1=Valid";
BA_ "UserSigValidity" SG_ 721 HU_DR_Heading_Status 1;
BA_ "Version" SG_ 721 HU_DR_Heading_Status "21.08.01";
BA_ "Description" SG_ 721 HU_DR_Speed_Status "0x1=Valid";
BA_ "UserSigValidity" SG_ 721 HU_DR_Speed_Status 1;
BA_ "Version" SG_ 721 HU_DR_Speed_Status "21.08.01";
BA_ "Description" SG_ 721 HU_DR_DirectionSwitch_Sta "0x1=valid";
BA_ "UserSigValidity" SG_ 721 HU_DR_DirectionSwitch_Sta 1;
BA_ "Version" SG_ 721 HU_DR_DirectionSwitch_Sta "21.08.01";
BA_ "Description" SG_ 721 HU_DR_Direction "0x1=Backward";
BA_ "UserSigValidity" SG_ 721 HU_DR_Direction 1;
BA_ "Version" SG_ 721 HU_DR_Direction "21.08.01";
BA_ "Description" SG_ 721 HU_DR_GyroCalib_Sta "0x1=Calibrated";
BA_ "UserSigValidity" SG_ 721 HU_DR_GyroCalib_Sta 1;
BA_ "Version" SG_ 721 HU_DR_GyroCalib_Sta "21.08.01";
BA_ "Description" SG_ 721 HU_DR_TachoCalib_Sta "0x1=Calibrated";
BA_ "UserSigValidity" SG_ 721 HU_DR_TachoCalib_Sta 1;
BA_ "Version" SG_ 721 HU_DR_TachoCalib_Sta "21.08.01";
BA_ "Description" SG_ 721 HU_DR_Solution_Sta "0x1 : Dr is fully calibrated and DR position is valid";
BA_ "UserSigValidity" SG_ 721 HU_DR_Solution_Sta 1;
BA_ "Version" SG_ 721 HU_DR_Solution_Sta "21.08.01";
BA_ "Description" SG_ 721 HU_DR_GNSS_Fix_Age "0-254 = Time since last GNSS fix

255= No GNSS fix yet";
BA_ "UserSigValidity" SG_ 721 HU_DR_GNSS_Fix_Age 1;
BA_ "Version" SG_ 721 HU_DR_GNSS_Fix_Age "21.08.01";
BA_ "GenMsgSendType" BO_ 722 0;
BA_ "GenMsgCycleTime" BO_ 722 100;
BA_ "GenMsgCycleTimeFast" BO_ 722 0;
BA_ "GenMsgNrOfRepetition" BO_ 722 0;
BA_ "UserSigValidity" SG_ 722 HU_DR_Latitude 1;
BA_REL_ "GenSigTimeoutTime" BU_SG_REL_ BLTN_CAM SG_ 722 HU_DR_Latitude 1500;
BA_ "Version" SG_ 722 HU_DR_Latitude "21.08.01";
BA_ "UserSigValidity" SG_ 722 HU_DR_Longitude 1;
BA_REL_ "GenSigTimeoutTime" BU_SG_REL_ BLTN_CAM SG_ 722 HU_DR_Longitude 1500;
BA_ "Version" SG_ 722 HU_DR_Longitude "21.08.01";
BA_ "GenMsgSendType" BO_ 723 0;
BA_ "GenMsgCycleTime" BO_ 723 100;
BA_ "GenMsgCycleTimeFast" BO_ 723 0;
BA_ "GenMsgNrOfRepetition" BO_ 723 0;
BA_ "UserSigValidity" SG_ 723 HU_DR_Heading 1;
BA_REL_ "GenSigTimeoutTime" BU_SG_REL_ BLTN_CAM SG_ 723 HU_DR_Heading 1500;
BA_ "Version" SG_ 723 HU_DR_Heading "21.08.01";
BA_ "Description" SG_ 723 HU_DR_Speed "negative if the direction is backward.";
BA_ "UserSigValidity" SG_ 723 HU_DR_Speed 1;
BA_ "Version" SG_ 723 HU_DR_Speed "21.08.01";
BA_ "GenMsgCycleTime" BO_ 1186 0;
BA_ "Description" SG_ 1186 C_RemoteWdwCMDHU "18.09.06_";
BA_ "GenSigSendType" SG_ 1186 C_RemoteWdwCMDHU 4;
BA_ "GenSigStartValue" SG_ 1186 C_RemoteWdwCMDHU 3;
BA_ "UserSigValidity" SG_ 1186 C_RemoteWdwCMDHU 0;
BA_ "Version" SG_ 1186 C_RemoteWdwCMDHU "18.10.05";
BA_ "Description" SG_ 1186 HU_CDMOpenCmd "Command for CDM open/close";
BA_ "GenSigSendType" SG_ 1186 HU_CDMOpenCmd 4;
BA_ "UserSigValidity" SG_ 1186 HU_CDMOpenCmd 7;
BA_ "Version" SG_ 1186 HU_CDMOpenCmd "20.01.02";
BA_ "Description" SG_ 1186 C_PreCrankReq "18.08.09_Remote Control message";
BA_ "GenSigSendType" SG_ 1186 C_PreCrankReq 4;
BA_ "UserSigValidity" SG_ 1186 C_PreCrankReq 0;
BA_REL_ "GenSigTimeoutTime" BU_SG_REL_ BLTN_CAM SG_ 1186 C_PreCrankReq 0;
BA_ "NetworkRequest" SG_ 1186 C_PreCrankReq 0;
BA_ "Version" SG_ 1186 C_PreCrankReq "18.09.04";
BA_ "Description" SG_ 1186 C_TeleAstSeatOpCmdIBOX "18.08.09_Remote Control message";
BA_ "GenSigSendType" SG_ 1186 C_TeleAstSeatOpCmdIBOX 4;
BA_ "UserSigValidity" SG_ 1186 C_TeleAstSeatOpCmdIBOX 3;
BA_REL_ "GenSigTimeoutTime" BU_SG_REL_ APSU SG_ 1186 C_TeleAstSeatOpCmdIBOX 0;
BA_REL_ "GenSigTimeoutTime" BU_SG_REL_ SHVU_FR SG_ 1186 C_TeleAstSeatOpCmdIBOX 0;
BA_ "Version" SG_ 1186 C_TeleAstSeatOpCmdIBOX "18.09.04";
BA_ "Description" SG_ 1186 C_TeleDrvSeatOpCmdIBOX "18.08.09_Remote Control message";
BA_ "GenSigSendType" SG_ 1186 C_TeleDrvSeatOpCmdIBOX 4;
BA_ "UserSigValidity" SG_ 1186 C_TeleDrvSeatOpCmdIBOX 3;
BA_REL_ "GenSigTimeoutTime" BU_SG_REL_ SHVU_FR SG_ 1186 C_TeleDrvSeatOpCmdIBOX 0;
BA_REL_ "GenSigTimeoutTime" BU_SG_REL_ DPSU SG_ 1186 C_TeleDrvSeatOpCmdIBOX 0;
BA_ "Version" SG_ 1186 C_TeleDrvSeatOpCmdIBOX "18.09.04";
BA_ "Description" SG_ 1186 C_TeleRRSeatOpCmdIBOX "18.08.09_Remote Control message";
BA_ "GenSigSendType" SG_ 1186 C_TeleRRSeatOpCmdIBOX 4;
BA_ "UserSigValidity" SG_ 1186 C_TeleRRSeatOpCmdIBOX 3;
BA_REL_ "GenSigTimeoutTime" BU_SG_REL_ RRHV SG_ 1186 C_TeleRRSeatOpCmdIBOX 0;
BA_REL_ "GenSigTimeoutTime" BU_SG_REL_ SHVU_FR SG_ 1186 C_TeleRRSeatOpCmdIBOX 0;
BA_REL_ "GenSigTimeoutTime" BU_SG_REL_ SHVU_RR SG_ 1186 C_TeleRRSeatOpCmdIBOX 0;
BA_REL_ "GenSigTimeoutTime" BU_SG_REL_ RRPSU SG_ 1186 C_TeleRRSeatOpCmdIBOX 0;
BA_REL_ "GenSigTimeoutTime" BU_SG_REL_ RLPSU SG_ 1186 C_TeleRRSeatOpCmdIBOX 0;
BA_REL_ "GenSigTimeoutTime" BU_SG_REL_ ATS SG_ 1186 C_TeleRRSeatOpCmdIBOX 0;
BA_ "Version" SG_ 1186 C_TeleRRSeatOpCmdIBOX "18.09.04";
BA_ "Description" SG_ 1186 C_TeleRLSeatOpCmdIBOX "18.08.09_Remote Control message";
BA_ "GenSigSendType" SG_ 1186 C_TeleRLSeatOpCmdIBOX 4;
BA_ "UserSigValidity" SG_ 1186 C_TeleRLSeatOpCmdIBOX 3;
BA_REL_ "GenSigTimeoutTime" BU_SG_REL_ RLHV SG_ 1186 C_TeleRLSeatOpCmdIBOX 0;
BA_REL_ "GenSigTimeoutTime" BU_SG_REL_ SHVU_FR SG_ 1186 C_TeleRLSeatOpCmdIBOX 0;
BA_REL_ "GenSigTimeoutTime" BU_SG_REL_ SHVU_RR SG_ 1186 C_TeleRLSeatOpCmdIBOX 0;
BA_REL_ "GenSigTimeoutTime" BU_SG_REL_ RRPSU SG_ 1186 C_TeleRLSeatOpCmdIBOX 0;
BA_REL_ "GenSigTimeoutTime" BU_SG_REL_ RLPSU SG_ 1186 C_TeleRLSeatOpCmdIBOX 0;
BA_REL_ "GenSigTimeoutTime" BU_SG_REL_ ATS SG_ 1186 C_TeleRLSeatOpCmdIBOX 0;
BA_ "Version" SG_ 1186 C_TeleRLSeatOpCmdIBOX "18.09.04";
BA_ "GenMsgCycleTime" BO_ 1193 0;
BA_ "Description" SG_ 1193 C_PTGMNValueSet "18.08.09_";
BA_ "GenSigSendType" SG_ 1193 C_PTGMNValueSet 4;
BA_ "UserSigValidity" SG_ 1193 C_PTGMNValueSet 3;
BA_ "Version" SG_ 1193 C_PTGMNValueSet "18.09.04";
BA_ "Description" SG_ 1193 CF_AVN_PSMNValueSet "18.08.09_";
BA_ "GenSigSendType" SG_ 1193 CF_AVN_PSMNValueSet 4;
BA_ "UserSigValidity" SG_ 1193 CF_AVN_PSMNValueSet 3;
BA_REL_ "GenSigTimeoutTime" BU_SG_REL_ DPSU SG_ 1193 CF_AVN_PSMNValueSet 0;
BA_ "Version" SG_ 1193 CF_AVN_PSMNValueSet "18.09.04";
BA_ "Description" SG_ 1193 C_HfreeTrunkTgNValueSet "18.08.09_";
BA_ "GenSigSendType" SG_ 1193 C_HfreeTrunkTgNValueSet 4;
BA_ "UserSigValidity" SG_ 1193 C_HfreeTrunkTgNValueSet 3;
BA_ "Version" SG_ 1193 C_HfreeTrunkTgNValueSet "18.09.04";
BA_ "Description" SG_ 1193 CF_AVN_TrfChgSet "18.08.09_";
BA_ "GenSigSendType" SG_ 1193 CF_AVN_TrfChgSet 4;
BA_ "UserSigValidity" SG_ 1193 CF_AVN_TrfChgSet 3;
BA_ "Version" SG_ 1193 CF_AVN_TrfChgSet "18.09.04";
BA_ "Description" SG_ 1193 CF_AVN_SCMNValueSet "18.08.09_";
BA_ "GenSigSendType" SG_ 1193 CF_AVN_SCMNValueSet 4;
BA_ "UserSigValidity" SG_ 1193 CF_AVN_SCMNValueSet 3;
BA_ "Version" SG_ 1193 CF_AVN_SCMNValueSet "18.09.04";
BA_ "Description" SG_ 1193 CF_AVN_ADrUNValueSet "18.08.09_";
BA_ "GenSigSendType" SG_ 1193 CF_AVN_ADrUNValueSet 4;
BA_ "UserSigValidity" SG_ 1193 CF_AVN_ADrUNValueSet 3;
BA_ "Version" SG_ 1193 CF_AVN_ADrUNValueSet "18.09.04";
BA_ "Description" SG_ 1193 CF_AVN_OTTurnNValueSet "18.08.09_";
BA_ "GenSigSendType" SG_ 1193 CF_AVN_OTTurnNValueSet 4;
BA_ "UserSigValidity" SG_ 1193 CF_AVN_OTTurnNValueSet 3;
BA_ "Version" SG_ 1193 CF_AVN_OTTurnNValueSet "18.09.04";
BA_ "Description" SG_ 1193 CF_Gway_WPCNValueSet "18.08.09_";
BA_ "GenSigSendType" SG_ 1193 CF_Gway_WPCNValueSet 4;
BA_ "UserSigValidity" SG_ 1193 CF_Gway_WPCNValueSet 3;
BA_REL_ "GenSigTimeoutTime" BU_SG_REL_ WPC SG_ 1193 CF_Gway_WPCNValueSet 0;
BA_REL_ "GenSigTimeoutTime" BU_SG_REL_ WPC2 SG_ 1193 CF_Gway_WPCNValueSet 0;
BA_ "Version" SG_ 1193 CF_Gway_WPCNValueSet "18.09.04";
BA_ "Description" SG_ 1193 C_AVN_RearWiperNValueSet "18.08.09_";
BA_ "GenSigSendType" SG_ 1193 C_AVN_RearWiperNValueSet 4;
BA_ "UserSigValidity" SG_ 1193 C_AVN_RearWiperNValueSet 3;
BA_ "Version" SG_ 1193 C_AVN_RearWiperNValueSet "18.09.04";
BA_ "Description" SG_ 1193 C_UnlockWelocomeNValueSet "18.08.09_";
BA_ "GenSigSendType" SG_ 1193 C_UnlockWelocomeNValueSet 4;
BA_ "UserSigValidity" SG_ 1193 C_UnlockWelocomeNValueSet 3;
BA_ "Version" SG_ 1193 C_UnlockWelocomeNValueSet "18.09.04";
BA_ "Description" SG_ 1193 C_SmartWelocomeNValueSet "18.08.09_";
BA_ "GenSigSendType" SG_ 1193 C_SmartWelocomeNValueSet 4;
BA_ "UserSigValidity" SG_ 1193 C_SmartWelocomeNValueSet 3;
BA_ "Version" SG_ 1193 C_SmartWelocomeNValueSet "18.09.04";
BA_ "Description" SG_ 1193 CF_AVN_PTGSpeedNValueSet "18.08.09_";
BA_ "GenSigSendType" SG_ 1193 CF_AVN_PTGSpeedNValueSet 4;
BA_ "UserSigValidity" SG_ 1193 CF_AVN_PTGSpeedNValueSet 3;
BA_ "Version" SG_ 1193 CF_AVN_PTGSpeedNValueSet "18.09.04";
BA_ "Description" SG_ 1193 CR_Datc_DRSeatWheel_USM_Set "18.08.09_";
BA_ "GenSigSendType" SG_ 1193 CR_Datc_DRSeatWheel_USM_Set 4;
BA_ "UserSigValidity" SG_ 1193 CR_Datc_DRSeatWheel_USM_Set 3;
BA_ "Version" SG_ 1193 CR_Datc_DRSeatWheel_USM_Set "18.09.04";
BA_ "Description" SG_ 1193 CF_AVN_TTUnlockNValueSet "18.08.09_";
BA_ "GenSigSendType" SG_ 1193 CF_AVN_TTUnlockNValueSet 4;
BA_ "GenSigStartValue" SG_ 1193 CF_AVN_TTUnlockNValueSet 3;
BA_ "UserSigValidity" SG_ 1193 CF_AVN_TTUnlockNValueSet 3;
BA_ "Version" SG_ 1193 CF_AVN_TTUnlockNValueSet "18.09.04";
BA_ "Description" SG_ 1193 CF_Gway_RWPCNValueSet "18.08.09_";
BA_ "GenSigSendType" SG_ 1193 CF_Gway_RWPCNValueSet 4;
BA_ "UserSigValidity" SG_ 1193 CF_Gway_RWPCNValueSet 3;
BA_REL_ "GenSigTimeoutTime" BU_SG_REL_ RWPC SG_ 1193 CF_Gway_RWPCNValueSet 0;
BA_ "Version" SG_ 1193 CF_Gway_RWPCNValueSet "18.09.04";
BA_ "Description" SG_ 1193 C_PSDNValueSet "18.11.10_";
BA_ "GenSigSendType" SG_ 1193 C_PSDNValueSet 4;
BA_ "UserSigValidity" SG_ 1193 C_PSDNValueSet 3;
BA_ "Version" SG_ 1193 C_PSDNValueSet "18.12.01";
BA_ "Description" SG_ 1193 CF_Avn_HAPTICWARNINGNValueSet "18.11.09_";
BA_ "GenSigSendType" SG_ 1193 CF_Avn_HAPTICWARNINGNValueSet 4;
BA_ "UserSigValidity" SG_ 1193 CF_Avn_HAPTICWARNINGNValueSet 3;
BA_ "Version" SG_ 1193 CF_Avn_HAPTICWARNINGNValueSet "18.12.01";
BA_ "Description" SG_ 1193 CR_Datc_DRSeatHeat_USM_Set "18.08.09_";
BA_ "GenSigSendType" SG_ 1193 CR_Datc_DRSeatHeat_USM_Set 4;
BA_ "UserSigValidity" SG_ 1193 CR_Datc_DRSeatHeat_USM_Set 3;
BA_ "Version" SG_ 1193 CR_Datc_DRSeatHeat_USM_Set "18.09.04";
BA_ "Description" SG_ 1193 C_WALNValueSet "18.08.09_";
BA_ "GenSigSendType" SG_ 1193 C_WALNValueSet 4;
BA_ "UserSigValidity" SG_ 1193 C_WALNValueSet 3;
BA_ "Version" SG_ 1193 C_WALNValueSet "18.09.04";
BA_ "Description" SG_ 1193 C_ApprUnlockNValue "18.08.09_";
BA_ "GenSigSendType" SG_ 1193 C_ApprUnlockNValue 4;
BA_ "UserSigValidity" SG_ 1193 C_ApprUnlockNValue 3;
BA_ "Version" SG_ 1193 C_ApprUnlockNValue "18.09.04";
BA_ "Description" SG_ 1193 CF_AVN_EscortHLNValueSet "18.08.09_";
BA_ "GenSigSendType" SG_ 1193 CF_AVN_EscortHLNValueSet 4;
BA_ "UserSigValidity" SG_ 1193 CF_AVN_EscortHLNValueSet 3;
BA_ "Version" SG_ 1193 CF_AVN_EscortHLNValueSet "18.09.04";
BA_ "GenMsgCycleTime" BO_ 1195 0;
BA_ "Description" SG_ 1195 CF_AVN_CluWelcomeSnd "16.06.04_";
BA_ "GenSigSendType" SG_ 1195 CF_AVN_CluWelcomeSnd 4;
BA_ "UserSigValidity" SG_ 1195 CF_AVN_CluWelcomeSnd 3;
BA_ "Version" SG_ 1195 CF_AVN_CluWelcomeSnd "18.04.02";
BA_ "Description" SG_ 1195 CF_AVN_CluTransmissionDisp "16.06.04_";
BA_ "GenSigSendType" SG_ 1195 CF_AVN_CluTransmissionDisp 4;
BA_ "UserSigValidity" SG_ 1195 CF_AVN_CluTransmissionDisp 3;
BA_ "Version" SG_ 1195 CF_AVN_CluTransmissionDisp "18.04.02";
BA_ "Description" SG_ 1195 CF_AVN_CluWiperLight "16.06.04_";
BA_ "GenSigSendType" SG_ 1195 CF_AVN_CluWiperLight 4;
BA_ "UserSigValidity" SG_ 1195 CF_AVN_CluWiperLight 3;
BA_ "Version" SG_ 1195 CF_AVN_CluWiperLight "18.04.02";
BA_ "Description" SG_ 1195 CF_AVN_CluRoadInfoGuide "16.06.04_";
BA_ "GenSigSendType" SG_ 1195 CF_AVN_CluRoadInfoGuide 4;
BA_ "UserSigValidity" SG_ 1195 CF_AVN_CluRoadInfoGuide 3;
BA_ "Version" SG_ 1195 CF_AVN_CluRoadInfoGuide "18.04.02";
BA_ "Description" SG_ 1195 CF_AVN_CluUserSettingPeriod "16.06.04_";
BA_ "GenSigSendType" SG_ 1195 CF_AVN_CluUserSettingPeriod 4;
BA_ "GenSigStartValue" SG_ 1195 CF_AVN_CluUserSettingPeriod 127;
BA_ "UserSigValidity" SG_ 1195 CF_AVN_CluUserSettingPeriod 3;
BA_ "Version" SG_ 1195 CF_AVN_CluUserSettingPeriod "19.01.10";
BA_ "Description" SG_ 1195 CF_AVN_CluAutoInitFuelEconomy "16.06.04_";
BA_ "GenSigSendType" SG_ 1195 CF_AVN_CluAutoInitFuelEconomy 4;
BA_ "UserSigValidity" SG_ 1195 CF_AVN_CluAutoInitFuelEconomy 3;
BA_ "Version" SG_ 1195 CF_AVN_CluAutoInitFuelEconomy "18.04.02";
BA_ "Description" SG_ 1195 CF_AVN_CluFuelEconUnit_mi "18.08.08_";
BA_ "GenSigSendType" SG_ 1195 CF_AVN_CluFuelEconUnit_mi 4;
BA_ "UserSigValidity" SG_ 1195 CF_AVN_CluFuelEconUnit_mi 3;
BA_ "Version" SG_ 1195 CF_AVN_CluFuelEconUnit_mi "18.09.04";
BA_ "GenSigSendType" SG_ 1195 CF_AVN_CluFuelEconUnit_km 4;
BA_ "UserSigValidity" SG_ 1195 CF_AVN_CluFuelEconUnit_km 3;
BA_ "Version" SG_ 1195 CF_AVN_CluFuelEconUnit_km "20.08.02";
BA_ "Description" SG_ 1195 CF_AVN_CluUserSettingDistance "16.06.04_";
BA_ "GenSigSendType" SG_ 1195 CF_AVN_CluUserSettingDistance 4;
BA_ "GenSigStartValue" SG_ 1195 CF_AVN_CluUserSettingDistance 131071;
BA_ "UserSigValidity" SG_ 1195 CF_AVN_CluUserSettingDistance 3;
BA_ "Version" SG_ 1195 CF_AVN_CluUserSettingDistance "19.01.10";
BA_ "Description" SG_ 1195 CF_AVN_CluRheostatLvl "18.06.00_";
BA_ "GenSigSendType" SG_ 1195 CF_AVN_CluRheostatLvl 4;
BA_ "GenSigStartValue" SG_ 1195 CF_AVN_CluRheostatLvl 31;
BA_ "UserSigValidity" SG_ 1195 CF_AVN_CluRheostatLvl 3;
BA_ "Version" SG_ 1195 CF_AVN_CluRheostatLvl "18.06.04";
BA_ "Description" SG_ 1195 CF_AVN_CluVoiceVolume "16.06.04_";
BA_ "GenSigSendType" SG_ 1195 CF_AVN_CluVoiceVolume 4;
BA_ "UserSigValidity" SG_ 1195 CF_AVN_CluVoiceVolume 3;
BA_ "Version" SG_ 1195 CF_AVN_CluVoiceVolume "18.04.02";
BA_ "Description" SG_ 1195 CF_AVN_EVReset "18.08.08_Request to reset EV Service (0x1 : EV USM Reset)";
BA_ "GenSigSendType" SG_ 1195 CF_AVN_EVReset 4;
BA_ "UserSigValidity" SG_ 1195 CF_AVN_EVReset 7;
BA_ "Version" SG_ 1195 CF_AVN_EVReset "18.09.04";
BA_ "Description" SG_ 1195 CF_AVN_UnitReset "18.08.08_";
BA_ "GenSigSendType" SG_ 1195 CF_AVN_UnitReset 4;
BA_ "UserSigValidity" SG_ 1195 CF_AVN_UnitReset 3;
BA_ "Version" SG_ 1195 CF_AVN_UnitReset "18.09.04";
BA_ "Description" SG_ 1195 CF_AVN_IcyRoadWarn "17.02.05_";
BA_ "GenSigSendType" SG_ 1195 CF_AVN_IcyRoadWarn 4;
BA_ "UserSigValidity" SG_ 1195 CF_AVN_IcyRoadWarn 3;
BA_ "Version" SG_ 1195 CF_AVN_IcyRoadWarn "18.04.02";
BA_ "Description" SG_ 1195 CF_AVN_CluServiceReminderReset "16.11.03_";
BA_ "GenSigSendType" SG_ 1195 CF_AVN_CluServiceReminderReset 4;
BA_ "UserSigValidity" SG_ 1195 CF_AVN_CluServiceReminderReset 3;
BA_ "Version" SG_ 1195 CF_AVN_CluServiceReminderReset "18.04.02";
BA_ "GenSigSendType" SG_ 1195 CF_AVN_CluUSMReset 4;
BA_ "UserSigValidity" SG_ 1195 CF_AVN_CluUSMReset 3;
BA_REL_ "GenSigTimeoutTime" BU_SG_REL_ WPC SG_ 1195 CF_AVN_CluUSMReset 0;
BA_REL_ "GenSigTimeoutTime" BU_SG_REL_ RWPC SG_ 1195 CF_AVN_CluUSMReset 0;
BA_REL_ "GenSigTimeoutTime" BU_SG_REL_ PSB SG_ 1195 CF_AVN_CluUSMReset 0;
BA_REL_ "GenSigTimeoutTime" BU_SG_REL_ SLB SG_ 1195 CF_AVN_CluUSMReset 0;
BA_REL_ "GenSigTimeoutTime" BU_SG_REL_ ARS SG_ 1195 CF_AVN_CluUSMReset 0;
BA_REL_ "GenSigTimeoutTime" BU_SG_REL_ APSU SG_ 1195 CF_AVN_CluUSMReset 0;
BA_REL_ "GenSigTimeoutTime" BU_SG_REL_ RLHV SG_ 1195 CF_AVN_CluUSMReset 0;
BA_REL_ "GenSigTimeoutTime" BU_SG_REL_ RRHV SG_ 1195 CF_AVN_CluUSMReset 0;
BA_REL_ "GenSigTimeoutTime" BU_SG_REL_ SHVU_FR SG_ 1195 CF_AVN_CluUSMReset 0;
BA_REL_ "GenSigTimeoutTime" BU_SG_REL_ SHVU_RR SG_ 1195 CF_AVN_CluUSMReset 0;
BA_REL_ "GenSigTimeoutTime" BU_SG_REL_ DPSU SG_ 1195 CF_AVN_CluUSMReset 0;
BA_REL_ "GenSigTimeoutTime" BU_SG_REL_ DLBCU SG_ 1195 CF_AVN_CluUSMReset 0;
BA_REL_ "GenSigTimeoutTime" BU_SG_REL_ PFSU SG_ 1195 CF_AVN_CluUSMReset 0;
BA_REL_ "GenSigTimeoutTime" BU_SG_REL_ RRPSU SG_ 1195 CF_AVN_CluUSMReset 0;
BA_REL_ "GenSigTimeoutTime" BU_SG_REL_ RLPSU SG_ 1195 CF_AVN_CluUSMReset 0;
BA_REL_ "GenSigTimeoutTime" BU_SG_REL_ ATS SG_ 1195 CF_AVN_CluUSMReset 0;
BA_REL_ "GenSigTimeoutTime" BU_SG_REL_ DSAU SG_ 1195 CF_AVN_CluUSMReset 0;
BA_REL_ "GenSigTimeoutTime" BU_SG_REL_ ASAU SG_ 1195 CF_AVN_CluUSMReset 0;
BA_REL_ "GenSigTimeoutTime" BU_SG_REL_ RCM SG_ 1195 CF_AVN_CluUSMReset 0;
BA_REL_ "GenSigTimeoutTime" BU_SG_REL_ BLTN_CAM SG_ 1195 CF_AVN_CluUSMReset 0;
BA_REL_ "GenSigTimeoutTime" BU_SG_REL_ ALBCU SG_ 1195 CF_AVN_CluUSMReset 0;
BA_REL_ "GenSigTimeoutTime" BU_SG_REL_ WPC2 SG_ 1195 CF_AVN_CluUSMReset 0;
BA_ "Version" SG_ 1195 CF_AVN_CluUSMReset "21.01.08";
BA_ "Description" SG_ 1195 CF_AVN_CluServiceReminderSet "16.06.04_";
BA_ "GenSigSendType" SG_ 1195 CF_AVN_CluServiceReminderSet 4;
BA_ "UserSigValidity" SG_ 1195 CF_AVN_CluServiceReminderSet 3;
BA_ "Version" SG_ 1195 CF_AVN_CluServiceReminderSet "18.04.02";
BA_ "GenMsgCycleTime" BO_ 1196 0;
BA_ "Description" SG_ 1196 C_HCIMSWeightNValueSet "18.08.09_";
BA_ "GenSigSendType" SG_ 1196 C_HCIMSWeightNValueSet 4;
BA_ "UserSigValidity" SG_ 1196 C_HCIMSWeightNValueSet 3;
BA_REL_ "GenSigTimeoutTime" BU_SG_REL_ DPSU SG_ 1196 C_HCIMSWeightNValueSet 0;
BA_ "Version" SG_ 1196 C_HCIMSWeightNValueSet "18.09.04";
BA_ "Description" SG_ 1196 C_HCIMSSitHeightNValueSet "18.08.09_";
BA_ "GenSigSendType" SG_ 1196 C_HCIMSSitHeightNValueSet 4;
BA_ "UserSigValidity" SG_ 1196 C_HCIMSSitHeightNValueSet 3;
BA_REL_ "GenSigTimeoutTime" BU_SG_REL_ DPSU SG_ 1196 C_HCIMSSitHeightNValueSet 0;
BA_ "Version" SG_ 1196 C_HCIMSSitHeightNValueSet "18.09.04";
BA_ "Description" SG_ 1196 CF_AVN_BodySpprtSet "18.11.00_This signal is for the seat body support USM";
BA_ "GenSigSendType" SG_ 1196 CF_AVN_BodySpprtSet 4;
BA_ "GenSigStartValue" SG_ 1196 CF_AVN_BodySpprtSet 3;
BA_ "UserSigValidity" SG_ 1196 CF_AVN_BodySpprtSet 3;
BA_REL_ "GenSigTimeoutTime" BU_SG_REL_ DLBCU SG_ 1196 CF_AVN_BodySpprtSet 0;
BA_REL_ "GenSigTimeoutTime" BU_SG_REL_ DSAU SG_ 1196 CF_AVN_BodySpprtSet 0;
BA_ "Version" SG_ 1196 CF_AVN_BodySpprtSet "18.11.01";
BA_ "Description" SG_ 1196 CF_AVN_AirSptTimeNValueSet "18.08.09_This signal is for the seat massage function time setting";
BA_ "GenSigSendType" SG_ 1196 CF_AVN_AirSptTimeNValueSet 4;
BA_ "GenSigStartValue" SG_ 1196 CF_AVN_AirSptTimeNValueSet 7;
BA_ "UserSigValidity" SG_ 1196 CF_AVN_AirSptTimeNValueSet 3;
BA_REL_ "GenSigTimeoutTime" BU_SG_REL_ DLBCU SG_ 1196 CF_AVN_AirSptTimeNValueSet 0;
BA_ "Version" SG_ 1196 CF_AVN_AirSptTimeNValueSet "18.09.04";
BA_ "Description" SG_ 1196 CF_AVN_AirSptStrNValue "18.08.09_This signal is for the seat massage intensity USM";
BA_ "GenSigSendType" SG_ 1196 CF_AVN_AirSptStrNValue 4;
BA_ "GenSigStartValue" SG_ 1196 CF_AVN_AirSptStrNValue 3;
BA_ "UserSigValidity" SG_ 1196 CF_AVN_AirSptStrNValue 3;
BA_REL_ "GenSigTimeoutTime" BU_SG_REL_ DLBCU SG_ 1196 CF_AVN_AirSptStrNValue 0;
BA_ "Version" SG_ 1196 CF_AVN_AirSptStrNValue "18.09.04";
BA_ "Description" SG_ 1196 CF_AVN_SeatDrvModNValueSet "18.08.09_This signal is for the auto seat-drivemode user setting menu";
BA_ "GenSigSendType" SG_ 1196 CF_AVN_SeatDrvModNValueSet 4;
BA_ "GenSigStartValue" SG_ 1196 CF_AVN_SeatDrvModNValueSet 3;
BA_ "UserSigValidity" SG_ 1196 CF_AVN_SeatDrvModNValueSet 3;
BA_REL_ "GenSigTimeoutTime" BU_SG_REL_ DLBCU SG_ 1196 CF_AVN_SeatDrvModNValueSet 0;
BA_REL_ "GenSigTimeoutTime" BU_SG_REL_ DSAU SG_ 1196 CF_AVN_SeatDrvModNValueSet 0;
BA_ "Version" SG_ 1196 CF_AVN_SeatDrvModNValueSet "18.09.04";
BA_ "Description" SG_ 1196 C_HCIMSHeightNvalueSet "18.08.09_";
BA_ "GenSigSendType" SG_ 1196 C_HCIMSHeightNvalueSet 4;
BA_ "UserSigValidity" SG_ 1196 C_HCIMSHeightNvalueSet 3;
BA_REL_ "GenSigTimeoutTime" BU_SG_REL_ DPSU SG_ 1196 C_HCIMSHeightNvalueSet 0;
BA_ "Version" SG_ 1196 C_HCIMSHeightNvalueSet "18.09.04";
BA_ "Description" SG_ 1196 C_SLB_SmartCtrl_NValue "USM Reqest for Smart Posture Care 2.0 On/Off";
BA_ "GenSigSendType" SG_ 1196 C_SLB_SmartCtrl_NValue 4;
BA_ "UserSigValidity" SG_ 1196 C_SLB_SmartCtrl_NValue 3;
BA_ "Version" SG_ 1196 C_SLB_SmartCtrl_NValue "19.04.01";
BA_ "Description" SG_ 1196 CF_AVN_CushSoftNValueSet "18.10.03_This signal is for the cushsoftness setting";
BA_ "GenSigSendType" SG_ 1196 CF_AVN_CushSoftNValueSet 4;
BA_ "GenSigStartValue" SG_ 1196 CF_AVN_CushSoftNValueSet 7;
BA_ "UserSigValidity" SG_ 1196 CF_AVN_CushSoftNValueSet 3;
BA_REL_ "GenSigTimeoutTime" BU_SG_REL_ DLBCU SG_ 1196 CF_AVN_CushSoftNValueSet 0;
BA_ "Version" SG_ 1196 CF_AVN_CushSoftNValueSet "18.10.05";
BA_ "Description" SG_ 1196 C_SmrtSldngDrNValueSet "USM request for Smart Sliding Door";
BA_ "GenSigSendType" SG_ 1196 C_SmrtSldngDrNValueSet 4;
BA_ "UserSigValidity" SG_ 1196 C_SmrtSldngDrNValueSet 3;
BA_ "Version" SG_ 1196 C_SmrtSldngDrNValueSet "19.01.10";
BA_ "Description" SG_ 1196 CF_AVN_TurboPressureUnit "USM Request for Turbo Boost Pressure Unit";
BA_ "GenSigSendType" SG_ 1196 CF_AVN_TurboPressureUnit 4;
BA_ "UserSigValidity" SG_ 1196 CF_AVN_TurboPressureUnit 3;
BA_ "Version" SG_ 1196 CF_AVN_TurboPressureUnit "19.06.02";
BA_ "Description" SG_ 1196 CF_AVN_CluTorqueUnit "USM Request for Torque Unit Setting";
BA_ "GenSigSendType" SG_ 1196 CF_AVN_CluTorqueUnit 4;
BA_ "UserSigValidity" SG_ 1196 CF_AVN_CluTorqueUnit 3;
BA_ "Version" SG_ 1196 CF_AVN_CluTorqueUnit "19.06.02";
BA_ "Description" SG_ 1196 AVN_Usm_CluFuelEconomySet "USM request for Fuel economy auto reset";
BA_ "GenSigSendType" SG_ 1196 AVN_Usm_CluFuelEconomySet 4;
BA_ "UserSigValidity" SG_ 1196 AVN_Usm_CluFuelEconomySet 3;
BA_ "Version" SG_ 1196 AVN_Usm_CluFuelEconomySet "19.06.00";
BA_ "Description" SG_ 1196 CF_AVN_HCIMSButtonCommand "18.08.09_";
BA_ "GenSigSendType" SG_ 1196 CF_AVN_HCIMSButtonCommand 4;
BA_ "UserSigValidity" SG_ 1196 CF_AVN_HCIMSButtonCommand 3;
BA_REL_ "GenSigTimeoutTime" BU_SG_REL_ DPSU SG_ 1196 CF_AVN_HCIMSButtonCommand 0;
BA_ "Version" SG_ 1196 CF_AVN_HCIMSButtonCommand "18.09.04";
BA_ "GenMsgCycleTime" BO_ 1915 0;
BA_ "GenMsgCycleTimeFast" BO_ 1915 0;
BA_ "GenMsgNrOfRepetition" BO_ 1915 0;
BA_ "DiagResponse" BO_ 1915 1;
BA_ "GenMsgILSupport" BO_ 1915 0;
BA_ "TpMessage" BO_ 1915 1;
BA_ "TpTxIndex" BO_ 1915 158;
BA_ "Description" SG_ 1915 RARS_GST_Byte0 "TP Index : 158";
BA_ "UsrSigPurpose" SG_ 1915 RARS_GST_Byte0 4;
BA_ "UserSigValidity" SG_ 1915 RARS_GST_Byte0 0;
BA_REL_ "GenSigTimeoutTime" BU_SG_REL_ CGW_CCU SG_ 1915 RARS_GST_Byte0 0;
BA_ "NetworkRequest" SG_ 1915 RARS_GST_Byte0 0;
BA_ "NetworkRequestHoldingTime" SG_ 1915 RARS_GST_Byte0 5000;
BA_ "Version" SG_ 1915 RARS_GST_Byte0 "21.02.04";
BA_ "Description" SG_ 1915 RARS_GST_Byte2 "TP Index : 158";
BA_ "UsrSigPurpose" SG_ 1915 RARS_GST_Byte2 4;
BA_ "UserSigValidity" SG_ 1915 RARS_GST_Byte2 0;
BA_REL_ "GenSigTimeoutTime" BU_SG_REL_ CGW_CCU SG_ 1915 RARS_GST_Byte2 0;
BA_ "NetworkRequest" SG_ 1915 RARS_GST_Byte2 0;
BA_ "NetworkRequestHoldingTime" SG_ 1915 RARS_GST_Byte2 5000;
BA_ "Version" SG_ 1915 RARS_GST_Byte2 "21.02.04";
BA_ "Description" SG_ 1915 RARS_GST_Byte3 "TP Index : 158";
BA_ "UsrSigPurpose" SG_ 1915 RARS_GST_Byte3 4;
BA_ "UserSigValidity" SG_ 1915 RARS_GST_Byte3 0;
BA_REL_ "GenSigTimeoutTime" BU_SG_REL_ CGW_CCU SG_ 1915 RARS_GST_Byte3 0;
BA_ "NetworkRequest" SG_ 1915 RARS_GST_Byte3 0;
BA_ "NetworkRequestHoldingTime" SG_ 1915 RARS_GST_Byte3 5000;
BA_ "Version" SG_ 1915 RARS_GST_Byte3 "21.02.04";
BA_ "Description" SG_ 1915 RARS_GST_Byte4 "TP Index : 158";
BA_ "UsrSigPurpose" SG_ 1915 RARS_GST_Byte4 4;
BA_ "UserSigValidity" SG_ 1915 RARS_GST_Byte4 0;
BA_REL_ "GenSigTimeoutTime" BU_SG_REL_ CGW_CCU SG_ 1915 RARS_GST_Byte4 0;
BA_ "NetworkRequest" SG_ 1915 RARS_GST_Byte4 0;
BA_ "NetworkRequestHoldingTime" SG_ 1915 RARS_GST_Byte4 5000;
BA_ "Version" SG_ 1915 RARS_GST_Byte4 "21.02.04";
BA_ "Description" SG_ 1915 RARS_GST_Byte5 "TP Index : 158";
BA_ "UsrSigPurpose" SG_ 1915 RARS_GST_Byte5 4;
BA_ "UserSigValidity" SG_ 1915 RARS_GST_Byte5 0;
BA_REL_ "GenSigTimeoutTime" BU_SG_REL_ CGW_CCU SG_ 1915 RARS_GST_Byte5 0;
BA_ "NetworkRequest" SG_ 1915 RARS_GST_Byte5 0;
BA_ "NetworkRequestHoldingTime" SG_ 1915 RARS_GST_Byte5 5000;
BA_ "Version" SG_ 1915 RARS_GST_Byte5 "21.02.04";
BA_ "Description" SG_ 1915 RARS_GST_Byte6 "TP Index : 158";
BA_ "UsrSigPurpose" SG_ 1915 RARS_GST_Byte6 4;
BA_ "UserSigValidity" SG_ 1915 RARS_GST_Byte6 0;
BA_REL_ "GenSigTimeoutTime" BU_SG_REL_ CGW_CCU SG_ 1915 RARS_GST_Byte6 0;
BA_ "NetworkRequest" SG_ 1915 RARS_GST_Byte6 0;
BA_ "NetworkRequestHoldingTime" SG_ 1915 RARS_GST_Byte6 5000;
BA_ "Version" SG_ 1915 RARS_GST_Byte6 "21.02.04";
BA_ "Description" SG_ 1915 RARS_GST_Byte7 "TP Index : 158";
BA_ "UsrSigPurpose" SG_ 1915 RARS_GST_Byte7 4;
BA_ "UserSigValidity" SG_ 1915 RARS_GST_Byte7 0;
BA_REL_ "GenSigTimeoutTime" BU_SG_REL_ CGW_CCU SG_ 1915 RARS_GST_Byte7 0;
BA_ "NetworkRequest" SG_ 1915 RARS_GST_Byte7 0;
BA_ "NetworkRequestHoldingTime" SG_ 1915 RARS_GST_Byte7 5000;
BA_ "Version" SG_ 1915 RARS_GST_Byte7 "21.02.04";
BA_ "Description" SG_ 1915 RARS_GST_Byte1 "TP Index : 158";
BA_ "UsrSigPurpose" SG_ 1915 RARS_GST_Byte1 4;
BA_ "UserSigValidity" SG_ 1915 RARS_GST_Byte1 0;
BA_REL_ "GenSigTimeoutTime" BU_SG_REL_ CGW_CCU SG_ 1915 RARS_GST_Byte1 0;
BA_ "NetworkRequest" SG_ 1915 RARS_GST_Byte1 0;
BA_ "NetworkRequestHoldingTime" SG_ 1915 RARS_GST_Byte1 5000;
BA_ "Version" SG_ 1915 RARS_GST_Byte1 "21.02.04";
BA_ "GenMsgSendType" BO_ 830 0;
BA_ "Description" SG_ 830 USM_CmdWPC2Sta "USM request value of WPC2";
BA_ "GenSigSendType" SG_ 830 USM_CmdWPC2Sta 4;
BA_ "UserSigValidity" SG_ 830 USM_CmdWPC2Sta 0;
BA_REL_ "GenSigTimeoutTime" BU_SG_REL_ CGW_CCU SG_ 830 USM_CmdWPC2Sta 1500;
BA_ "NetworkRequest" SG_ 830 USM_CmdWPC2Sta 0;
BA_ "NetworkRequestHoldingTime" SG_ 830 USM_CmdWPC2Sta 5000;
BA_ "Version" SG_ 830 USM_CmdWPC2Sta "22.02.06";
BA_ "Description" SG_ 830 WPC2_SWVerMajor1 "Indicate the WPC2 software version as follows:

- The software version is displayed in three digits.

- The Major and Minor digits are separated by '.'

- Signal values are transmitted to ASCII codes.



¡Ø Example

WPC2_SWVerMajor1 : 0x41 (HEX) -> ASCII CODE : 'A' 

WPC2_SWVerMinor1 : 0x30 (HEX) -> ASCII CODE : '0'

WPC2_SWVerMinor2 : 0x33 (HEX) -> ASCII CODE : '3'

=> WPC2 S/W Ver is displayed 'A.03'";
BA_ "GenSigSendType" SG_ 830 WPC2_SWVerMajor1 4;
BA_ "UserSigValidity" SG_ 830 WPC2_SWVerMajor1 0;
BA_REL_ "GenSigTimeoutTime" BU_SG_REL_ CGW_CCU SG_ 830 WPC2_SWVerMajor1 1500;
BA_ "Version" SG_ 830 WPC2_SWVerMajor1 "22.02.06";
BA_ "Description" SG_ 830 WPC2_PhnLftWrngSta "Warning by WPC2 for User (Phone left in vehicle)";
BA_ "GenSigSendType" SG_ 830 WPC2_PhnLftWrngSta 4;
BA_ "UserSigValidity" SG_ 830 WPC2_PhnLftWrngSta 0;
BA_REL_ "GenSigTimeoutTime" BU_SG_REL_ CGW_CCU SG_ 830 WPC2_PhnLftWrngSta 1500;
BA_ "NetworkRequest" SG_ 830 WPC2_PhnLftWrngSta 0;
BA_ "NetworkRequestHoldingTime" SG_ 830 WPC2_PhnLftWrngSta 5000;
BA_ "Version" SG_ 830 WPC2_PhnLftWrngSta "22.02.06";
BA_ "Description" SG_ 830 WPC2_SWVerMinor1 "Indicate the WPC2 software version as follows:

- The software version is displayed in three digits.

- The Major and Minor digits are separated by '.'

- Signal values are transmitted to ASCII codes.



¡Ø Example

WPC2_SWVerMajor1 : 0x41 (HEX) -> ASCII CODE : 'A' 

WPC2_SWVerMinor1 : 0x30 (HEX) -> ASCII CODE : '0'

WPC2_SWVerMinor2 : 0x33 (HEX) -> ASCII CODE : '3'

=> WPC2 S/W Ver is displayed 'A.03'";
BA_ "GenSigSendType" SG_ 830 WPC2_SWVerMinor1 4;
BA_ "UserSigValidity" SG_ 830 WPC2_SWVerMinor1 0;
BA_REL_ "GenSigTimeoutTime" BU_SG_REL_ CGW_CCU SG_ 830 WPC2_SWVerMinor1 1500;
BA_ "Version" SG_ 830 WPC2_SWVerMinor1 "22.02.06";
BA_ "Description" SG_ 830 WPC2_SWVerMinor2 "Indicate the WPC2 software version as follows:

- The software version is displayed in three digits.

- The Major and Minor digits are separated by '.'

- Signal values are transmitted to ASCII codes.



¡Ø Example

WPC2_SWVerMajor1 : 0x41 (HEX) -> ASCII CODE : 'A' 

WPC2_SWVerMinor1 : 0x30 (HEX) -> ASCII CODE : '0'

WPC2_SWVerMinor2 : 0x33 (HEX) -> ASCII CODE : '3'

=> WPC2 S/W Ver is displayed 'A.03'";
BA_ "GenSigSendType" SG_ 830 WPC2_SWVerMinor2 4;
BA_ "UserSigValidity" SG_ 830 WPC2_SWVerMinor2 0;
BA_REL_ "GenSigTimeoutTime" BU_SG_REL_ CGW_CCU SG_ 830 WPC2_SWVerMinor2 1500;
BA_ "Version" SG_ 830 WPC2_SWVerMinor2 "22.02.06";
BA_ "Description" SG_ 830 WPC2_NFCDeviceDetSta "Warning by WPC2 for User (Phone left in vehicle)";
BA_ "GenSigSendType" SG_ 830 WPC2_NFCDeviceDetSta 4;
BA_ "UserSigValidity" SG_ 830 WPC2_NFCDeviceDetSta 0;
BA_ "NetworkRequest" SG_ 830 WPC2_NFCDeviceDetSta 0;
BA_ "NetworkRequestHoldingTime" SG_ 830 WPC2_NFCDeviceDetSta 5000;
BA_ "Version" SG_ 830 WPC2_NFCDeviceDetSta "22.02.06";
VAL_ 287 APSS_LumbarUpSw 0 "Default" 1 "Off" 2 "On" 3 "Invalid" ;
VAL_ 287 APSS_LumbarMidSw 0 "Default" 1 "Off" 2 "On" 3 "Invalid" ;
VAL_ 287 APSS_LumbarLowSw 0 "Default" 1 "Off" 2 "On" 3 "Invalid" ;
VAL_ 287 APSS_LumbarDefSw 0 "Default" 1 "Off" 2 "On" 3 "Invalid" ;
VAL_ 287 APSS_BolsterInfSw 0 "Default" 1 "Off" 2 "On" 3 "Invalid" ;
VAL_ 287 APSS_BolsterDefSw 0 "Default" 1 "Off" 2 "On" 3 "Invalid" ;
VAL_ 287 APSS_ActiveSw 0 "Off" 1 "On" 2 "Not Used" 3 "Error" ;
VAL_ 287 APSS_CushInfSw 0 "Off" 1 "On" 2 "Not Used" 3 "Error" ;
VAL_ 287 APSS_CushDefSw 0 "Off" 1 "On" 2 "Not Used" 3 "Error" ;
VAL_ 287 APSS_CushOnOffTch 0 "Default" 1 "Off" 2 "On(Off State)" 3 "On(Mode1 State)" 4 "On(Mode2 State)" 5 "On(Mode3 State)" 6 "Reserved" 7 "Invalid" ;
VAL_ 273 ARS_RrCurtainBtn 0 "Default" 1 "Open ON" 2 "Close ON" 3 "Invalid" ;
VAL_ 255 BckGls_RrGlsHtdOnCmd 0 "Off" 1 "On" 2 "Not Used" 3 "Error Indicator" ;
VAL_ 255 Wndshld_FrtGlsHtdOnCmd 0 "Off" 1 "On" 2 "Not Used" 3 "Error Indicator" ;
VAL_ 255 Mirror_MirFldOpt 0 "Not Applied" 1 "Applied" 2 "Not Used" 3 "Error Indicator" ;
VAL_ 255 Window_AsstPwrWdwSunroofEnblSta 0 "Disable" 1 "Enable" 2 "Not Used" 3 "Error Indicator" ;
VAL_ 255 Window_RrPwrWdwEnblSta 0 "Off" 1 "On" 2 "Not Used" 3 "Error Indicator" ;
VAL_ 255 Window_RrPwrWdwLkInd 0 "Off" 1 "On" 2 "Not Used" 3 "Error Indicator" ;
VAL_ 255 Window_DrvPwrWdwCmd 0 "NoAction" 1 "ManualUp" 2 "ManualDown" 3 "Error Indicator" ;
VAL_ 255 Window_AsstPwrWdwCmd 0 "NoAction" 1 "ManualUp" 2 "ManualDown" 3 "Error Indicator" ;
VAL_ 255 Window_RrLftPwrWdwCmd 0 "NoAction" 1 "ManualUp" 2 "ManualDown" 3 "Error Indicator" ;
VAL_ 255 Window_RrRtPwrWdwCmd 0 "NoAction" 1 "ManualUp" 2 "ManualDown" 3 "Error Indicator" ;
VAL_ 255 Mirror_FldUnfldCmd 0 "Off" 1 "Fold" 2 "Unfold" 3 "Error Indicator" ;
VAL_ 255 Mirror_FldCtrlSta 0 "Off" 1 "Fldng" 2 "Fld" 3 "Error Indicator" ;
VAL_ 255 Mirror_UnFldCtrlSta 0 "Off" 1 "UnFldng" 2 "UnFld" 3 "Error Indicator" ;
VAL_ 255 Mirror_PosMnlCmd 0 "Off" 1 "Up" 2 "Down" 3 "Left" 4 "Right" 5 "Not Used" 6 "Not Used" 7 "Error Indicator" ;
VAL_ 255 Mirror_SelSwIndCmd 0 "Off" 1 "Left" 2 "Neutral" 3 "Right" 4 "Not Used" 5 "Not Used" 6 "Not Used" 7 "Error Indicator" ;
VAL_ 255 BCM_SafetyWdwOptTyp2 0 "None" 1 "Driver Safety Window" 2 "Front Safety Window" 3 "All Safety Window" 4 "Not Used" 5 "Not Used" 6 "Not Used" 7 "Error Indicator" ;
VAL_ 255 Mirror_LHOSMirPlyBckSta 0 "Stop" 1 "Play 1" 2 "Play 2" 3 "Play 3" 4 "Smart IMS" 5 "Profile 1" 6 "Profile 2" 7 "Guest" 8 "Not Used" 9 "Not Used" 10 "Not Used" 11 "Not Used" 12 "Not Used" 13 "Not Used" 14 "Not Used" 15 "Error Indicator" ;
VAL_ 255 Mirror_RHOSMirPlyBckSta 0 "Stop" 1 "Play 1" 2 "Play 2" 3 "Play 3" 4 "Smart IMS" 5 "Profile 1" 6 "Profile 2" 7 "Guest" 8 "Not Used" 9 "Not Used" 10 "Not Used" 11 "Not Used" 12 "Not Used" 13 "Not Used" 14 "Not Used" 15 "Error Indicator" ;
VAL_ 255 Mirror_SelSwSta 0 "Off" 1 "Left" 2 "Neutral" 3 "Right" 4 "Not Used" 5 "Not Used" 6 "Not Used" 7 "Error Indicator" ;
VAL_ 255 BckGls_RrGlsHtdOpt 0 "Not Applied" 1 "Applied" 2 "Not Used" 3 "Error Indicator" ;
VAL_ 2344811009 BMS_Crc2Val 65535 "Signal Invalid (Message with unused CRC. CRC signal is transmitted fixed value)" ;
VAL_ 2344811009 BMS_AlvCnt2Val 255 "Signal Invalid (Message with unused Alive counter. Alive counter signal is transmitted fixed value)" ;
VAL_ 2344811009 xEV_SrvLmpReq 0 "Off" 1 "Service Lamp On" 2 "Not used" 3 "Error indicator" ;
VAL_ 2344811009 xEV_MainRlyOnSta 0 "Open" 1 "Close" 2 "Not used" 3 "Error indicator" ;
VAL_ 2344811009 xEV_SysFltSta 0 "Normal" 1 "Fault" 2 "Not used" 3 "Error indicator" ;
VAL_ 2344811009 xEV_InltTempVal 127 "Error value" ;
VAL_ 2344811009 xEV_MinBattCelVoltVal 255 "Error indicator" ;
VAL_ 2344811009 xEV_MaxBattCelVoltVal 255 "Error indicator" ;
VAL_ 2344811010 xEV_BattCurrVal 32767 "Error indicator" ;
VAL_ 2344811010 xEV_MinBattTempVal 127 "Error indicator" ;
VAL_ 2344811010 xEV_MaxBattTempVal 127 "Error indicator" ;
VAL_ 2344811010 xEV_FanSpdStpSta 0 "None" 1 "1step" 2 "2step" 3 "3step" 4 "4step" 5 "5step" 6 "6step" 7 "7step" 8 "8step" 9 "9step" ;
VAL_ 2344811010 xEV_12VRlyOffAlrmReq 0 "Normal" 1 "Pop up Request" 2 "Not used" 3 "Error indicator" ;
VAL_ 2344811010 xEV_12VRlyOnAlrmReq 0 "Normal" 1 "Pop up Request" 2 "Not used" 3 "Error indicator" ;
VAL_ 2344811010 xEV_SocDis 255 "Error value" ;
VAL_ 2344811011 xEV_12VAlarmReqForICU 0 "Normal" 1 "3rd cut off" 2 "Warn. msg & 3rd cut off req" 3 "reserved" ;
VAL_ 2344811011 xEV_AuxBattChrgReq 0 "Normal" 1 "Charge Request" 2 "Not used" 3 "Error Indicator" ;
VAL_ 2344811011 xEV_12VDarkCurrAlarmForICU 0 "Normal" 1 "Alarm Flag set" 2 "Not used" 3 "Error indicator" ;
VAL_ 2344811011 xEV_12VBatVLmt 255 "Error indicator" ;
VAL_ 2344811011 xEV_CharBatInfoReqForSDC 0 "Default(no request)" 1 "High volt bat. First" 2 "12 volt bat. First" 3 "Both of them possible" ;
VAL_ 2344811011 xEV_ClimateOffReq 0 "Default" 1 "Flag set" 2 "Not used" 3 "Error indicator" ;
VAL_ 2344811011 xEV_MainRlyOnRetrySta 0 "Normal" 1 "Relay ON Retry Operation" 2 "Not used" 3 "Error indicator" ;
VAL_ 2344811011 xEV_Bms_BlackBox_Data_req 0 "Default" 1 "Data Save Req (Isolation)" 2 "Data Set Clear" 3 "Error Indicator" ;
VAL_ 2344811011 xEV_12V_BatDchCurrLmt 255 "Error indicator" ;
VAL_ 2344811011 xEV_12VChargeReq 0 "Not Request(Normal)" 1 "Request" 2 "Not used" 3 "Error indicator" ;
VAL_ 2344811011 xEV_BmsRomType 0 "No Definition" 1 "Normal Battery Pack with Heater System" 2 "Normal Battery Pack without Heater System" 3 "Economy Battery Pack with Heater System" 4 "Economy Battery Pack without Heater System" 5 "Extented Battery Pack with Heater System" 6 "Extented Battery Pack without Heater System" 7 "Performance Battery Pack (Heater or Non Heater)" ;
VAL_ 2344811011 xEV_12V_CurrFltDetectReq 0 "Normal" 1 "Request" 2 "Not used" 3 "Error indicator" ;
VAL_ 2344811011 xEV_PRATempSnsVal_ 127 "Error indicator" ;
VAL_ 2344811011 xEV_PRATempSns2Val_ 127 "Error indicator" ;
VAL_ 2344811011 xEV_12VRlyOnSwReq 0 "Normal" 1 "Request" 2 "Not used" 3 "Error indicator" ;
VAL_ 2344811012 xEV_Bms_IsolDetDeactFuncSta 0 "Function disabled state" 1 "Functional activated state" 2 "Not used" 3 "Error indicator" ;
VAL_ 2344811012 xEV_Bms_CellBalDeactFuncSta 0 "Function disabled state" 1 "Functional activated state" 2 "Not used" 3 "Error indicator" ;
VAL_ 2344811012 xEV_BMS_SOC_2nd 65535 "Error Value" ;
VAL_ 733 USM_TurnDstLnDispSta 0 "Default" 1 "Off" 2 "On" 3 "Invalid" ;
VAL_ 733 USM_TurnDstLnDispStaRH 0 "Default" 1 "Off" 2 "On" 3 "Invalid" ;
VAL_ 733 USM_RhstaLvlEnaSta 0 "Default" 1 "Off" 2 "On" 3 "Invalid" ;
VAL_ 733 USM_RhstaLvlEnaStaRH 0 "Default" 1 "Off" 2 "On" 3 "Invalid" ;
VAL_ 733 USM_CMSDayBrgtnsLvlLHSta 0 "-5 Level" 1 "-4 Level" 2 "-3 Level" 3 "-2 Level" 4 "-1 Level" 5 "0 Level" 6 "1 Level" 7 "2 Level" 8 "3 Level" 9 "4 Level" 10 "5 Level" 11 "Not Used" 12 "Not Used" 13 "Not Used" 14 "Error Indicator" 15 "Invalid" ;
VAL_ 733 USM_CMSNgtBrgtnsLvlLHSta 0 "-5 Level" 1 "-4 Level" 2 "-3 Level" 3 "-2 Level" 4 "-1 Level" 5 "0 Level" 6 "1 Level" 7 "2 Level" 8 "3 Level" 9 "4 Level" 10 "5 Level" 11 "Not Used" 12 "Not Used" 13 "Not Used" 14 "Error Indicator" 15 "Invalid" ;
VAL_ 733 IMS_CMSPlayBackSta_LH 0 "Stop" 1 "Play 1" 2 "Play 2" 3 "Smart IMS" 4 "Profile 1" 5 "Profile 2" 6 "Guest" 7 "Invalid" ;
VAL_ 733 CMSFldReq 0 "Default" 1 "Folding Request" 2 "Unfolding Request" 3 "Invalid" ;
VAL_ 733 CMS_LH_FoldingSta 0 "Off" 1 "Folding" 2 "Not Used" 3 "Error Indicator" ;
VAL_ 733 CMS_LH_UnfoldingSta 0 "Off" 1 "Unfolding" 2 "Not Used" 3 "Error Indicator" ;
VAL_ 733 CMS_LHVerPosVal 251 "Reserved" 252 "Reserved" 253 "Reserved" 254 "Reserved" 255 "Error Indicator" ;
VAL_ 733 CMS_LHHorPosVal 251 "Reserved" 252 "Reserved" 253 "Reserved" 254 "Reserved" 255 "Error Indicator" ;
VAL_ 733 Monitor_ViewPanningCmd 0 "No Movement" 1 "Move Up" 2 "Move Down" 3 "Move Left" 4 "Move Right" ;
VAL_ 2365803009 DATC_SwVer1 0 "0x0x00~0x7E:ASCII value" 126 "0x0x00~0x7E:ASCII value" 127 "Invalid" ;
VAL_ 2365803009 DATC_SwVer2 0 "0x0x00~0x7E:ASCII value" 126 "0x0x00~0x7E:ASCII value" 127 "Invalid" ;
VAL_ 2365803009 DATC_SwVer3 0 "0x0x00~0x7E:ASCII value" 126 "0x0x00~0x7E:ASCII value" 127 "Invalid" ;
VAL_ 2365803009 DATC_Typ2 0 "0x0x00~0xFF: applied options (See Description)" 255 "0x0x00~0xFF: applied options (See Description)" ;
VAL_ 2365803010 DATC_SwVer4 0 "0x0x00~0x7E:ASCII value" 126 "0x0x00~0x7E:ASCII value" 127 "Invalid" ;
VAL_ 2365803010 DATC_SwVer5 0 "0x0x00~0x7E:ASCII value" 126 "0x0x00~0x7E:ASCII value" 127 "Invalid" ;
VAL_ 2193667331 ENG_TrgtIdleRpmVal 255 "Error indicator" ;
VAL_ 2193667331 ENG_GearShftDnDis 0 "Gear Shiftdown Display Off" 1 "Gear Shiftdown Display On" 2 "Not used" 3 "Error indicator" ;
VAL_ 2193667331 ENG_DsrGearPosDis 0 "No display" 1 "Gear Position 1 display" 2 "Gear Position 2 display" 3 "Gear Position 3 display" 4 "Gear Position 4 display" 5 "Gear Position 5 display" 6 "Gear Position 6 display" 7 "Gear Position 7 display" 8 "Gear Position 8 display" 9 "Gear Position 9 display" 10 "Gear Position 10 display" 15 "Error indicator" ;
VAL_ 2193667331 ENG_SldFuncSta 0 "Speed limiter function is not active" 1 "Speed limiter function is active" 2 "Not used" 3 "Error indicator" ;
VAL_ 2193667331 ENG_SldActnSta 0 "Positive action is not active" 1 "Positive action is active" 2 "Not used" 3 "Error indicator" ;
VAL_ 2193667331 ENG_FuelTnkPrsrSta 0 "Fuel Tank is not in high Pressure" 1 "Fuel Tank is in high Pressure" 2 "Not used" 3 "Error indicator" ;
VAL_ 2193667331 ENG_IsgBzrReq 0 "Request buzzer OFF" 1 "Request buzzer ON" 2 "Not used" 3 "Error indicator" ;
VAL_ 2193667331 ENG_IsgFuelCnsmptDis 0 "Not fuel consumption" 1 "Fuel consumption(=1mL)" 2 "Not used" 3 "Error indicator" ;
VAL_ 2193667331 ENG_FuelCapOpnSta 0 "Fuel cap isn't opened" 1 "Fuel cap is opened" 2 "Not used" 3 "Error indicator" ;
VAL_ 2193667331 ENG_EcoDrvActvSta 0 "Active Eco Drive is not active" 1 "Active Eco Drive is active" 2 "Not used" 3 "Error indicator" ;
VAL_ 2193667331 ENG_EngRunSta 0 "Engine Stop or Starting Phase" 1 "Engine Running" 2 "Not used" 3 "Error indicator" ;
VAL_ 2193667331 ENG_Isg2Sta 0 "Default" 1 "The condition for not-activated battery sensor. (Except EOL condition.)" 2 "In Auto Start status, when rapidly accelerating before complete gear shift. (Economy ISG Only)" 3 "Error indicator" ;
VAL_ 2193667331 ENG_IgnOnSta 0 "KEY OFF, control unit in self-holding phase" 1 "KEY ON" 2 "Not used" 3 "Error indicator" ;
VAL_ 2193667331 ENG_Ack4TcsSta 0 "TCS message not received within the last 500 ms, or a plausibility error in torque intervention is ON" 1 "TCS message received, and no plausibility error" 2 "Not used" 3 "Error indicator" ;
VAL_ 2193667331 ENG_FuelCutOffSta 0 "Engine not in fuel cut off" 1 "Engine in fuel cut off" 2 "Not used" 3 "Error indicator" ;
VAL_ 2193667331 ENG_CrctTqSta 0 "The desired intervention regarding ignition angle retardation and cylinder shut-off is executed. (Default value)" 1 "The desired intervention regarding ignition angle retardation and cylinder shut-off is executed; however, the requested target torque can not be adjusted precisely (torque steps)" 2 "The torque reduction regarding the ignition angle retardation cannot be completely executed. A cylinder shut-off is not possible at this time." 3 "Due to a failure detected the desired torque intervention for TCS regarding the ignition angle and cylinder shut-off is no longer executed." ;
VAL_ 2193667331 ENG_AirCompRlySta 0 "Air conditioner compressor relay OFF" 1 "Air conditioner compressor relay ON" 2 "Not used" 3 "Error indicator" ;
VAL_ 2193667331 ENG_LnchCntrlSta 0 "Off state" 1 "Standby" 2 "Ready" 3 "Lanch" 4 "Error indicator" ;
VAL_ 2193667331 ENG_GearShftUpDis 0 "Gear Shiftup Display Off" 1 "Gear Shiftup Display On" 2 "Not used" 3 "Error indicator" ;
VAL_ 2193667332 ENG_VehSpdHiVal 511 "Error indicator" ;
VAL_ 2193667332 ENG_EngInhbNCC 0 "NCC Inhibition OFF" 1 "NCC Inhibition ON" 2 "Not used" 3 "Error indicator" ;
VAL_ 2193667332 ENG_SldSwSta 0 "Speed limiter function is OFF" 1 "Speed limiter function is Active(Kickdown)" 2 "Speed limiter function is Pause" 3 "Error indicator" ;
VAL_ 2193667332 ENG_SldDrvAlertDisp 0 "Default" 1 "SldDisengaged" 2 "NoSldEngaged" 3 "ErrorIndicator" ;
VAL_ 2193667332 ENG_VehSpdLimVal 511 "Error indicator" ;
VAL_ 2307024129 EMS_Crc8Val 65535 "Signal Invalid (Message with unused CRC. CRC signal is transmitted fixed value)" ;
VAL_ 2307024129 EMS_AlvCnt8Val 255 "Signal Invalid (Message with unused Alive counter. Alive counter signal is transmitted fixed value)" ;
VAL_ 2307024129 HEV_VbOffActSta 0 "VB Off not Act" 1 "VB Off Act" 2 "Not used" 3 "Error indicator" ;
VAL_ 2307024129 HEV_AirCompOffReq 0 "none" 1 "off request" 2 "Not used" 3 "Error indicator" ;
VAL_ 2307024129 HEV_MilConfgVal 0 "No MIL" 1 "MIL/FMY treatment OBD1" 2 "MIL/FMY treatment OBD2" 3 "MIL/FMY treatment OBD2 (US)" 4 "MIL/FMY treatment EOBD" 5 "MIL/FMY treatment KOBD" ;
VAL_ 2307024129 HEV_CF_EMS_LOCKUP 0 "Request Off" 1 "Request On" ;
VAL_ 2307024129 HEV_OilLvlSta 0 "OIL LEVEL LAMP Off" 1 "OIL LEVEL LAMP On" 2 "Not used" 3 "Error indicator" ;
VAL_ 2307024129 HEV_ImmoLmpReq 0 "Off" 1 "Blink" 2 "On" 3 "Error indicator" ;
VAL_ 2307024129 HEV_MilReq 0 "Off" 1 "On" 2 "Not used" 3 "Error indicator" ;
VAL_ 2307024129 HEV_WiperSwSta 0 "Off" 1 "On" 2 "Not used" 3 "Error indicator" ;
VAL_ 2307024129 HEV_FanOpSta 0 "Off" 1 "On" 2 "Not used" 3 "Error indicator" ;
VAL_ 2307024129 HEV_FanSta 0 "Off" 1 "Low" 2 "Middle" 3 "High" ;
VAL_ 2307024129 HEV_BrkLtSwSta 0 "Not Support" 1 "Off" 2 "On" 3 "failure" ;
VAL_ 2307024130 HEV_SoakTimeErrSta 0 "No failure detected" 1 "Failure detected" 2 "Not used" 3 "Error indicator" ;
VAL_ 2307024130 HEV_SoakTimeOvrSta 0 "Engine soaking time < 360 min" 1 "Engine soaking time ¡Ã 360 min" 2 "Not used" 3 "Error indicator" ;
VAL_ 2307024130 HEV_FuelRunOutSta 0 "None" 1 "Fuel RunOut" 2 "Not used" 3 "Error indicator" ;
VAL_ 2307024130 HEV_FuelRunOutDetSta 0 "Inactive" 1 "Active" 2 "Not used" 3 "Error indicator" ;
VAL_ 2307024131 HEV_WarmUpReq_For_DATC 0 "Engine stop request" 1 "No engine stop request" ;
VAL_ 2307024131 HEV_RbmInhbtSta 0 "Enable of standardized vehicle operation and all numerators_denominators for RBM" 1 "Inhibition of standardized vehicle operation and all numerators_denominators for RBM" 2 "Not used" 3 "Error indicator" ;
VAL_ 2307024131 HEV_EhrsTempSta 0 "Normal" 1 "High" 3 "Fault" ;
VAL_ 2307024131 HEV_Aaf_WrnLamp 0 "Lamp OFF" 1 "Lamp ON" ;
VAL_ 2307024131 HEV_OPSFail 0 "Oil Pressure Warning Lamp OFF" 1 "Oil Pressure Warning Lamp ON" ;
VAL_ 2307024131 HEV_EngDsplceTyp 255 "Error indicator" ;
VAL_ 2307024131 HEV_EngTyp2 0 "LPI" 1 "MPI" 2 "GDI" 3 "TGDI" 4 "CVVL" 5 "CVVD" 6 "PDI" 7 "FFV" 8 "TCI" 9 "VGT" 10 "Turbo" 14 "Not used" 15 "Error indicator" ;
VAL_ 2307024131 HEV_EngTyp1 0 "epsilon(¥å)" 1 "gamma(¥ã)" 2 "kappa(¥ê)" 3 "theta(¥è)" 4 "nu(¥í)" 5 "lambda(¥ë)" 6 "tau(¥ó)" 10 "S" 11 "A" 12 "R" 13 "U" 14 "D" 15 "Error indicator" ;
VAL_ 2307024131 HEV_S_F 0 "AMS" 1 "ISG" 2 "Reserved" 3 "Reserved" ;
VAL_ 2307024131 HEV_S_F_GEN 0 "No AMS" 1 "1G Generation AMS" 2 "1.5G Generation AMS" 3 "2G Generation AMS" 4 "Reserved" 5 "Reserved" 6 "Reserved" 7 "Reserved" ;
VAL_ 2307024132 HEV_OilLifeRatio 1 "Engine oil life ratio with % unit" 2 "Engine oil life ratio with % unit" 3 "Engine oil life ratio with % unit" 4 "Engine oil life ratio with % unit" 5 "Engine oil life ratio with % unit" 6 "Engine oil life ratio with % unit" 7 "Engine oil life ratio with % unit" 8 "Engine oil life ratio with % unit" 9 "Engine oil life ratio with % unit" 10 "Engine oil life ratio with % unit" 11 "Engine oil life ratio with % unit" 12 "Engine oil life ratio with % unit" 13 "Engine oil life ratio with % unit" 14 "Engine oil life ratio with % unit" 15 "Engine oil life ratio with % unit" 16 "Engine oil life ratio with % unit" 17 "Engine oil life ratio with % unit" 18 "Engine oil life ratio with % unit" 19 "Engine oil life ratio with % unit" 20 "Engine oil life ratio with % unit" 21 "Engine oil life ratio with % unit" 22 "Engine oil life ratio with % unit" 23 "Engine oil life ratio with % unit" 24 "Engine oil life ratio with % unit" 25 "Engine oil life ratio with % unit" 26 "Engine oil life ratio with % unit" 27 "Engine oil life ratio with % unit" 28 "Engine oil life ratio with % unit" 29 "Engine oil life ratio with % unit" 30 "Engine oil life ratio with % unit" 31 "Engine oil life ratio with % unit" 32 "Engine oil life ratio with % unit" 33 "Engine oil life ratio with % unit" 34 "Engine oil life ratio with % unit" 35 "Engine oil life ratio with % unit" 36 "Engine oil life ratio with % unit" 37 "Engine oil life ratio with % unit" 38 "Engine oil life ratio with % unit" 39 "Engine oil life ratio with % unit" 40 "Engine oil life ratio with % unit" 41 "Engine oil life ratio with % unit" 42 "Engine oil life ratio with % unit" 43 "Engine oil life ratio with % unit" 44 "Engine oil life ratio with % unit" 45 "Engine oil life ratio with % unit" 46 "Engine oil life ratio with % unit" 47 "Engine oil life ratio with % unit" 48 "Engine oil life ratio with % unit" 49 "Engine oil life ratio with % unit" 50 "Engine oil life ratio with % unit" 51 "Engine oil life ratio with % unit" 52 "Engine oil life ratio with % unit" 53 "Engine oil life ratio with % unit" 54 "Engine oil life ratio with % unit" 55 "Engine oil life ratio with % unit" 56 "Engine oil life ratio with % unit" 57 "Engine oil life ratio with % unit" 58 "Engine oil life ratio with % unit" 59 "Engine oil life ratio with % unit" 60 "Engine oil life ratio with % unit" 61 "Engine oil life ratio with % unit" 62 "Engine oil life ratio with % unit" 63 "Engine oil life ratio with % unit" 64 "Engine oil life ratio with % unit" 65 "Engine oil life ratio with % unit" 66 "Engine oil life ratio with % unit" 67 "Engine oil life ratio with % unit" 68 "Engine oil life ratio with % unit" 69 "Engine oil life ratio with % unit" 70 "Engine oil life ratio with % unit" 71 "Engine oil life ratio with % unit" 72 "Engine oil life ratio with % unit" 73 "Engine oil life ratio with % unit" 74 "Engine oil life ratio with % unit" 75 "Engine oil life ratio with % unit" 76 "Engine oil life ratio with % unit" 77 "Engine oil life ratio with % unit" 78 "Engine oil life ratio with % unit" 79 "Engine oil life ratio with % unit" 80 "Engine oil life ratio with % unit" 81 "Engine oil life ratio with % unit" 82 "Engine oil life ratio with % unit" 83 "Engine oil life ratio with % unit" 84 "Engine oil life ratio with % unit" 85 "Engine oil life ratio with % unit" 86 "Engine oil life ratio with % unit" 87 "Engine oil life ratio with % unit" 88 "Engine oil life ratio with % unit" 89 "Engine oil life ratio with % unit" 90 "Engine oil life ratio with % unit" 91 "Engine oil life ratio with % unit" 92 "Engine oil life ratio with % unit" 93 "Engine oil life ratio with % unit" 94 "Engine oil life ratio with % unit" 95 "Engine oil life ratio with % unit" 96 "Engine oil life ratio with % unit" 97 "Engine oil life ratio with % unit" 98 "Engine oil life ratio with % unit" 99 "Engine oil life ratio with % unit" 100 "Engine oil life ratio with % unit" 101 "Not used" 102 "Not used" 103 "Not used" 104 "Not used" 105 "Not used" 106 "Not used" 107 "Not used" 108 "Not used" 109 "Not used" 110 "Not used" 111 "Not used" 112 "Not used" 113 "Not used" 114 "Not used" 115 "Not used" 116 "Not used" 117 "Not used" 118 "Not used" 119 "Not used" 120 "Not used" 121 "Not used" 122 "Not used" 123 "Not used" 124 "Not used" 125 "Not used" 126 "Not used" 127 "Error" ;
VAL_ 2307024132 HEV_OilLifeEna 0 "Oil life monitoring Not applied" 1 "Oil life monitoring Applied" 2 "Reserved" 3 "Error" ;
VAL_ 2307024132 HEV_OilLifeWarn 0 "No display" 1 "'Change engine oil' warning, 1st step (Low urgency)" 2 "'Change engine oil' warning, 2nd step (High urgency)" 3 "Oil change question based on oil temperature" 4 "Oil change confirm based on oil temperature" 5 "Reserved" 6 "Reserved" 7 "Error" ;
VAL_ 2307024132 HEV_RECTrigSta 0 "No detected" 1 "REC detected" ;
VAL_ 2307024132 HEV_PendingTrigSta 0 "No detected" 1 "Pending detected" ;
VAL_ 1189 C_RLTiltUpSw_HU 0 "Default" 1 "Off" 2 "On" 3 "Invalid" ;
VAL_ 1189 C_RRTiltDownSw_HU 0 "Default" 1 "Off" 2 "On" 3 "Invalid" ;
VAL_ 1189 C_RRTiltUpSw_HU 0 "Default" 1 "Off" 2 "On" 3 "Invalid" ;
VAL_ 1189 C_RLRclBwdSw_HU 0 "Default" 1 "Off" 2 "On" 3 "Invalid" ;
VAL_ 1189 C_RLRclFwdSw_HU 0 "Default" 1 "Off" 2 "On" 3 "Invalid" ;
VAL_ 1189 C_RLFldSw_HU 0 "Default" 1 "Off" 2 "On" 3 "Invalid" ;
VAL_ 1189 C_RRRclBwdSw_HU 0 "Default" 1 "Off" 2 "On" 3 "Invalid" ;
VAL_ 1189 C_RRRclFwdSw_HU 0 "Default" 1 "Off" 2 "On" 3 "Invalid" ;
VAL_ 1189 C_TLHrestFldSw_HU 0 "Default" 1 "Off" 2 "On" 3 "Invalid" ;
VAL_ 1189 C_TRHrestFldSw_HU 0 "default" 1 "OFF" 2 "ON" 3 "Invalid" ;
VAL_ 1189 C_RLRlxSW_HU 0 "Default" 1 "Off" 2 "On" 3 "Invalid" ;
VAL_ 1189 C_RRRlxSW_HU 0 "Default" 1 "Off" 2 "On" 3 "Invalid" ;
VAL_ 1189 C_TLFldSw_HU 0 "Default" 1 "Off" 2 "On" 3 "Invalid" ;
VAL_ 1189 C_TRFldSw_HU 0 "Default" 1 "Off" 2 "On" 3 "Invalid" ;
VAL_ 1189 C_RRFldSw_HU 0 "Default" 1 "Off" 2 "On" 3 "Invalid" ;
VAL_ 1189 C_RLTiltDownSw_HU 0 "Default" 1 "Off" 2 "On" 3 "Invalid" ;
VAL_ 1185 C_AstWindowCmdAVN 0 "No action" 1 "Manual Down" 2 "Manual Up" 3 "25% Open" 4 "50%Open" 5 "Auto Down" 6 "Auto Up" 7 "15% Open" 8 "Unused" 9 "Unused" 10 "Unused" 11 "Unused" 12 "Unused" 13 "Unused" 14 "Unused" 15 "Invalid" ;
VAL_ 1185 C_RrDefoggerCmdAVN 0 "Off" 1 "On" 2 "Reserved" 3 "Invalid" ;
VAL_ 1185 C_RrBlindCmdAVN 0 "No Action" 1 "Blind Auto Open" 2 "Blind Auto Close" 3 "Invalid" ;
VAL_ 1185 C_RrGlassCmdAVN 0 "No Action" 1 "Glass Auto Open" 2 "Glass Auto Close" 3 "Invalid" ;
VAL_ 1185 C_RRWindowCmdAVN 0 "No action" 1 "Manual Down" 2 "Manual Up" 3 "25% Open" 4 "50% Open" 5 "Auto Down" 6 "Auto Up" 7 "15% Open" 8 "Unused" 9 "Unused" 10 "Unused" 11 "Unused" 12 "Unused" 13 "Unused" 14 "Unused" 15 "Invalid" ;
VAL_ 1185 C_RLWindowCmdAVN 0 "No action" 1 "Manual Down" 2 "Manual Up" 3 "25% Open" 4 "50% Open" 5 "Auto Down" 6 "Auto UP" 7 "15% Open" 8 "Unused" 9 "Unused" 10 "Unused" 11 "Unused" 12 "Unused" 13 "Unused" 14 "Unused" 15 "Invalid" ;
VAL_ 1185 C_BlindCmdAVN 0 "No Action" 1 "R_Blind Auto Open" 2 "R_Blind Auto Close" 3 "Stop" 4 "reserved" 5 "reserved" 6 "reserved" 7 "Invalid" ;
VAL_ 1185 C_GlassCmdAVN 0 "No Action" 1 "Glass Auto Open" 2 "Glass Auto Close" 3 "Glass Auto Tilt Up" 4 "Stop" 5 "reserved" 6 "reserved" 7 "Invalid" ;
VAL_ 1185 C_DrvWindowCmdAVN 0 "No action" 1 "Manual Down" 2 "Manual Up" 3 "25% Open" 4 "50% Open" 5 "Auto Down" 6 "Auto Up" 7 "15% Open" 8 "Unused" 9 "Unused" 10 "Unused" 11 "Unused" 12 "Unused" 13 "Unused" 14 "Unused" 15 "Invalid" ;
VAL_ 1185 C_PTGCNTLCmdAVN 0 "Close" 1 "Open" 2 "Reserved" 3 "Invalid" ;
VAL_ 721 HU_DR_Position_Status 1 "Valid" ;
VAL_ 721 HU_DR_Altitude_Status 1 "valid" ;
VAL_ 721 HU_DR_Heading_Status 1 "Valid" ;
VAL_ 721 HU_DR_Speed_Status 1 "Valid" ;
VAL_ 721 HU_DR_DirectionSwitch_Sta 1 "Valid" ;
VAL_ 721 HU_DR_Direction 1 "Backward" ;
VAL_ 721 HU_DR_GyroCalib_Sta 1 "Calibrated" ;
VAL_ 721 HU_DR_TachoCalib_Sta 1 "Calibrated" ;
VAL_ 721 HU_DR_Solution_Sta 0 "invalid" 1 "DR valid" ;
VAL_ 721 HU_DR_GNSS_Fix_Age 1 "0x0x1~0xFE:time since last GNSS fix" 254 "0x0x1~0xFE:time since last GNSS fix" 255 "No GNSS fix yet" ;
VAL_ 1186 C_RemoteWdwCMDHU 0 "None" 1 "Auto Up" 2 "Auto Down" 3 "invalid" ;
VAL_ 1186 HU_CDMOpenCmd 0 "Default" 1 "CDM Open" 2 "CDM Close" 3 "Invalid" ;
VAL_ 1186 C_PreCrankReq 0 "Default" 1 "Req On" 2 "Not Support" 3 "Invalid" ;
VAL_ 1186 C_TeleAstSeatOpCmdIBOX 0 "Init" 1 "Unused" 2 "Seat Heat&Vent OFF" 3 "Seat_Vent_Low" 4 "Seat_Vent_Mid" 5 "Seat_Vent_High" 6 "Seat_Heat_Low" 7 "Seat_Heat_Mid" 8 "Seat_Heat_High" 9 "Unused" 10 "Unused" 11 "Unused" 12 "Unused" 13 "Unused" 14 "Unused" 15 "Invalid" ;
VAL_ 1186 C_TeleDrvSeatOpCmdIBOX 0 "Init" 1 "Unused" 2 "Seat Heat&Vent OFF" 3 "Seat_Vent_Low" 4 "Seat_Vent_Mid" 5 "Seat_Vent_High" 6 "Seat_Heat_Low" 7 "Seat_Heat_Mid" 8 "Seat_Heat_High" 9 "Unused" 10 "Unused" 11 "Unused" 12 "Unused" 13 "Unused" 14 "Unused" 15 "Invalid" ;
VAL_ 1186 C_TeleRRSeatOpCmdIBOX 0 "Init" 1 "Unused" 2 "Seat Heat&Vent OFF" 3 "Seat_Vent_Low" 4 "Seat_Vent_Mid" 5 "Seat_Vent_High" 6 "Seat_Heat_Low" 7 "Seat_Heat_Mid" 8 "Seat_Heat_High" 9 "Unused" 10 "Unused" 11 "Unused" 12 "Unused" 13 "Unused" 14 "Unused" 15 "Invalid" ;
VAL_ 1186 C_TeleRLSeatOpCmdIBOX 0 "Init" 1 "Unused" 2 "Seat Heat&Vent OFF" 3 "Seat_Vent_Low" 4 "Seat_Vent_Mid" 5 "Seat_Vent_High" 6 "Seat_Heat_Low" 7 "Seat_Heat_Mid" 8 "Seat_Heat_High" 9 "Unused" 10 "Unused" 11 "Unused" 12 "Unused" 13 "Unused" 14 "Unused" 15 "Invalid" ;
VAL_ 1193 C_PTGMNValueSet 0 "Default" 1 "Power Mode" 2 "Manual Mode" 3 "Invalid" ;
VAL_ 1193 CF_AVN_PSMNValueSet 0 "Default" 1 "Off(Disable)" 2 "50mm On(Enable)" 3 "75mm On(Enable)" 4 "Reserved" 5 "Reserved" 6 "Reserved" 7 "Invalid" ;
VAL_ 1193 C_HfreeTrunkTgNValueSet 0 "Default" 1 "HandsFree Off" 2 "HandsFree On" 3 "Reserved" 4 "Invalid" 5 "Reserved" 6 "Reserved" 7 "Reserved" ;
VAL_ 1193 CF_AVN_TrfChgSet 0 "Default" 1 "Disable(Off)" 2 "Enable(On)" 3 "Invalid" ;
VAL_ 1193 CF_AVN_SCMNValueSet 0 "Default" 1 "Steering Off" 2 "Steering On" 3 "Invalid" ;
VAL_ 1193 CF_AVN_ADrUNValueSet 0 "Default" 1 "Off" 2 "Key Out On(All Doors)" 3 "Shift Lever On(All Doors)" 4 "Override" 5 "Invalid" 6 "Key Out On(Driver Door)" 7 "Shift Lever On(Driver Door)" ;
VAL_ 1193 CF_AVN_OTTurnNValueSet 0 "Default" 1 "One Touch Turn Off" 2 "3 Flashing" 3 "5 Flashing" 4 "7 Flashing" 5 "Invalid" 6 "Reserved" 7 "Reserved" ;
VAL_ 1193 CF_Gway_WPCNValueSet 0 "Default" 1 "Off(Disable)" 2 "On(Enable)" 3 "Invalid" ;
VAL_ 1193 C_AVN_RearWiperNValueSet 0 "Default" 1 "Rear Wiper(Reverse) Off" 2 "Rear Wiper(Reverse) On" 3 "Invalid" ;
VAL_ 1193 C_UnlockWelocomeNValueSet 0 "Default" 1 "Off" 2 "On" 3 "Invalid" ;
VAL_ 1193 C_SmartWelocomeNValueSet 0 "Default" 1 "Off" 2 "On" 3 "Invalid" ;
VAL_ 1193 CF_AVN_PTGSpeedNValueSet 0 "Default" 1 "Fast" 2 "Slow" 3 "Invalid" ;
VAL_ 1193 CR_Datc_DRSeatWheel_USM_Set 0 "Default" 1 "Off" 2 "On" 3 "Invalid" ;
VAL_ 1193 CF_AVN_TTUnlockNValueSet 0 "Default" 1 "Off" 2 "On" 3 "Invalid" ;
VAL_ 1193 CF_Gway_RWPCNValueSet 0 "Default" 1 "Off" 2 "On" 3 "Invalid" ;
VAL_ 1193 C_PSDNValueSet 0 "Default" 1 "Power Mode" 2 "Manual Mode" 3 "Invalid" ;
VAL_ 1193 CF_Avn_HAPTICWARNINGNValueSet 0 "Default" 1 "Weak" 2 "Medium" 3 "Strong" 4 "Reserved" 5 "Reserved" 6 "Off" 7 "Invalid" ;
VAL_ 1193 CR_Datc_DRSeatHeat_USM_Set 0 "Default" 1 "Off" 2 "On" 3 "Invalid" ;
VAL_ 1193 C_WALNValueSet 0 "Default" 1 "Off" 2 "On" 3 "Invalid" ;
VAL_ 1193 C_ApprUnlockNValue 0 "Defualt" 1 "Approach Unlock OFF" 2 "Approach Unlock ON" 3 "Invalid" ;
VAL_ 1193 CF_AVN_EscortHLNValueSet 0 "Default" 1 "Escort Off" 2 "Escort On" 3 "Invalid" ;
VAL_ 1195 CF_AVN_CluWelcomeSnd 0 "Default" 1 "Off" 2 "On" 3 "Invalid" ;
VAL_ 1195 CF_AVN_CluTransmissionDisp 0 "Default" 1 "Off" 2 "On" 3 "Invalid" ;
VAL_ 1195 CF_AVN_CluWiperLight 0 "Default" 1 "Off" 2 "On" 3 "Invalid" ;
VAL_ 1195 CF_AVN_CluRoadInfoGuide 0 "Default" 1 "Off" 2 "On" 3 "Invalid" ;
VAL_ 1195 CF_AVN_CluUserSettingPeriod 0 "0~99month" 1 "0~99month" 2 "0~99month" 3 "0~99month" 4 "0~99month" 5 "0~99month" 6 "0~99month" 7 "0~99month" 8 "0~99month" 9 "0~99month" 10 "0~99month" 11 "0~99month" 12 "0~99month" 13 "0~99month" 14 "0~99month" 15 "0~99month" 16 "0~99month" 17 "0~99month" 18 "0~99month" 19 "0~99month" 20 "0~99month" 21 "0~99month" 22 "0~99month" 23 "0~99month" 24 "0~99month" 25 "0~99month" 26 "0~99month" 27 "0~99month" 28 "0~99month" 29 "0~99month" 30 "0~99month" 31 "0~99month" 32 "0~99month" 33 "0~99month" 34 "0~99month" 35 "0~99month" 36 "0~99month" 37 "0~99month" 38 "0~99month" 39 "0~99month" 40 "0~99month" 41 "0~99month" 42 "0~99month" 43 "0~99month" 44 "0~99month" 45 "0~99month" 46 "0~99month" 47 "0~99month" 48 "0~99month" 49 "0~99month" 50 "0~99month" 51 "0~99month" 52 "0~99month" 53 "0~99month" 54 "0~99month" 55 "0~99month" 56 "0~99month" 57 "0~99month" 58 "0~99month" 59 "0~99month" 60 "0~99month" 61 "0~99month" 62 "0~99month" 63 "0~99month" 64 "0~99month" 65 "0~99month" 66 "0~99month" 67 "0~99month" 68 "0~99month" 69 "0~99month" 70 "0~99month" 71 "0~99month" 72 "0~99month" 73 "0~99month" 74 "0~99month" 75 "0~99month" 76 "0~99month" 77 "0~99month" 78 "0~99month" 79 "0~99month" 80 "0~99month" 81 "0~99month" 82 "0~99month" 83 "0~99month" 84 "0~99month" 85 "0~99month" 86 "0~99month" 87 "0~99month" 88 "0~99month" 89 "0~99month" 90 "0~99month" 91 "0~99month" 92 "0~99month" 93 "0~99month" 94 "0~99month" 95 "0~99month" 96 "0~99month" 97 "0~99month" 98 "0~99month" 99 "0~99month" 100 "Reserved" 101 "Reserved" 102 "Reserved" 103 "Reserved" 104 "Reserved" 105 "Reserved" 106 "Reserved" 107 "Reserved" 108 "Reserved" 109 "Reserved" 110 "Reserved" 111 "Reserved" 112 "Reserved" 113 "Reserved" 114 "Reserved" 115 "Reserved" 116 "Reserved" 117 "Reserved" 118 "Reserved" 119 "Reserved" 120 "Reserved" 121 "Reserved" 122 "Reserved" 123 "Reserved" 124 "Reserved" 125 "Reserved" 126 "Reserved" 127 "Invalid" ;
VAL_ 1195 CF_AVN_CluAutoInitFuelEconomy 0 "Default" 1 "Off" 2 "Driving" 3 "Refuel" 4 "Reserved" 5 "Reserved" 6 "Reserved" 7 "Invalid" ;
VAL_ 1195 CF_AVN_CluFuelEconUnit_mi 0 "Default" 1 "US gallon" 2 "UK gallon" 3 "Reserved" ;
VAL_ 1195 CF_AVN_CluFuelEconUnit_km 0 "Default" 1 "km/L, km/kg, km/kWh" 2 "L/100km, kg/100km, kWh/100km" 3 "Reserved" ;
VAL_ 1195 CF_AVN_CluUserSettingDistance 0 "0x0x0~0x1869F:0~9999km_mi" 99999 "0x0x0~0x1869F:0~9999km_mi" 131071 "Invalid" ;
VAL_ 1195 CF_AVN_CluRheostatLvl 0 "Reserved" 1 "Step 1" 2 "Step 2" 3 "Step 3" 4 "Step 4" 5 "Step 5" 6 "Step 6" 7 "Step 7" 8 "Step 8" 9 "Step 9" 10 "Step 10" 11 "Step 11" 12 "Step 12" 13 "Step 13" 14 "Step 14" 15 "Step 15" 16 "Step 16" 17 "Step 17" 18 "Step 18" 19 "Step 19" 20 "Step 20(Reset Value)" 21 "Step 21(Detent)" 22 "Reserved" 23 "Reserved" 24 "Reserved" 25 "Reserved" 26 "Reserved" 27 "Reserved" 28 "Reserved" 29 "Reserved" 30 "Reserved" 31 "Invalid" ;
VAL_ 1195 CF_AVN_CluVoiceVolume 0 "Default" 1 "Level0" 2 "Level1" 3 "Level2" 4 "Level3" 5 "Reserved" 6 "Reserved" 7 "Invalid" ;
VAL_ 1195 CF_AVN_EVReset 0 "Default" 1 "USM Reset" 2 "Reserved" 3 "Invalid" ;
VAL_ 1195 CF_AVN_UnitReset 0 "Default" 1 "Unit Reset" 2 "Reserved" 3 "Invalid" ;
VAL_ 1195 CF_AVN_IcyRoadWarn 0 "Default" 1 "Off" 2 "On" 3 "Invalid" ;
VAL_ 1195 CF_AVN_CluServiceReminderReset 0 "Default" 1 "Service Reminder Reset" 2 "Reserved" 3 "Invalid" ;
VAL_ 1195 CF_AVN_CluUSMReset 0 "Default" 1 "USM Reset" 2 "Reserved" 3 "Invalid" ;
VAL_ 1195 CF_AVN_CluServiceReminderSet 0 "Default" 1 "Off" 2 "On" 3 "Invalid" ;
VAL_ 1196 C_HCIMSWeightNValueSet 0 "Default" 1 "Under 49.4kg" 2 "49.5~59.4kg" 3 "59.5~69.4kg" 4 "69.5~79.4kg" 5 "79.5~89.4kg" 6 "89.5~99.4kg" 7 "99.5~109.4kg" 8 "109.5~119.4kg" 9 "More than 119.5kg" 10 "Reserved" 11 "Reserved" 12 "Reserved" 13 "Reserved" 14 "Reserved" 15 "Invalid" ;
VAL_ 1196 C_HCIMSSitHeightNValueSet 0 "Default" 1 "Tall" 2 "Middle" 3 "Short" 4 "Reserved" 5 "Reserved" 6 "Reserved" 7 "Reserved" 8 "Reserved" 9 "Reserved" 10 "Reserved" 11 "Reserved" 12 "Reserved" 13 "Reserved" 14 "Reserved" 15 "Invalid" ;
VAL_ 1196 CF_AVN_BodySpprtSet 0 "Default" 1 "Off" 2 "On" 3 "Invalid" ;
VAL_ 1196 CF_AVN_AirSptTimeNValueSet 0 "Default" 1 "Short" 2 "Normal" 3 "Long" 4 "Reserved" 5 "Reserved" 6 "Reserved" 7 "Invalid" ;
VAL_ 1196 CF_AVN_AirSptStrNValue 0 "Default" 1 "Normal" 2 "Intense" 3 "Invalid" ;
VAL_ 1196 CF_AVN_SeatDrvModNValueSet 0 "Default" 1 "Off" 2 "On" 3 "Invalid" ;
VAL_ 1196 C_HCIMSHeightNvalueSet 0 "Default" 1 "Less than 147.5cm" 2 "147.5~152.4cm" 3 "152.5~157.4cm" 4 "157.5~162.4cm" 5 "162.5~167.4cm" 6 "167.5~172.4cm" 7 "172.5~177.4cm" 8 "177.5~182.4cm" 9 "182.5~187.4cm" 10 "187.5~192.4cm" 11 "192.5~197.4cm" 12 "more than 197.5cm" 13 "Reserved" 14 "Reserved" 15 "Invalid" ;
VAL_ 1196 C_SLB_SmartCtrl_NValue 0 "Init" 1 "Disable" 2 "Enable" 3 "Invalid" ;
VAL_ 1196 CF_AVN_CushSoftNValueSet 0 "Default" 1 "Soft" 2 "Mid" 3 "Hard" 4 "Reserved" 5 "Reserved" 6 "Off" 7 "Invalid" ;
VAL_ 1196 C_SmrtSldngDrNValueSet 0 "Default" 1 "Off" 2 "On" 3 "Reserved" 4 "Reserved" 5 "Reserved" 6 "Reserved" 7 "Invalid" ;
VAL_ 1196 CF_AVN_TurboPressureUnit 0 "Default" 1 "Psi" 2 "kPa" 3 "bar" 4 "Reserved" 5 "Reserved" 6 "Reserved" 7 "Invalid" ;
VAL_ 1196 CF_AVN_CluTorqueUnit 0 "Default" 1 "Nm" 2 "lb_ft" 3 "Invalid" ;
VAL_ 1196 AVN_Usm_CluFuelEconomySet 0 "Default" 1 "Off" 2 "After Ignition" 3 "After Refueling" 4 "Accumulated Fuel Economy" 5 "Reserved" 6 "Reserved" 7 "Invalid" ;
VAL_ 1196 CF_AVN_HCIMSButtonCommand 0 "Default" 1 "Health Care IMS Exit" 2 "Detail View" 3 "Move to recommend position" 4 "Current position Analysis" 5 "Move to setting page" 6 "Save view" 7 "IMS1 saved" 8 "IMS2 saved" 9 "Summary view" 10 "Smart IMS On" 11 "Reserved" 12 "Reserved" 13 "Reserved" 14 "Reserved" 15 "Invalid" ;
VAL_ 830 USM_CmdWPC2Sta 0 "Default" 1 "Off(Disable)" 2 "On(Enable)" 3 "Invalid" ;
VAL_ 830 WPC2_SWVerMajor1 0 "0x0x0~0x7F:ASCII Code Value (HEX)" 127 "0x0x0~0x7F:ASCII Code Value (HEX)" ;
VAL_ 830 WPC2_PhnLftWrngSta 0 "Off" 1 "Cellphone on the pad" 2 "Charging" 3 "Charging complete" 4 "Cellphone reminder" 5 "Error" 6 "Reserved" 7 "Invalid" ;
VAL_ 830 WPC2_SWVerMinor1 0 "0x0x0~0x7F:ASCII Code Value (HEX)" 127 "0x0x0~0x7F:ASCII Code Value (HEX)" ;
VAL_ 830 WPC2_SWVerMinor2 0 "0x0x0~0x7F:ASCII Code Value (HEX)" 127 "0x0x0~0x7F:ASCII Code Value (HEX)" ;
VAL_ 830 WPC2_NFCDeviceDetSta 0 "Off(NFC turned off)" 1 "Detected" 2 "Not Detected" 3 "Reserved" 4 "Reserved" 5 "Reserved" 6 "Reserved" 7 "Reserved" 8 "Reserved" 9 "Reserved" 10 "Reserved" 11 "Reserved" 12 "Reserved" 13 "Reserved" 14 "Reserved" 15 "Invalid" ;
